VERSION "HNNBNNNYNNNNNNNNNNNNNNNNNNNNNNNNNNNNNNNNNN/4/%%%/4/'%**4NNN///"

NS_ :

BS_:

BU_: BAP_Tester FASFrontradar ICAS1_X_Gateway MFK MFK120 MIK MRR2023 NR_1 NR_2

BO_ 997 TSG_FT_02: 8 ICAS1_X_Gateway
 SG_ TSG_FT_02_CRC : 0|8@1+ (1,0) [0|255] ""  FASFrontradar,MRR2023
 SG_ TSG_FT_02_BZ : 8|4@1+ (1,0) [0|15] ""  FASFrontradar,MRR2023
 SG_ FT_Tuer_Status : 12|2@1+ (1.0,0.0) [0.0|3] ""  FASFrontradar,MFK,MFK120,MIK,MRR2023
 SG_ FT_Tuer_Status_QBit : 14|1@1+ (1.0,0.0) [0.0|1] ""  MFK,MFK120
 SG_ FT_Lock_Taster_02 : 15|1@1+ (1.0,0.0) [0.0|1] ""  Vector__XXX
 SG_ FT_Schluesselschalter_zu_02 : 16|1@1+ (1.0,0.0) [0.0|1] ""  Vector__XXX
 SG_ FT_BFS_Tuer_Status : 17|2@1+ (1.0,0.0) [0.0|3] ""  Vector__XXX
 SG_ FT_HBFS_Tuer_Status : 19|2@1+ (1.0,0.0) [0.0|3] ""  Vector__XXX
 SG_ FT_HFS_Tuer_Status : 21|2@1+ (1.0,0.0) [0.0|3] ""  Vector__XXX
 SG_ FT_Tueroeffnen_Warnung : 23|1@1+ (1.0,0.0) [0.0|1] ""  Vector__XXX
 SG_ FT_SP_Heizung_ein : 24|1@1+ (1.0,0.0) [0.0|1] ""  Vector__XXX
 SG_ FT_Kisi_Taster_li_02 : 25|1@1+ (1.0,0.0) [0.0|1] ""  Vector__XXX
 SG_ FT_Kisi_Taster_re_02 : 26|1@1+ (1.0,0.0) [0.0|1] ""  Vector__XXX
 SG_ FT_TD_Taste_Status : 27|2@1+ (1.0,0.0) [0.0|3] ""  Vector__XXX
 SG_ FT_TCR_Mode_aktiv : 29|1@1+ (1.0,0.0) [0.0|1] ""  Vector__XXX
 SG_ TBF_FS_Touch_Event : 30|4@1+ (1.0,0.0) [0.0|15] ""  Vector__XXX
 SG_ FT_KiSi_Status_Soll_HBFS : 34|1@1+ (1.0,0.0) [0.0|1] ""  Vector__XXX
 SG_ FT_KiSi_Status_Soll_HFS : 35|1@1+ (1.0,0.0) [0.0|1] ""  Vector__XXX
 SG_ FS_Push_Tuergriff : 36|1@1+ (1.0,0.0) [0.0|1] ""  Vector__XXX
 SG_ TSG_FS_Spiegel_angeklappt : 37|1@1+ (1.0,0.0) [0.0|1] ""  Vector__XXX
 SG_ FT_Cargolock_bet : 38|1@1+ (1.0,0.0) [0.0|1] ""  Vector__XXX
 SG_ FT_kisi_asynchron : 40|1@1+ (1.0,0.0) [0.0|1] ""  Vector__XXX
 SG_ FS_Status_eTAG_ext : 42|3@1+ (1.0,0.0) [0.0|7] ""  Vector__XXX
 SG_ FT_ASW_Warnton : 45|2@1+ (1.0,0.0) [0.0|3] ""  Vector__XXX
 SG_ SSA_FT_ASW_Status : 47|2@1+ (1.0,0.0) [0.0|3] ""  Vector__XXX

BO_ 1019 TSK_Ausrollkurve_01: 8 ICAS1_X_Gateway
 SG_ TSK_Ausrollkurve_Schub_Reku_01 m0  : 0|7@1+ (2,0) [0|252] "Unit_KiloMeterPerHour"  FASFrontradar,MRR2023
 SG_ TSK_Ausrollkurve_Schub_Reku_05 m1  : 0|7@1+ (2,0) [0|252] "Unit_KiloMeterPerHour"  FASFrontradar,MRR2023
 SG_ TSK_Ausrollkurve_Schub_Reku_09 m2  : 0|7@1+ (2,0) [0|252] "Unit_KiloMeterPerHour"  FASFrontradar,MRR2023
 SG_ TSK_Ausrollkurve_Schub_Reku_13 m3  : 0|7@1+ (2,0) [0|252] "Unit_KiloMeterPerHour"  FASFrontradar,MRR2023
 SG_ TSK_Ausrollkurve_Schub_Reku_17 m4  : 0|7@1+ (2,0) [0|252] "Unit_KiloMeterPerHour"  FASFrontradar,MRR2023
 SG_ TSK_Ausrollkurve_Schub_Reku_02 m0  : 7|7@1+ (2,0) [0|252] "Unit_KiloMeterPerHour"  FASFrontradar,MRR2023
 SG_ TSK_Ausrollkurve_Schub_Reku_06 m1  : 7|7@1+ (2,0) [0|252] "Unit_KiloMeterPerHour"  FASFrontradar,MRR2023
 SG_ TSK_Ausrollkurve_Schub_Reku_10 m2  : 7|7@1+ (2,0) [0|252] "Unit_KiloMeterPerHour"  FASFrontradar,MRR2023
 SG_ TSK_Ausrollkurve_Schub_Reku_14 m3  : 7|7@1+ (2,0) [0|252] "Unit_KiloMeterPerHour"  FASFrontradar,MRR2023
 SG_ TSK_Ausrollkurve_Schub_Reku_18 m4  : 7|7@1+ (2,0) [0|252] "Unit_KiloMeterPerHour"  FASFrontradar,MRR2023
 SG_ TSK_Ausrollkurve_Schub_Reku_03 m0  : 14|7@1+ (2,0) [0|252] "Unit_KiloMeterPerHour"  FASFrontradar,MRR2023
 SG_ TSK_Ausrollkurve_Schub_Reku_07 m1  : 14|7@1+ (2,0) [0|252] "Unit_KiloMeterPerHour"  FASFrontradar,MRR2023
 SG_ TSK_Ausrollkurve_Schub_Reku_11 m2  : 14|7@1+ (2,0) [0|252] "Unit_KiloMeterPerHour"  FASFrontradar,MRR2023
 SG_ TSK_Ausrollkurve_Schub_Reku_15 m3  : 14|7@1+ (2,0) [0|252] "Unit_KiloMeterPerHour"  FASFrontradar,MRR2023
 SG_ TSK_Ausrollkurve_Schub_Reku_19 m4  : 14|7@1+ (2,0) [0|252] "Unit_KiloMeterPerHour"  FASFrontradar,MRR2023
 SG_ TSK_Ausrollkurve_Schub_Reku_04 m0  : 21|7@1+ (2,0) [0|252] "Unit_KiloMeterPerHour"  FASFrontradar,MRR2023
 SG_ TSK_Ausrollkurve_Schub_Reku_08 m1  : 21|7@1+ (2,0) [0|252] "Unit_KiloMeterPerHour"  FASFrontradar,MRR2023
 SG_ TSK_Ausrollkurve_Schub_Reku_12 m2  : 21|7@1+ (2,0) [0|252] "Unit_KiloMeterPerHour"  FASFrontradar,MRR2023
 SG_ TSK_Ausrollkurve_Schub_Reku_16 m3  : 21|7@1+ (2,0) [0|252] "Unit_KiloMeterPerHour"  FASFrontradar,MRR2023
 SG_ TSK_Ausrollkurve_Schub_Reku_20 m4  : 21|7@1+ (2,0) [0|252] "Unit_KiloMeterPerHour"  FASFrontradar,MRR2023
 SG_ TSK_Ausrollkurve_Segeln_01 m0  : 28|7@1+ (2,0) [0|252] "Unit_KiloMeterPerHour"  FASFrontradar,MRR2023
 SG_ TSK_Ausrollkurve_Segeln_05 m1  : 28|7@1+ (2,0) [0|252] "Unit_KiloMeterPerHour"  FASFrontradar,MRR2023
 SG_ TSK_Ausrollkurve_Segeln_09 m2  : 28|7@1+ (2,0) [0|252] "Unit_KiloMeterPerHour"  FASFrontradar,MRR2023
 SG_ TSK_Ausrollkurve_Segeln_13 m3  : 28|7@1+ (2,0) [0|252] "Unit_KiloMeterPerHour"  FASFrontradar,MRR2023
 SG_ TSK_Ausrollkurve_Segeln_17 m4  : 28|7@1+ (2,0) [0|252] "Unit_KiloMeterPerHour"  FASFrontradar,MRR2023
 SG_ TSK_Ausrollkurve_Segeln_02 m0  : 35|7@1+ (2,0) [0|252] "Unit_KiloMeterPerHour"  FASFrontradar,MRR2023
 SG_ TSK_Ausrollkurve_Segeln_06 m1  : 35|7@1+ (2,0) [0|252] "Unit_KiloMeterPerHour"  FASFrontradar,MRR2023
 SG_ TSK_Ausrollkurve_Segeln_10 m2  : 35|7@1+ (2,0) [0|252] "Unit_KiloMeterPerHour"  FASFrontradar,MRR2023
 SG_ TSK_Ausrollkurve_Segeln_14 m3  : 35|7@1+ (2,0) [0|252] "Unit_KiloMeterPerHour"  FASFrontradar,MRR2023
 SG_ TSK_Ausrollkurve_Segeln_18 m4  : 35|7@1+ (2,0) [0|252] "Unit_KiloMeterPerHour"  FASFrontradar,MRR2023
 SG_ TSK_Ausrollkurve_Segeln_03 m0  : 42|7@1+ (2,0) [0|252] "Unit_KiloMeterPerHour"  FASFrontradar,MRR2023
 SG_ TSK_Ausrollkurve_Segeln_07 m1  : 42|7@1+ (2,0) [0|252] "Unit_KiloMeterPerHour"  FASFrontradar,MRR2023
 SG_ TSK_Ausrollkurve_Segeln_11 m2  : 42|7@1+ (2,0) [0|252] "Unit_KiloMeterPerHour"  FASFrontradar,MRR2023
 SG_ TSK_Ausrollkurve_Segeln_15 m3  : 42|7@1+ (2,0) [0|252] "Unit_KiloMeterPerHour"  FASFrontradar,MRR2023
 SG_ TSK_Ausrollkurve_Segeln_19 m4  : 42|7@1+ (2,0) [0|252] "Unit_KiloMeterPerHour"  FASFrontradar,MRR2023
 SG_ TSK_Ausrollkurve_Segeln_04 m0  : 49|7@1+ (2,0) [0|252] "Unit_KiloMeterPerHour"  FASFrontradar,MRR2023
 SG_ TSK_Ausrollkurve_Segeln_08 m1  : 49|7@1+ (2,0) [0|252] "Unit_KiloMeterPerHour"  FASFrontradar,MRR2023
 SG_ TSK_Ausrollkurve_Segeln_12 m2  : 49|7@1+ (2,0) [0|252] "Unit_KiloMeterPerHour"  FASFrontradar,MRR2023
 SG_ TSK_Ausrollkurve_Segeln_16 m3  : 49|7@1+ (2,0) [0|252] "Unit_KiloMeterPerHour"  FASFrontradar,MRR2023
 SG_ TSK_Ausrollkurve_Segeln_20 m4  : 49|7@1+ (2,0) [0|252] "Unit_KiloMeterPerHour"  FASFrontradar,MRR2023
 SG_ TSK_Ausrollkurve_Mux M  : 56|3@1+ (1,0) [0|7] ""  FASFrontradar,MRR2023
 SG_ TSK_Ausrollkurve_Reku : 59|1@1+ (1.0,0.0) [0.0|1] ""  FASFrontradar,MRR2023
 SG_ TSK_Ausrollkurve_Schrittweite : 60|1@1+ (1.0,0.0) [0.0|1] ""  FASFrontradar,MRR2023
 SG_ TSK_Ausrollkurve_Zaehler : 61|2@1+ (1,0) [0|3] ""  FASFrontradar,MRR2023

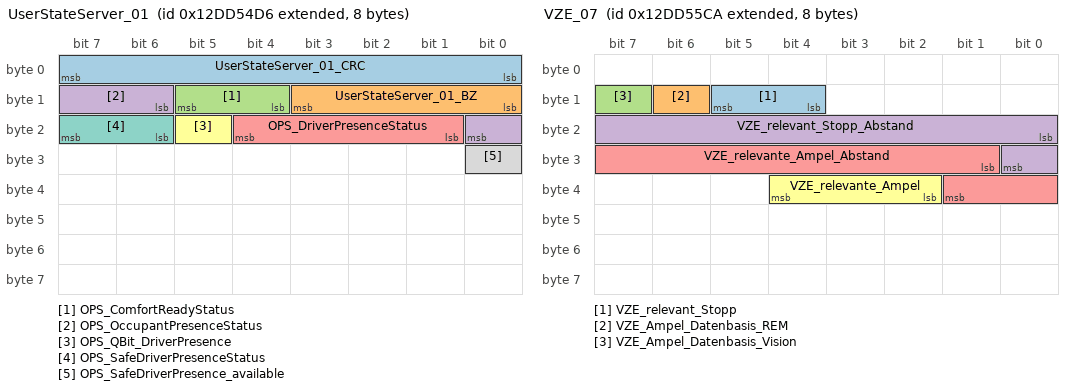
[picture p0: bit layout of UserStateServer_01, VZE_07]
BO_ 2463978710 UserStateServer_01: 8 ICAS1_X_Gateway
 SG_ UserStateServer_01_CRC : 0|8@1+ (1,0) [0|255] ""  Vector__XXX
 SG_ UserStateServer_01_BZ : 8|4@1+ (1,0) [0|15] ""  Vector__XXX
 SG_ OPS_ComfortReadyStatus : 12|2@1+ (1.0,0.0) [0.0|3] ""  Vector__XXX
 SG_ OPS_OccupantPresenceStatus : 14|3@1+ (1.0,0.0) [0.0|7] ""  Vector__XXX
 SG_ OPS_DriverPresenceStatus : 17|4@1+ (1.0,0.0) [0.0|15] ""  MFK,MFK120
 SG_ OPS_QBit_DriverPresence : 21|1@1+ (1.0,0.0) [0.0|1] ""  Vector__XXX
 SG_ OPS_SafeDriverPresenceStatus : 22|2@1+ (1.0,0.0) [0.0|3] ""  MFK,MFK120
 SG_ OPS_SafeDriverPresence_available : 24|1@1+ (1.0,0.0) [0.0|1] ""  Vector__XXX

BO_ 1716 VIN_01: 8 ICAS1_X_Gateway
 SG_ VIN_01_MUX M  : 0|2@1+ (1,0) [0|3] ""  FASFrontradar,MFK,MFK120,MIK,MRR2023
 SG_ KS_Geheimnis_1 m0  : 8|8@1+ (1,0) [0|255] ""  FASFrontradar
 SG_ VIN_4 m1  : 8|8@1+ (1,0) [0|255] ""  FASFrontradar,MFK,MFK120,MIK,MRR2023
 SG_ VIN_11 m2  : 8|8@1+ (1,0) [0|255] ""  FASFrontradar,MFK,MFK120,MIK,MRR2023
 SG_ KS_Geheimnis_2 m0  : 16|8@1+ (1,0) [0|255] ""  FASFrontradar
 SG_ VIN_5 m1  : 16|8@1+ (1,0) [0|255] ""  FASFrontradar,MFK,MFK120,MIK,MRR2023
 SG_ VIN_12 m2  : 16|8@1+ (1,0) [0|255] ""  FASFrontradar,MFK,MFK120,MIK,MRR2023
 SG_ KS_Geheimnis_3 m0  : 24|8@1+ (1,0) [0|255] ""  FASFrontradar
 SG_ VIN_6 m1  : 24|8@1+ (1,0) [0|255] ""  FASFrontradar,MFK,MFK120,MIK,MRR2023
 SG_ VIN_13 m2  : 24|8@1+ (1,0) [0|255] ""  FASFrontradar,MFK,MFK120,MIK,MRR2023
 SG_ KS_Geheimnis_4 m0  : 32|8@1+ (1,0) [0|255] ""  FASFrontradar
 SG_ VIN_7 m1  : 32|8@1+ (1,0) [0|255] ""  FASFrontradar,MFK,MFK120,MIK,MRR2023
 SG_ VIN_14 m2  : 32|8@1+ (1,0) [0|255] ""  FASFrontradar,MFK,MFK120,MIK,MRR2023
 SG_ VIN_1 m0  : 40|8@1+ (1,0) [0|255] ""  FASFrontradar,MFK,MFK120,MIK,MRR2023
 SG_ VIN_8 m1  : 40|8@1+ (1,0) [0|255] ""  FASFrontradar,MFK,MFK120,MIK,MRR2023
 SG_ VIN_15 m2  : 40|8@1+ (1,0) [0|255] ""  FASFrontradar,MFK,MFK120,MIK,MRR2023
 SG_ VIN_2 m0  : 48|8@1+ (1,0) [0|255] ""  FASFrontradar,MFK,MFK120,MIK,MRR2023
 SG_ VIN_9 m1  : 48|8@1+ (1,0) [0|255] ""  FASFrontradar,MFK,MFK120,MIK,MRR2023
 SG_ VIN_16 m2  : 48|8@1+ (1,0) [0|255] ""  FASFrontradar,MFK,MFK120,MIK,MRR2023
 SG_ VIN_3 m0  : 56|8@1+ (1,0) [0|255] ""  FASFrontradar,MFK,MFK120,MIK,MRR2023
 SG_ VIN_10 m1  : 56|8@1+ (1,0) [0|255] ""  FASFrontradar,MFK,MFK120,MIK,MRR2023
 SG_ VIN_17 m2  : 56|8@1+ (1,0) [0|255] ""  FASFrontradar,MFK,MFK120,MIK,MRR2023

BO_ 313 VMM_02_Auth: 32 ICAS1_X_Gateway
 SG_ VMM_02_CRC : 0|8@1+ (1,0) [0|255] ""  FASFrontradar,MRR2023
 SG_ VMM_02_BZ : 8|4@1+ (1,0) [0|15] ""  FASFrontradar,MRR2023
 SG_ VZM_aktiver_Basisservice : 12|3@1+ (1.0,0.0) [0.0|7] ""  FASFrontradar,MFK,MFK120,MRR2023
 SG_ VZM_Anhalteweg_nicht_verfuegbar : 15|1@1+ (1.0,0.0) [0.0|1] ""  FASFrontradar,MRR2023
 SG_ VZM_Fahrer_bremst : 16|1@1+ (1.0,0.0) [0.0|1] ""  FASFrontradar,MFK,MFK120,MRR2023
 SG_ VZM_QBit_Fahrer_bremst : 17|1@1+ (1.0,0.0) [0.0|1] ""  FASFrontradar,MFK,MFK120,MRR2023
 SG_ VMM_MKB_codiert : 18|1@1+ (1.0,0.0) [0.0|1] ""  Vector__XXX
 SG_ VMM_Inkonsistenz_EBKV : 19|1@1+ (1.0,0.0) [0.0|1] ""  Vector__XXX
 SG_ VMM_Notstopp_Status : 20|3@1+ (1.0,0.0) [0.0|7] ""  Vector__XXX
 SG_ VZM_Warnruck_nicht_verfuegbar : 23|1@1+ (1.0,0.0) [0.0|1] ""  FASFrontradar,MFK,MRR2023
 SG_ VZM_Warnruckeln_nicht_verfuegbar : 24|1@1+ (1.0,0.0) [0.0|1] ""  MFK,MFK120
 SG_ VZM_Bkd_nicht_verfuegbar : 25|1@1+ (1.0,0.0) [0.0|1] ""  FASFrontradar,MRR2023
 SG_ VMM_Bremslicht_defekt : 26|1@1+ (1.0,0.0) [0.0|1] ""  FASFrontradar,MRR2023
 SG_ VZM_Fahrer_bremst_deutlich : 27|1@1+ (1.0,0.0) [0.0|1] ""  FASFrontradar,MFK,MFK120,MRR2023
 SG_ VZM_TSK_SRBM_Anf : 28|1@1+ (1.0,0.0) [0.0|1] ""  Vector__XXX
 SG_ VZM_TSK_SRBM_nicht_verfuegbar : 29|1@1+ (1.0,0.0) [0.0|1] ""  Vector__XXX
 SG_ VZM_Verz_Reg_aktiv : 30|5@1+ (1.0,0.0) [0.0|31] ""  MFK,MFK120
 SG_ VZM_Verz_Reg_nicht_verfuegbar : 35|1@1+ (1.0,0.0) [0.0|1] ""  FASFrontradar,MRR2023
 SG_ VMM_Inkonsistenz_KAS : 36|1@1+ (1.0,0.0) [0.0|1] ""  Vector__XXX
 SG_ VMM_Bremslicht_unplausibel : 37|1@1+ (1.0,0.0) [0.0|1] ""  FASFrontradar,MRR2023
 SG_ VMM_Inkonsistenz_ACC : 38|1@1+ (1.0,0.0) [0.0|1] ""  FASFrontradar,MRR2023
 SG_ VMM_Inkonsistenz_AWV_PCF : 39|1@1+ (1.0,0.0) [0.0|1] ""  FASFrontradar,MFK,MRR2023
 SG_ VMM_Inkonsistenz_ARA : 40|1@1+ (1.0,0.0) [0.0|1] ""  Vector__XXX
 SG_ VMM_Inkonsistenz_ParkAssist : 41|1@1+ (1.0,0.0) [0.0|1] ""  Vector__XXX
 SG_ VMM_Inkonsistenz_FAS_VK : 42|1@1+ (1.0,0.0) [0.0|1] ""  Vector__XXX
 SG_ VMM_Inkonsistenz_NV : 43|1@1+ (1.0,0.0) [0.0|1] ""  Vector__XXX
 SG_ VMM_Inkonsistenz_RCTA : 44|1@1+ (1.0,0.0) [0.0|1] ""  Vector__XXX
 SG_ VMM_Inkonsistenz_TSK : 45|1@1+ (1.0,0.0) [0.0|1] ""  Vector__XXX
 SG_ VMM_Inkonsistenz_MO : 46|1@1+ (1.0,0.0) [0.0|1] ""  Vector__XXX
 SG_ VMM_Inkonsistenz_AEB : 47|1@1+ (1.0,0.0) [0.0|1] ""  Vector__XXX
 SG_ VMM_Fahrer_Bremskraft_bestimmend : 48|1@1+ (1.0,0.0) [0.0|1] ""  FASFrontradar,MFK,MFK120,MRR2023
 SG_ VMM_Inkonsistenz_EA : 49|1@1+ (1.0,0.0) [0.0|1] ""  MFK,MFK120
 SG_ VZM_Status_Wegregelung : 50|2@1+ (1.0,0.0) [0.0|3] ""  Vector__XXX
 SG_ VZM_Verz_ASIL_Verfuegbarkeit : 52|3@1+ (1.0,0.0) [0.0|7] ""  FASFrontradar,MFK,MFK120,MRR2023
 SG_ VZM_aktives_System : 55|5@1+ (1.0,0.0) [0.0|31] ""  FASFrontradar,MFK,MFK120,MRR2023
 SG_ VZM_Verz_Begrenzung : 60|1@1+ (1.0,0.0) [0.0|1] ""  FASFrontradar,MRR2023
 SG_ VZM_Systemstatus : 61|3@1+ (1.0,0.0) [0.0|7] ""  FASFrontradar,MRR2023
 SG_ VZM_SRBM_Soll : 64|12@1+ (8,0) [0|32744] "Unit_NewtoMeter"  Vector__XXX
 SG_ VZM_SRBM_Ist : 76|12@1+ (8,0) [0|32744] "Unit_NewtoMeter"  Vector__XXX
 SG_ VZM_SRBM_max_Gradient : 88|7@1+ (50,0) [0|6250] "Unit_NewtoMeterPerSecon"  Vector__XXX
 SG_ VMM_Inkonsistenz_KAM : 95|1@1+ (1.0,0.0) [0.0|1] ""  Vector__XXX
 SG_ VMM_Inkonsistenz_RHP : 96|1@1+ (1.0,0.0) [0.0|1] ""  Vector__XXX
 SG_ VMM_Inkonsistenz_VMC : 97|1@1+ (1.0,0.0) [0.0|1] ""  Vector__XXX
 SG_ HMS_P_beibehalten_GE : 172|2@1+ (1.0,0.0) [0.0|3] ""  Vector__XXX
 SG_ VZM_Unterdrueckung_Antriebsmom : 174|1@1+ (1.0,0.0) [0.0|1] ""  Vector__XXX
 SG_ VMM_Inkonsistenz_VLK : 175|1@1+ (1.0,0.0) [0.0|1] ""  Vector__XXX
 SG_ HMS_halten_nicht_verfuegbar_02 : 176|2@1+ (1.0,0.0) [0.0|3] ""  Vector__XXX
 SG_ HMS_halten_nicht_verfuegbar : 180|1@1+ (1.0,0.0) [0.0|1] ""  FASFrontradar,MRR2023
 SG_ HMS_parken_nicht_verfuegbar : 192|1@1+ (1.0,0.0) [0.0|1] ""  FASFrontradar,MRR2023
 SG_ HMS_Anforderung_GE : 193|3@1+ (1.0,0.0) [0.0|7] ""  Vector__XXX
 SG_ HMS_Systemstatus : 196|4@1+ (1.0,0.0) [0.0|15] ""  FASFrontradar,MFK,MFK120,MRR2023
 SG_ HMS_Stillstand : 200|3@1+ (1.0,0.0) [0.0|7] ""  FASFrontradar,MFK,MFK120,MRR2023
 SG_ HMS_aktives_System : 203|5@1+ (1.0,0.0) [0.0|31] ""  FASFrontradar,MFK,MFK120,MRR2023
 SG_ VMM_Inkonsistenz_GE : 208|1@1+ (1.0,0.0) [0.0|1] ""  Vector__XXX
 SG_ VMM_Inkonsistenz_HVLM : 209|1@1+ (1.0,0.0) [0.0|1] ""  Vector__XXX
 SG_ HMS_Fehlerstatus : 210|3@1+ (1.0,0.0) [0.0|7] ""  FASFrontradar,MRR2023
 SG_ HMS_Index_Haltemoment : 213|1@1+ (1.0,0.0) [0.0|1] ""  Vector__XXX
 SG_ HMS_Haltemoment : 214|10@1+ (10,0) [0|10210] "Unit_NewtoMeter"  Vector__XXX
 SG_ SOK_VMM_02_Signatur : 224|32@1+ (1,0) [0|4294967295] ""  Vector__XXX

BO_ 2463978663 VZE_04: 32 MFK
 SG_ VZE_Anzeigemodus : 0|2@1+ (1.0,0.0) [0.0|3] ""  FASFrontradar,ICAS1_X_Gateway,MRR2023
 SG_ VZE_Hinweistext : 2|3@1+ (1,0) [1|7] ""  FASFrontradar,ICAS1_X_Gateway,MRR2023
 SG_ VZE_Akustik_Limitwechsel : 5|1@1+ (1.0,0.0) [0.0|1] ""  ICAS1_X_Gateway
 SG_ VZE_Modus_OptischeWarnung : 6|1@1+ (1.0,0.0) [0.0|1] ""  ICAS1_X_Gateway
 SG_ VZE_Verkehrszeichen_Einheit : 8|1@1+ (1.0,0.0) [0.0|1] ""  ICAS1_X_Gateway
 SG_ VZE_Anzeigeunterdrueck_Zeichen_3 : 9|1@1+ (1.0,0.0) [0.0|1] ""  ICAS1_X_Gateway
 SG_ VZE_Anzeigeunterdrueck_Zeichen_2 : 10|1@1+ (1.0,0.0) [0.0|1] ""  ICAS1_X_Gateway
 SG_ VZE_Verkehrszeichen_1 : 11|8@1+ (1,0) [1|255] ""  FASFrontradar,ICAS1_X_Gateway,MRR2023
 SG_ VZE_Verkehrszeichen_2 : 19|8@1+ (1,0) [1|255] ""  FASFrontradar,ICAS1_X_Gateway,MRR2023
 SG_ VZE_Verkehrszeichen_3 : 27|8@1+ (1,0) [1|255] ""  FASFrontradar,ICAS1_X_Gateway,MRR2023
 SG_ VZE_Warnung_Verkehrszeichen_1 : 35|1@1+ (1.0,0.0) [0.0|1] ""  FASFrontradar,ICAS1_X_Gateway,MRR2023
 SG_ VZE_Warnung_Verkehrszeichen_2 : 36|1@1+ (1.0,0.0) [0.0|1] ""  FASFrontradar,ICAS1_X_Gateway,MRR2023
 SG_ VZE_Warnung_Verkehrszeichen_3 : 37|1@1+ (1.0,0.0) [0.0|1] ""  FASFrontradar,ICAS1_X_Gateway,MRR2023
 SG_ VZE_Zusatzschild_1 : 38|4@1+ (1,0) [1|15] ""  FASFrontradar,ICAS1_X_Gateway,MRR2023
 SG_ VZE_Zusatzschild_2 : 42|4@1+ (1,0) [1|15] ""  FASFrontradar,ICAS1_X_Gateway,MRR2023
 SG_ VZE_Zusatzschild_3 : 46|4@1+ (1,0) [1|15] ""  FASFrontradar,ICAS1_X_Gateway,MRR2023
 SG_ VZE_Anzeigeunterdrueck_Zeichen_1 : 50|1@1+ (1.0,0.0) [0.0|1] ""  FASFrontradar,ICAS1_X_Gateway,MRR2023
 SG_ VZE_Zeichen_01_KameraWied : 51|1@1+ (1.0,0.0) [0.0|1] ""  FASFrontradar,ICAS1_X_Gateway,MRR2023
 SG_ VZE_Zeichen_02_KameraWied : 52|1@1+ (1.0,0.0) [0.0|1] ""  FASFrontradar,ICAS1_X_Gateway,MRR2023
 SG_ VZE_Zeichen_03_KameraWied : 53|1@1+ (1.0,0.0) [0.0|1] ""  FASFrontradar,ICAS1_X_Gateway,MRR2023
 SG_ VZE_Zeichen_01_Kamera : 54|1@1+ (1.0,0.0) [0.0|1] ""  FASFrontradar,ICAS1_X_Gateway,MRR2023
 SG_ VZE_Zeichen_01_Karte : 55|1@1+ (1.0,0.0) [0.0|1] ""  FASFrontradar,ICAS1_X_Gateway,MRR2023
 SG_ VZE_Zeichen_01_Gesetz : 56|1@1+ (1.0,0.0) [0.0|1] ""  FASFrontradar,ICAS1_X_Gateway,MRR2023
 SG_ VZE_Zeichen_02_Kamera : 57|1@1+ (1.0,0.0) [0.0|1] ""  FASFrontradar,ICAS1_X_Gateway,MRR2023
 SG_ VZE_Zeichen_02_Karte : 58|1@1+ (1.0,0.0) [0.0|1] ""  FASFrontradar,ICAS1_X_Gateway,MRR2023
 SG_ VZE_Zeichen_02_Gesetz : 59|1@1+ (1.0,0.0) [0.0|1] ""  FASFrontradar,ICAS1_X_Gateway,MRR2023
 SG_ VZE_Zeichen_03_Kamera : 60|1@1+ (1.0,0.0) [0.0|1] ""  FASFrontradar,ICAS1_X_Gateway,MRR2023
 SG_ VZE_Zeichen_03_Karte : 61|1@1+ (1.0,0.0) [0.0|1] ""  FASFrontradar,ICAS1_X_Gateway,MRR2023
 SG_ VZE_Zeichen_03_Gesetz : 62|1@1+ (1.0,0.0) [0.0|1] ""  FASFrontradar,ICAS1_X_Gateway,MRR2023
 SG_ VZE_Gong : 63|1@1+ (1.0,0.0) [0.0|1] ""  FASFrontradar,ICAS1_X_Gateway,MRR2023
 SG_ VZE_Akustik_Limitwechsel_Status : 69|1@1+ (1.0,0.0) [0.0|1] ""  ICAS1_X_Gateway
 SG_ VZE_SLWF_Status : 70|2@1+ (1.0,0.0) [0.0|3] ""  ICAS1_X_Gateway
 SG_ VZE_Anzeigeunterdrueck_Zeichen_5 : 72|1@1+ (1.0,0.0) [0.0|1] ""  ICAS1_X_Gateway
 SG_ VZE_Zeichen_05_KameraWied : 73|1@1+ (1.0,0.0) [0.0|1] ""  FASFrontradar,ICAS1_X_Gateway,MRR2023
 SG_ VZE_Zeichen_05_Kamera : 74|1@1+ (1.0,0.0) [0.0|1] ""  FASFrontradar,ICAS1_X_Gateway,MRR2023
 SG_ VZE_Verkehrszeichen_4 : 75|8@1+ (1,0) [1|255] ""  FASFrontradar,ICAS1_X_Gateway,MRR2023
 SG_ VZE_Verkehrszeichen_5 : 83|8@1+ (1,0) [1|255] ""  FASFrontradar,ICAS1_X_Gateway,MRR2023
 SG_ VZE_Anhaenger_Vmax : 91|4@1+ (10,10) [10|140] "Unit_KiloMeterPerHour"  FASFrontradar,ICAS1_X_Gateway,MRR2023
 SG_ VZE_Zeichen_04_Gesetz : 95|1@1+ (1.0,0.0) [0.0|1] ""  ICAS1_X_Gateway
 SG_ VZE_Zeichen_04_Kamera : 96|1@1+ (1.0,0.0) [0.0|1] ""  ICAS1_X_Gateway
 SG_ VZE_Zeichen_04_KameraWied : 97|1@1+ (1.0,0.0) [0.0|1] ""  ICAS1_X_Gateway
 SG_ VZE_Zeichen_04_Karte : 98|1@1+ (1.0,0.0) [0.0|1] ""  ICAS1_X_Gateway
 SG_ VZE_Warnung_Verkehrszeichen_4 : 99|1@1+ (1.0,0.0) [0.0|1] ""  FASFrontradar,ICAS1_X_Gateway,MRR2023
 SG_ VZE_Warnung_Verkehrszeichen_5 : 100|1@1+ (1.0,0.0) [0.0|1] ""  FASFrontradar,ICAS1_X_Gateway,MRR2023
 SG_ VZE_Zeichen_05_Gesetz : 101|1@1+ (1.0,0.0) [0.0|1] ""  ICAS1_X_Gateway
 SG_ VZE_Zusatzschild_4 : 102|4@1+ (1,0) [1|15] ""  FASFrontradar,ICAS1_X_Gateway,MRR2023
 SG_ VZE_Zusatzschild_5 : 106|4@1+ (1,0) [1|15] ""  FASFrontradar,ICAS1_X_Gateway,MRR2023
 SG_ VZE_Baustelle : 110|2@1+ (1.0,0.0) [0.0|3] ""  FASFrontradar,ICAS1_X_Gateway,MRR2023
 SG_ VZE_Zeichen_05_Karte : 112|1@1+ (1.0,0.0) [0.0|1] ""  ICAS1_X_Gateway
 SG_ VZE_Zeichen_05_Entfernung : 113|7@1+ (1,0) [1|127] "Unit_Meter"  FASFrontradar,ICAS1_X_Gateway,MRR2023
 SG_ VZE_Zeichen_05_Entfernung_StdA : 120|7@1+ (1,0) [1|127] "Unit_Meter"  FASFrontradar,ICAS1_X_Gateway,MRR2023
 SG_ VZE_Anzeigeunterdrueck_Zeichen_4 : 127|1@1+ (1.0,0.0) [0.0|1] ""  ICAS1_X_Gateway
 SG_ VZE_Verkehrszeichen_6 : 128|8@1+ (1,0) [1|255] "Unit_None"  FASFrontradar,ICAS1_X_Gateway,MRR2023
 SG_ VZE_Zusatzschild_6 : 136|4@1+ (1,0) [1|15] ""  FASFrontradar,ICAS1_X_Gateway,MRR2023
 SG_ VZE_Zeichen_06_Entfernung : 140|7@1+ (1,0) [1|127] "Unit_Meter"  FASFrontradar,ICAS1_X_Gateway,MRR2023
 SG_ VZE_Zeichen_06_Entfernung_StdA : 147|7@1+ (1,0) [1|127] "Unit_Meter"  FASFrontradar,ICAS1_X_Gateway,MRR2023
 SG_ VZE_Umweltinfo_Naesse : 154|1@1+ (1.0,0.0) [0.0|1] ""  FASFrontradar,ICAS1_X_Gateway,MRR2023
 SG_ VZE_Umweltinfo_Nebel : 155|1@1+ (1.0,0.0) [0.0|1] ""  FASFrontradar,ICAS1_X_Gateway,MRR2023
 SG_ VZE_Umweltinfo_Anhaengerbetrieb : 156|1@1+ (1.0,0.0) [0.0|1] ""  FASFrontradar,ICAS1_X_Gateway,MRR2023
 SG_ VZE_Erweiterte_Information : 157|8@1+ (1,0) [1|255] "Unit_None"  FASFrontradar,ICAS1_X_Gateway,MRR2023
 SG_ VZE_Tempowarnung_Status : 165|1@1+ (1.0,0.0) [0.0|1] ""  FASFrontradar,ICAS1_X_Gateway,MRR2023
 SG_ VZE_Tempowarnung_Einheit : 166|1@1+ (1.0,0.0) [0.0|1] ""  FASFrontradar,ICAS1_X_Gateway,MRR2023
 SG_ VZE_Tempowarnung_Offset : 167|5@1+ (1,0) [1|31] ""  FASFrontradar,ICAS1_X_Gateway,MRR2023
 SG_ VZE_FoD_Status : 206|2@1+ (1.0,0.0) [0.0|3] ""  FASFrontradar,ICAS1_X_Gateway,MRR2023
 SG_ VZE_Anzeige_ZS_1 : 208|4@1+ (1,0) [1|15] "Unit_None"  ICAS1_X_Gateway
 SG_ VZE_Anzeige_ZS_2 : 212|4@1+ (1,0) [1|15] "Unit_None"  ICAS1_X_Gateway
 SG_ VZE_Anzeige_ZS_3 : 216|4@1+ (1,0) [1|15] "Unit_None"  ICAS1_X_Gateway
 SG_ VZE_Hinweistext_03 : 220|4@1+ (1,0) [1|15] ""  ICAS1_X_Gateway
 SG_ VZE_Land : 224|5@1+ (1,0) [1|31] ""  ICAS1_X_Gateway
 SG_ VZE_Warnung_VZ_1 : 229|1@1+ (1.0,0.0) [0.0|1] ""  ICAS1_X_Gateway
 SG_ VZE_Warnung_VZ_2 : 230|1@1+ (1.0,0.0) [0.0|1] ""  ICAS1_X_Gateway
 SG_ VZE_Warnung_VZ_3 : 231|1@1+ (1.0,0.0) [0.0|1] ""  ICAS1_X_Gateway
 SG_ VZE_Anzeige_VZ_1 : 232|8@1+ (1,0) [1|255] ""  ICAS1_X_Gateway
 SG_ VZE_Anzeige_VZ_2 : 240|8@1+ (1,0) [1|255] "Unit_None"  ICAS1_X_Gateway
 SG_ VZE_Anzeige_VZ_3 : 248|8@1+ (1,0) [1|255] "Unit_None"  ICAS1_X_Gateway

BO_ 2589284014 VZE_06: 8 MFK
 SG_ VZE_ISA_Monitoring_Mux M  : 0|4@1+ (1,0) [0|8] "Unit_None"  ICAS1_X_Gateway
 SG_ VZE_ISA_Aktiv_Distanz m0  : 32|32@1+ (1,0) [0|4294967295] "Unit_Meter"  ICAS1_X_Gateway
 SG_ VZE_ISA_Inaktiv_Distanz m1  : 32|32@1+ (1,0) [0|4294967295] "Unit_Meter"  ICAS1_X_Gateway
 SG_ VZE_ISA_Aktiv_Zeit m2  : 32|32@1+ (1,0) [0|4294967295] "Unit_Secon"  ICAS1_X_Gateway
 SG_ VZE_ISA_Inaktiv_Zeit m3  : 32|32@1+ (1,0) [0|4294967295] "Unit_Secon"  ICAS1_X_Gateway
 SG_ VZE_ISA_Limit_beachtet_Distanz m4  : 32|32@1+ (1,0) [0|4294967295] "Unit_Meter"  ICAS1_X_Gateway
 SG_ VZE_ISA_Limit_ueberschr_Distanz m5  : 32|32@1+ (1,0) [0|4294967295] "Unit_Meter"  ICAS1_X_Gateway
 SG_ VZE_ISA_Limit_beachtet_Zeit m6  : 32|32@1+ (1,0) [0|4294967295] "Unit_Secon"  ICAS1_X_Gateway
 SG_ VZE_ISA_Limit_ueberschr_Zeit m7  : 32|32@1+ (1,0) [0|4294967295] "Unit_Secon"  ICAS1_X_Gateway
 SG_ VZE_ISA_Deaktivierung_Anzahl m8  : 32|32@1+ (1,0) [0|4294967295] ""  ICAS1_X_Gateway

BO_ 2463978954 VZE_07: 8 MFK120
 SG_ VZE_relevant_Stopp : 12|2@1+ (1.0,0.0) [0.0|3] ""  MRR2023
 SG_ VZE_Ampel_Datenbasis_REM : 14|1@1+ (1.0,0.0) [0.0|1] ""  MRR2023
 SG_ VZE_Ampel_Datenbasis_Vision : 15|1@1+ (1.0,0.0) [0.0|1] ""  MRR2023
 SG_ VZE_relevant_Stopp_Abstand : 16|9@1+ (1,0) [0|510] "Unit_Meter"  MRR2023
 SG_ VZE_relevante_Ampel_Abstand : 25|9@1+ (1,0) [0|510] "Unit_Meter"  MRR2023
 SG_ VZE_relevante_Ampel : 34|3@1+ (1.0,0.0) [0.0|7] ""  MRR2023

BO_ 1361 WFS_01: 8 ICAS1_X_Gateway
 SG_ WFS_Schluessel_Fahrberecht : 0|4@1+ (1.0,0.0) [0.0|15] ""  MFK
 SG_ WFS_Verbauinfo_ELV : 4|1@1+ (1.0,0.0) [0.0|1] ""  Vector__XXX
 SG_ WFS_ID_Geb_autorisiert : 5|1@1+ (1.0,0.0) [0.0|1] ""  Vector__XXX
 SG_ WFS_ID_Geb_autorisiert_in_Kl15 : 6|1@1+ (1.0,0.0) [0.0|1] ""  Vector__XXX
 SG_ WFS_ID_Geb_steckt : 7|1@1+ (1.0,0.0) [0.0|1] ""  Vector__XXX
 SG_ WFS_Schluessel_Soll : 8|4@1+ (1,0) [0|8] "Unit_None"  Vector__XXX
 SG_ WFS_Schluessel_Ist : 12|4@1+ (1,0) [0|8] "Unit_None"  Vector__XXX
 SG_ WFS_Safe : 16|1@1+ (1.0,0.0) [0.0|1] ""  Vector__XXX
 SG_ WFS_LZ : 17|2@1+ (1.0,0.0) [0.0|3] ""  Vector__XXX
 SG_ WFS_ELV_authorisiert : 19|1@1+ (1.0,0.0) [0.0|1] ""  Vector__XXX
 SG_ WFS_LF_Aktiv : 20|1@1+ (1.0,0.0) [0.0|1] ""  Vector__XXX
 SG_ WFS_Betrieb_Lesespule : 21|1@1+ (1.0,0.0) [0.0|1] ""  Vector__XXX
 SG_ WFS_Klemmenfreigabe : 22|1@1+ (1.0,0.0) [0.0|1] ""  Vector__XXX
 SG_ WFS_Klemmenfreigabe_Signatur : 23|11@1+ (1,0) [0|2047] ""  Vector__XXX
 SG_ WFS_Fahrerhinweise : 34|2@1+ (1.0,0.0) [0.0|3] ""  Vector__XXX
 SG_ WFS_Parken_Status : 36|2@1+ (1.0,0.0) [0.0|3] ""  Vector__XXX
 SG_ WFS_LZ_02 : 38|4@1+ (1.0,0.0) [0.0|15] ""  Vector__XXX

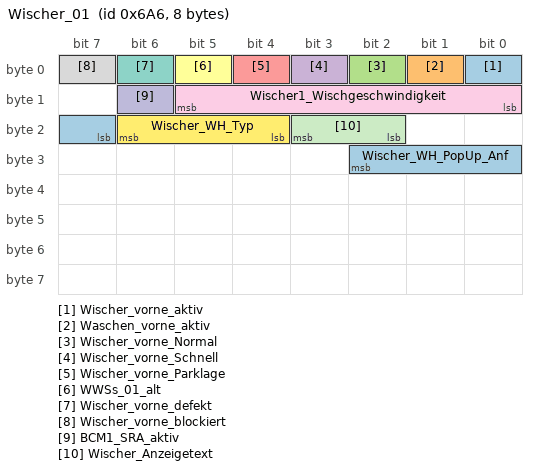
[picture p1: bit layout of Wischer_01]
BO_ 1702 Wischer_01: 8 ICAS1_X_Gateway
 SG_ Wischer_vorne_aktiv : 0|1@1+ (1.0,0.0) [0.0|1] ""  Vector__XXX
 SG_ Waschen_vorne_aktiv : 1|1@1+ (1.0,0.0) [0.0|1] ""  Vector__XXX
 SG_ Wischer_vorne_Normal : 2|1@1+ (1.0,0.0) [0.0|1] ""  Vector__XXX
 SG_ Wischer_vorne_Schnell : 3|1@1+ (1.0,0.0) [0.0|1] ""  Vector__XXX
 SG_ Wischer_vorne_Parklage : 4|1@1+ (1.0,0.0) [0.0|1] ""  Vector__XXX
 SG_ WWSs_01_alt : 5|1@1+ (1.0,0.0) [0.0|1] ""  Vector__XXX
 SG_ Wischer_vorne_defekt : 6|1@1+ (1.0,0.0) [0.0|1] ""  Vector__XXX
 SG_ Wischer_vorne_blockiert : 7|1@1+ (1.0,0.0) [0.0|1] ""  Vector__XXX
 SG_ Wischer1_Wischgeschwindigkeit : 8|6@1+ (1,9) [10|70] "Unit_MinutInver"  MFK120
 SG_ BCM1_SRA_aktiv : 14|1@1+ (1.0,0.0) [0.0|1] ""  Vector__XXX
 SG_ Wischer_Anzeigetext : 18|2@1+ (1.0,0.0) [0.0|3] ""  Vector__XXX
 SG_ Wischer_WH_Typ : 20|3@1+ (1.0,0.0) [0.0|7] ""  Vector__XXX
 SG_ Wischer_WH_PopUp_Anf : 23|4@1+ (1.0,0.0) [0.0|15] ""  Vector__XXX

BO_ 2617163264 XCP_ACC_CRO_01: 8 Vector__XXX
 SG_ XCP_ACC_CRO_01_Data : 0|64@1+ (1.0,0.0) [0.0|18446744073709551615] ""  MRR2023

BO_ 2617163265 XCP_ACC_DTO_01: 8 MRR2023
 SG_ XCP_ACC_DTO_FF_Data : 0|64@1+ (1.0,0.0) [0.0|18446744073709551615] ""  Vector__XXX

BO_ 2617101824 XCP_MIK_CRO_01: 64 Vector__XXX
 SG_ XCP_MIK_CRO_01_Data : 0|512@1+ (1.0,0.0) [0.0|13407807929942597099574024998205846127479365820592393377723561443721764030073546976801874298166903427690031858186486050853753882811946569946433649006084095] ""  MIK

BO_ 2617101825 XCP_MIK_DTO_01: 64 MIK
 SG_ XCP_MIK_DTO_01_Data : 0|512@1+ (1.0,0.0) [0.0|13407807929942597099574024998205846127479365820592393377723561443721764030073546976801874298166903427690031858186486050853753882811946569946433649006084095] ""  Vector__XXX

BO_ 1411 ZV_02: 8 ICAS1_X_Gateway
 SG_ ZV_verriegeln_Anf : 0|1@1+ (1.0,0.0) [0.0|1] ""  Vector__XXX
 SG_ ZV_STSG_HFS_Anf : 1|1@1+ (1.0,0.0) [0.0|1] ""  Vector__XXX
 SG_ ZV_STSG_HBFS_Anf : 2|1@1+ (1.0,0.0) [0.0|1] ""  Vector__XXX
 SG_ ZV_Anf_Challenge_Auth : 3|1@1+ (1.0,0.0) [0.0|1] ""  Vector__XXX
 SG_ ZV_eRWK_Umfeld_Pruefung : 6|1@1+ (1.0,0.0) [0.0|1] ""  Vector__XXX
 SG_ VIP_Sensor_STSG_HFS_betaetigt : 10|1@1+ (1.0,0.0) [0.0|1] ""  Vector__XXX
 SG_ VIP_Sensor_STSG_HBFS_betaetigt : 11|1@1+ (1.0,0.0) [0.0|1] ""  Vector__XXX
 SG_ BCM_FH_Freigabe : 12|1@1+ (1.0,0.0) [0.0|1] ""  Vector__XXX
 SG_ BCM_Komfortfkt_Freigabe : 13|1@1+ (1.0,0.0) [0.0|1] ""  Vector__XXX
 SG_ BCM_HSK_Freigabe : 14|1@1+ (1.0,0.0) [0.0|1] ""  Vector__XXX
 SG_ BCM_Verdeck_Freigabe : 15|1@1+ (1.0,0.0) [0.0|1] ""  Vector__XXX
 SG_ ZV_verriegelt_intern_ist : 16|1@1+ (1.0,0.0) [0.0|1] ""  Vector__XXX
 SG_ ZV_verriegelt_extern_ist : 17|1@1+ (1.0,0.0) [0.0|1] ""  Vector__XXX
 SG_ ZV_verriegelt_intern_soll : 18|1@1+ (1.0,0.0) [0.0|1] ""  Vector__XXX
 SG_ ZV_verriegelt_extern_soll : 19|1@1+ (1.0,0.0) [0.0|1] ""  Vector__XXX
 SG_ ZV_gesafet_extern_ist : 20|1@1+ (1.0,0.0) [0.0|1] ""  Vector__XXX
 SG_ ZV_gesafet_extern_soll : 21|1@1+ (1.0,0.0) [0.0|1] ""  Vector__XXX
 SG_ ZV_Einzeltuerentriegelung : 22|1@1+ (1.0,0.0) [0.0|1] ""  Vector__XXX
 SG_ ZV_Heckeinzelentriegelung : 23|1@1+ (1.0,0.0) [0.0|1] ""  Vector__XXX
 SG_ ZV_FT_offen : 24|1@1+ (1.0,0.0) [0.0|1] ""  Vector__XXX
 SG_ ZV_BT_offen : 25|1@1+ (1.0,0.0) [0.0|1] ""  FASFrontradar,MRR2023
 SG_ ZV_HFS_offen : 26|1@1+ (1.0,0.0) [0.0|1] ""  FASFrontradar,MRR2023
 SG_ ZV_HBFS_offen : 27|1@1+ (1.0,0.0) [0.0|1] ""  FASFrontradar,MRR2023
 SG_ ZV_HD_offen : 28|1@1+ (1.0,0.0) [0.0|1] ""  Vector__XXX
 SG_ ZV_HS_offen : 29|1@1+ (1.0,0.0) [0.0|1] ""  Vector__XXX
 SG_ IRUE_aktiv : 30|1@1+ (1.0,0.0) [0.0|1] ""  Vector__XXX
 SG_ DWA_aktiv : 31|1@1+ (1.0,0.0) [0.0|1] ""  Vector__XXX
 SG_ FFB_HDF_Taste : 34|1@1+ (1.0,0.0) [0.0|1] ""  Vector__XXX
 SG_ FFB_Panik_Taste : 35|1@1+ (1.0,0.0) [0.0|1] ""  Vector__XXX
 SG_ FFB_Auf_Taste : 36|1@1+ (1.0,0.0) [0.0|1] ""  Vector__XXX
 SG_ FFB_Zu_Taste : 37|1@1+ (1.0,0.0) [0.0|1] ""  Vector__XXX
 SG_ FFB_CarFinder : 38|1@1+ (1.0,0.0) [0.0|1] ""  Vector__XXX
 SG_ FFB_Komfortoeffnen : 39|1@1+ (1.0,0.0) [0.0|1] ""  Vector__XXX
 SG_ FFB_Komfortschliessen : 40|1@1+ (1.0,0.0) [0.0|1] ""  Vector__XXX
 SG_ FBS_IDG_in_Reichweite : 41|1@1+ (1.0,0.0) [0.0|1] ""  Vector__XXX
 SG_ ZV_Schluessel_Zugang : 42|4@1+ (1.0,0.0) [0.0|15] ""  MFK,MFK120
 SG_ ZV_SafeFunktion_aktiv : 46|1@1+ (1.0,0.0) [0.0|1] ""  Vector__XXX
 SG_ FBS_Warn_Schluessel_Batt : 47|1@1+ (1.0,0.0) [0.0|1] ""  Vector__XXX
 SG_ ZV_Oeffnungsmodus : 48|2@1+ (1.0,0.0) [0.0|3] ""  Vector__XXX
 SG_ ZV_ist_Zustand_verfuegbar : 54|1@1+ (1.0,0.0) [0.0|1] ""  Vector__XXX
 SG_ IRUE_Taster_Fkts_LED : 55|1@1+ (1.0,0.0) [0.0|1] ""  Vector__XXX
 SG_ ZV_Tankklappe_offen : 56|1@1+ (1.0,0.0) [0.0|1] ""  Vector__XXX
 SG_ ZV_Rollo_auf : 57|1@1+ (1.0,0.0) [0.0|1] ""  Vector__XXX
 SG_ ZV_Rollo_zu : 58|1@1+ (1.0,0.0) [0.0|1] ""  Vector__XXX
 SG_ ZV_SAD_auf : 59|1@1+ (1.0,0.0) [0.0|1] ""  Vector__XXX
 SG_ ZV_SAD_zu : 60|1@1+ (1.0,0.0) [0.0|1] ""  Vector__XXX
 SG_ ZV_verriegelt_soll : 62|2@1+ (1.0,0.0) [0.0|3] ""  Vector__XXX

BO_TX_BU_ 2463978663 :MFK,MFK120;
BO_TX_BU_ 2589284014 :MFK,MFK120;
CM_ BO_ 1716 "200ms bei D4 und folgende";
CM_ BO_ 1702 "MLBevo";

CM_ SG_ 997 FS_Push_Tuergriff "Push zum Ausfahren der Flush-Tuergriffe";
CM_ SG_ 997 FS_Status_eTAG_ext "erweitert um den Wert 'verfährt'";
CM_ SG_ 997 FT_ASW_Warnton "erzeugt ein Warnton bei AS Warnung";
CM_ SG_ 997 FT_BFS_Tuer_Status "Gesammelte Türstatusbotschaft";
CM_ SG_ 997 FT_Cargolock_bet "CargoLock-Taste betätigt";
CM_ SG_ 997 FT_HBFS_Tuer_Status "Türstatus mit Fehler und Initwert";
CM_ SG_ 997 FT_HFS_Tuer_Status "Türstatus mit Fehler und Initwert";
CM_ SG_ 997 FT_kisi_asynchron "Signal erzeugt eine seperate Warnmeldung bei ungewollter Asynchronität der 'elektrische Kindersicherung' der Schlösser.";
CM_ SG_ 997 FT_KiSi_Status_Soll_HBFS "Soll KiSi Status HBFS";
CM_ SG_ 997 FT_KiSi_Status_Soll_HFS "Soll Status der KiSi HFS";
CM_ SG_ 997 FT_Kisi_Taster_li_02 "Der Kindersicherungstaster hinten links aktiv.";
CM_ SG_ 997 FT_Kisi_Taster_re_02 "Der Kindersicherungstaster hinten rechts aktiv.";
CM_ SG_ 997 FT_Lock_Taster_02 "Lock-Taster betätigt";
CM_ SG_ 997 FT_Schluesselschalter_zu_02 "Schlüsselschalter für Schließen betätigt";
CM_ SG_ 997 FT_SP_Heizung_ein "Dieses Signal zeigt die tatsächliche Ansteuerung der  Spiegelheizung incl. PWM an. 
Zudem wird aufgrund des Teilnetzbetriebs das Signal zur Ansteuerung der Beifahrer-Spiegelheizung benutzt.

";
CM_ SG_ 997 FT_TCR_Mode_aktiv "Signal zeigt eine aktive mechanische Redundanz am Türschloss an.";
CM_ SG_ 997 FT_TD_Taste_Status "Status Taste für Tankdeckel";
CM_ SG_ 997 FT_Tuer_Status "Tür geöffnet oder Tür geschlossen";
CM_ SG_ 997 FT_Tuer_Status_QBit "Dieses Bit gibt die Zuverlässigkeit des Türkontakts an. Ein auf dieses Bit folgender Fehlereintrag ist mit dem Sender des Bits abzustimmen (gültig ab PPE).";
CM_ SG_ 997 FT_Tueroeffnen_Warnung "Bit wird gesetzt, wenn Tür während der Fahrt geoeffnet werden soll.";
CM_ SG_ 997 SSA_FT_ASW_Status "SmartSensorActor:
Rückmeldung des Status der ASW Anzeige.";
CM_ SG_ 997 TBF_FS_Touch_Event "Touch_Events für Informationen einer Funktionsauslösung auf dem TBF, welche dann für bspw. ein akustisches Signal zentral umgesetzt werden können.";
CM_ SG_ 997 TSG_FS_Spiegel_angeklappt "Funktionsrückmeldung TSG_FS über Spiegelstellung angeklappt";
CM_ SG_ 997 TSG_FT_02_BZ "4bit Botschaftszaehler, wird mit jeder Sendebotschaft inkrementiert";
CM_ SG_ 997 TSG_FT_02_CRC "Für MLB:
'Berechnung siehe Lastenheft 'Kommunikationsabsicherung für FlexRay und CAN''

Ab MQB und MLBevo:
'Berechnung siehe Lastenheft 'End-to-End Kommunikationsabsicherung''

Endwerte siehe Begleitdokument 'S-PDU Kennungsfolgen'";

CM_ SG_ 1019 TSK_Ausrollkurve_Mux "Dieses Signal dient als Multiplexzähler für die Segel- bzw. Schub-/RekuAusrollkurve";
CM_ SG_ 1019 TSK_Ausrollkurve_Reku "Dieses Signal zeigt an, ob bei der Schub-/Rekuausrollkurve aktuell Rekuperation berücksichtigt wird.";
CM_ SG_ 1019 TSK_Ausrollkurve_Schrittweite "Dieses Signal dient dient zur Umschaltung der Stützstellenschrittweite der Segel- bzw. Schub-/Rekuausrollkurve";
CM_ SG_ 1019 TSK_Ausrollkurve_Schub_Reku_01 "Dieses Signal sendet die Stützstelle 1 der Schub-/Rekuausrollkurve.";
CM_ SG_ 1019 TSK_Ausrollkurve_Schub_Reku_02 "Dieses Signal sendet die Stützstelle 2 der Schub-/Rekuausrollkurve.";
CM_ SG_ 1019 TSK_Ausrollkurve_Schub_Reku_03 "Dieses Signal sendet die Stützstelle 3 der Schub-/Rekuausrollkurve.";
CM_ SG_ 1019 TSK_Ausrollkurve_Schub_Reku_04 "Dieses Signal sendet die Stützstelle 4 der Schub-/Rekuausrollkurve.";
CM_ SG_ 1019 TSK_Ausrollkurve_Schub_Reku_05 "Dieses Signal sendet die Stützstelle 5 der Schub-/Rekuausrollkurve.";
CM_ SG_ 1019 TSK_Ausrollkurve_Schub_Reku_06 "Dieses Signal sendet die Stützstelle 6 der Schub-/Rekuausrollkurve.";
CM_ SG_ 1019 TSK_Ausrollkurve_Schub_Reku_07 "Dieses Signal sendet die Stützstelle 7 der Schub-/Rekuausrollkurve.";
CM_ SG_ 1019 TSK_Ausrollkurve_Schub_Reku_08 "Dieses Signal sendet die Stützstelle 8 der Schub-/Rekuausrollkurve.";
CM_ SG_ 1019 TSK_Ausrollkurve_Schub_Reku_09 "Dieses Signal sendet die Stützstelle 9 der Schub-/Rekuausrollkurve.";
CM_ SG_ 1019 TSK_Ausrollkurve_Schub_Reku_10 "Dieses Signal sendet die Stützstelle 10 der Schub-/Rekuausrollkurve.";
CM_ SG_ 1019 TSK_Ausrollkurve_Schub_Reku_11 "Dieses Signal sendet die Stützstelle 11 der Schub-/Rekuausrollkurve.";
CM_ SG_ 1019 TSK_Ausrollkurve_Schub_Reku_12 "Dieses Signal sendet die Stützstelle 12 der Schub-/Rekuausrollkurve.";
CM_ SG_ 1019 TSK_Ausrollkurve_Schub_Reku_13 "Dieses Signal sendet die Stützstelle 13 der Schub-/Rekuausrollkurve.";
CM_ SG_ 1019 TSK_Ausrollkurve_Schub_Reku_14 "Dieses Signal sendet die Stützstelle 14 der Schub-/Rekuausrollkurve.";
CM_ SG_ 1019 TSK_Ausrollkurve_Schub_Reku_15 "Dieses Signal sendet die Stützstelle 15 der Schub-/Rekuausrollkurve.";
CM_ SG_ 1019 TSK_Ausrollkurve_Schub_Reku_16 "Dieses Signal sendet die Stützstelle 16 der Schub-/Rekuausrollkurve.";
CM_ SG_ 1019 TSK_Ausrollkurve_Schub_Reku_17 "Dieses Signal sendet die Stützstelle 17 der Schub-/Rekuausrollkurve.";
CM_ SG_ 1019 TSK_Ausrollkurve_Schub_Reku_18 "Dieses Signal sendet die Stützstelle 18 der Schub-/Rekuausrollkurve.";
CM_ SG_ 1019 TSK_Ausrollkurve_Schub_Reku_19 "Dieses Signal sendet die Stützstelle 19 der Schub-/Rekuausrollkurve.";
CM_ SG_ 1019 TSK_Ausrollkurve_Schub_Reku_20 "Dieses Signal sendet die Stützstelle 20 der Schub-/Rekuausrollkurve.";
CM_ SG_ 1019 TSK_Ausrollkurve_Segeln_01 "Dieses Signal sendet die Stützstelle 1 der Segelausrollkurve.";
CM_ SG_ 1019 TSK_Ausrollkurve_Segeln_02 "Dieses Signal sendet die Stützstelle 2 der Segelausrollkurve.";
CM_ SG_ 1019 TSK_Ausrollkurve_Segeln_03 "Dieses Signal sendet die Stützstelle 3 der Segelausrollkurve.";
CM_ SG_ 1019 TSK_Ausrollkurve_Segeln_04 "Dieses Signal sendet die Stützstelle 4 der Segelausrollkurve.";
CM_ SG_ 1019 TSK_Ausrollkurve_Segeln_05 "Dieses Signal sendet die Stützstelle 5 der Segelausrollkurve.";
CM_ SG_ 1019 TSK_Ausrollkurve_Segeln_06 "Dieses Signal sendet die Stützstelle 6 der Segelausrollkurve.";
CM_ SG_ 1019 TSK_Ausrollkurve_Segeln_07 "Dieses Signal sendet die Stützstelle 7 der Segelausrollkurve.";
CM_ SG_ 1019 TSK_Ausrollkurve_Segeln_08 "Dieses Signal sendet die Stützstelle 8 der Segelausrollkurve.";
CM_ SG_ 1019 TSK_Ausrollkurve_Segeln_09 "Dieses Signal sendet die Stützstelle 9 der Segelausrollkurve.";
CM_ SG_ 1019 TSK_Ausrollkurve_Segeln_10 "Dieses Signal sendet die Stützstelle 10 der Segelausrollkurve.";
CM_ SG_ 1019 TSK_Ausrollkurve_Segeln_11 "Dieses Signal sendet die Stützstelle 11 der Segelausrollkurve.";
CM_ SG_ 1019 TSK_Ausrollkurve_Segeln_12 "Dieses Signal sendet die Stützstelle 12 der Segelausrollkurve.";
CM_ SG_ 1019 TSK_Ausrollkurve_Segeln_13 "Dieses Signal sendet die Stützstelle 13 der Segelausrollkurve.";
CM_ SG_ 1019 TSK_Ausrollkurve_Segeln_14 "Dieses Signal sendet die Stützstelle 14 der Segelausrollkurve.";
CM_ SG_ 1019 TSK_Ausrollkurve_Segeln_15 "Dieses Signal sendet die Stützstelle 15 der Segelausrollkurve.";
CM_ SG_ 1019 TSK_Ausrollkurve_Segeln_16 "Dieses Signal sendet die Stützstelle 16 der Segelausrollkurve.";
CM_ SG_ 1019 TSK_Ausrollkurve_Segeln_17 "Dieses Signal sendet die Stützstelle 17 der Segelausrollkurve.";
CM_ SG_ 1019 TSK_Ausrollkurve_Segeln_18 "Dieses Signal sendet die Stützstelle 18 der Segelausrollkurve.";
CM_ SG_ 1019 TSK_Ausrollkurve_Segeln_19 "Dieses Signal sendet die Stützstelle 19 der Segelausrollkurve.";
CM_ SG_ 1019 TSK_Ausrollkurve_Segeln_20 "Dieses Signal sendet die Stützstelle 20 der Segelausrollkurve.";
CM_ SG_ 1019 TSK_Ausrollkurve_Zaehler "Dieses Signal ermöglicht die Unterscheidung der Ausrollkurven. Es wird nach der vollständigen Übertragung einer Kennlinie inkrementiert.";

CM_ SG_ 2463978710 OPS_ComfortReadyStatus "Das Signal wird durch den Basisdienst User State Server (Technikvariante: OccupantPresenceService) erzeugt und bildet einen neuen Zustand, bestehend aus einer Verknüpfung der Fahreranwesenheit (Fahrer abwesend / Fahrer anwesend) und der Klemmensteuerung (";
CM_ SG_ 2463978710 OPS_DriverPresenceStatus "Das Signal wird durch den Basisdienst User State Server (Service: OccupantPresenceService) erzeugt und bildet die Fahrerzustände im Fahrzeug ab.";
CM_ SG_ 2463978710 OPS_OccupantPresenceStatus "Das Signal wird durch den Basisdienst User State Server (Service: OccupantPresenceService) erzeugt und bildet die Anwesenheit und Abwesenheit aller Insassen im Fahrzeug ab.";
CM_ SG_ 2463978710 OPS_QBit_DriverPresence "Das Signal wird durch den Basisdienst User State Server (Service: OccupantPresenceService) erzeugt und signalisiert die Qualität der Fahrerzustände.";
CM_ SG_ 2463978710 OPS_SafeDriverPresence_available "Das Signal signalisiert inwiefern alle vorgesehene Sensoren  für die Anwesenheit verwendet werden oder möglichweise bestimmte Sensoren nicht verfügbar sind.
In beiden Fällen wird eine Anwesenheit berechnet, jedoch bei Ausfall bestimmter Sensoren kann zu ";
CM_ SG_ 2463978710 OPS_SafeDriverPresenceStatus "Signalisierung einer sicheren Fahreranwesenheit nach ASIL B";
CM_ SG_ 2463978710 UserStateServer_01_BZ "4bit Botschaftszähler, wird mit jeder Sendebotschaft inkrementiert";
CM_ SG_ 2463978710 UserStateServer_01_CRC "Für MLB:
Berechnung siehe Lastenheft 'Kommunikationsabsicherung für FlexRay und CAN'
Ab MQB und MLBevo:
Berechnung siehe Lastenheft 'End-to-End Kommunikationsabsicherung'

Endwerte siehe Begleitdokument 'S-PDU Kennungsfolgen'";

CM_ SG_ 1716 VIN_01_MUX "Achtung:
Die Botschaft ist nicht linear gemultiplext!!!
Sondern 0,1,0,2,0, usw.";
CM_ SG_ 1716 VIN_1 "Initwert:
0x2D bei Fahrzeugen mit Wegfahrsperrengeneration >= 5 
0x58 bei Fahrzeugen mit Wegfahrsperrengeneration < 5 (z.B. WFS-4)";
CM_ SG_ 1716 VIN_10 "Initwert:
0x2D bei Fahrzeugen mit Wegfahrsperrengeneration >= 5 
0x58 bei Fahrzeugen mit Wegfahrsperrengeneration < 5 (z.B. WFS-4)";
CM_ SG_ 1716 VIN_11 "Initwert:
0x2D bei Fahrzeugen mit Wegfahrsperrengeneration >= 5 
0x58 bei Fahrzeugen mit Wegfahrsperrengeneration < 5 (z.B. WFS-4)";
CM_ SG_ 1716 VIN_12 "Initwert:
0x2D bei Fahrzeugen mit Wegfahrsperrengeneration >= 5 
0x58 bei Fahrzeugen mit Wegfahrsperrengeneration < 5 (z.B. WFS-4)";
CM_ SG_ 1716 VIN_13 "Initwert:
0x2D bei Fahrzeugen mit Wegfahrsperrengeneration >= 5 
0x58 bei Fahrzeugen mit Wegfahrsperrengeneration < 5 (z.B. WFS-4)";
CM_ SG_ 1716 VIN_14 "Initwert:
0x2D bei Fahrzeugen mit Wegfahrsperrengeneration >= 5 
0x58 bei Fahrzeugen mit Wegfahrsperrengeneration < 5 (z.B. WFS-4)";
CM_ SG_ 1716 VIN_15 "Initwert:
0x2D bei Fahrzeugen mit Wegfahrsperrengeneration >= 5 
0x58 bei Fahrzeugen mit Wegfahrsperrengeneration < 5 (z.B. WFS-4)";
CM_ SG_ 1716 VIN_16 "Initwert:
0x2D bei Fahrzeugen mit Wegfahrsperrengeneration >= 5 
0x58 bei Fahrzeugen mit Wegfahrsperrengeneration < 5 (z.B. WFS-4)";
CM_ SG_ 1716 VIN_17 "Initwert:
0x2D bei Fahrzeugen mit Wegfahrsperrengeneration >= 5 
0x58 bei Fahrzeugen mit Wegfahrsperrengeneration < 5 (z.B. WFS-4)";
CM_ SG_ 1716 VIN_2 "Initwert:
0x2D bei Fahrzeugen mit Wegfahrsperrengeneration >= 5 
0x58 bei Fahrzeugen mit Wegfahrsperrengeneration < 5 (z.B. WFS-4)";
CM_ SG_ 1716 VIN_3 "Initwert:
0x2D bei Fahrzeugen mit Wegfahrsperrengeneration >= 5 
0x58 bei Fahrzeugen mit Wegfahrsperrengeneration < 5 (z.B. WFS-4)";
CM_ SG_ 1716 VIN_4 "Initwert:
0x2D bei Fahrzeugen mit Wegfahrsperrengeneration >= 5 
0x58 bei Fahrzeugen mit Wegfahrsperrengeneration < 5 (z.B. WFS-4)";
CM_ SG_ 1716 VIN_5 "Initwert:
0x2D bei Fahrzeugen mit Wegfahrsperrengeneration >= 5 
0x58 bei Fahrzeugen mit Wegfahrsperrengeneration < 5 (z.B. WFS-4)";
CM_ SG_ 1716 VIN_6 "Initwert:
0x2D bei Fahrzeugen mit Wegfahrsperrengeneration >= 5 
0x58 bei Fahrzeugen mit Wegfahrsperrengeneration < 5 (z.B. WFS-4)";
CM_ SG_ 1716 VIN_7 "Initwert:
0x2D bei Fahrzeugen mit Wegfahrsperrengeneration >= 5 
0x58 bei Fahrzeugen mit Wegfahrsperrengeneration < 5 (z.B. WFS-4)";
CM_ SG_ 1716 VIN_8 "Initwert:
0x2D bei Fahrzeugen mit Wegfahrsperrengeneration >= 5 
0x58 bei Fahrzeugen mit Wegfahrsperrengeneration < 5 (z.B. WFS-4)";
CM_ SG_ 1716 VIN_9 "Initwert:
0x2D bei Fahrzeugen mit Wegfahrsperrengeneration >= 5 
0x58 bei Fahrzeugen mit Wegfahrsperrengeneration < 5 (z.B. WFS-4)";

CM_ SG_ 313 HMS_aktives_System "Zeigt an, von welchem System die Anforderung gerade umgesetzt wird.";
CM_ SG_ 313 HMS_Anforderung_GE "Fordert vom Getriebe bestimmte Schaltstellungen an.";
CM_ SG_ 313 HMS_Fehlerstatus "Zeigt den Fehlerstatus des Haltemanagementsystems HMS an.
Details zu den Werten 3/4:
3=Systemeinschränkung, Parken EPB oder GSG nicht möglich
4=Systemstörung bzw. Parken EPB und GSG nicht möglich  ";
CM_ SG_ 313 HMS_Haltemoment "Zeigt in Abhängigkeit von HMS_Index_Haltemoment das notwendige Summen-Radmoment an (bergab: Bremsmoment; bergauf: Antriebsmoment), das mindestens notwendig ist um das Fahrzeug an der aktuellen Neigung zu halten.";
CM_ SG_ 313 HMS_halten_nicht_verfuegbar "Rueckmeldung HMS-Teilfunktion 'Halten' nicht verfuegbar.";
CM_ SG_ 313 HMS_halten_nicht_verfuegbar_02 "Erweiterung des Signals 'HMS_halten_nicht_verfuegbar':
Für Remotevorgänge (Ein-, Ausparken, etc.) ohne anwesenden Fahrer soll das Signal eine Halteverfügbarkeit signalisieren durch 'verfuegbar_ohne_Fahrer'.";
CM_ SG_ 313 HMS_Index_Haltemoment "Zeigt an, ob das Summen-HMS_Haltemoment ein Bremsmoment (bergab) oder ein Antriebsmoment (bergauf) darstellt.";
CM_ SG_ 313 HMS_P_beibehalten_GE "Fordert das Getriebe auf in Stellung 'P' zu bleiben.";
CM_ SG_ 313 HMS_parken_nicht_verfuegbar "Rueckmeldung HMS-Teilfunktionen 'Parken' nicht verfuegbar.";
CM_ SG_ 313 HMS_Stillstand "Das Signal zeigt, basierend auf den vier ESP-Raddrehzahlinformatioen, gefiltert und/oder entprellt mehrstufig den Fahrzeuggeschwindigkeitszustand an.";
CM_ SG_ 313 HMS_Systemstatus "Zeigt den aktuellen Systemstatus des HMS an.";
CM_ SG_ 313 SOK_VMM_02_Signatur "Signatur im Rahmen der durch SOK geschützten Broadcast-Kommunikation

Geschützte Funktionen: Airbag-Funktionen, Bremsfunktionen
Geschützte Botschaft: VMM_02";
CM_ SG_ 313 VMM_02_BZ "4bit Botschaftszähler, wird mit jeder Sendebotschaft inkrementiert";
CM_ SG_ 313 VMM_02_CRC "Für MLB:
Berechnung siehe Lastenheft 'Kommunikationsabsicherung für FlexRay und CAN'
Ab MQB und MLBevo:
Berechnung siehe Lastenheft 'End-to-End Kommunikationsabsicherung'

Endwerte siehe Begleitdokument 'S-PDU Kennungsfolgen'";
CM_ SG_ 313 VMM_Bremslicht_defekt "Rückmeldung ob beide Bremslichter defekt sind. Bei gestecktem Anhänger werden die Anhängerbremslichter ausgewertet.";
CM_ SG_ 313 VMM_Bremslicht_unplausibel "Bremslichtplausibilität aus Basis der CAN Anforderung";
CM_ SG_ 313 VMM_Fahrer_Bremskraft_bestimmend "Dieses Signal gibt eine Rückmeldung ob der Fahrer stärker bremst als die angeforderte Bremsung.";
CM_ SG_ 313 VMM_Inkonsistenz_ACC "Rückmeldung Inkonsistenz ACC";
CM_ SG_ 313 VMM_Inkonsistenz_AEB "Rückmeldung Inkonsistenz vom AEB";
CM_ SG_ 313 VMM_Inkonsistenz_ARA "Rückmeldung Inkonsistenz ARA 1.0";
CM_ SG_ 313 VMM_Inkonsistenz_AWV_PCF "Rückmeldung Inkonsistenz AWV PCF";
CM_ SG_ 313 VMM_Inkonsistenz_EA "Rückmeldung Inkonsistenz EA";
CM_ SG_ 313 VMM_Inkonsistenz_EBKV "Rückmeldung Inkonsistenz EBKV";
CM_ SG_ 313 VMM_Inkonsistenz_FAS_VK "Rückmeldung Inkonsistenz Fahrerassistenzsystem";
CM_ SG_ 313 VMM_Inkonsistenz_GE "Zeigt an, ob die Kommunikation und die Anforderungen plausibel sind.";
CM_ SG_ 313 VMM_Inkonsistenz_HVLM "Rückmeldung Inkonsistenz HVLM";
CM_ SG_ 313 VMM_Inkonsistenz_KAM "Rückmeldung Inkonsistenz der Kamera";
CM_ SG_ 313 VMM_Inkonsistenz_KAS "Rückmeldung Inkonsistenz KAS";
CM_ SG_ 313 VMM_Inkonsistenz_MO "Rückmeldung Inkonsistenz MO";
CM_ SG_ 313 VMM_Inkonsistenz_NV "Rückmeldung Inkonsistenz Nightvision";
CM_ SG_ 313 VMM_Inkonsistenz_ParkAssist "Rückmeldung Inkonsistenz der Parkenden Systeme";
CM_ SG_ 313 VMM_Inkonsistenz_RCTA "Rückmeldung Inkonsistenz des RCTA";
CM_ SG_ 313 VMM_Inkonsistenz_RHP "Rückmeldung Inkonsistenz RHP (Rush Hour pilot).";
CM_ SG_ 313 VMM_Inkonsistenz_TSK "Rückmeldung Inkonsistenz TSK";
CM_ SG_ 313 VMM_Inkonsistenz_VLK "Rückmeldung Inkonsistenz VLK";
CM_ SG_ 313 VMM_Inkonsistenz_VMC "Rückmeldung Inkonsistenz VMC Prim";
CM_ SG_ 313 VMM_MKB_codiert "Das Signal kennzeichnet den Codierstatus des ESC-SG bzgl. der Funktion Multikollisionsbremse.";
CM_ SG_ 313 VMM_Notstopp_Status "Status des Notstoppsystems";
CM_ SG_ 313 VZM_aktiver_Basisservice "In diesem Signal wird der aktive Basisservice des Verzögerungsmanagement zurück gegeben.";
CM_ SG_ 313 VZM_aktives_System "Rückmeldung über das  aktiv anfordernde System bei dem Verzögerungsmanagement.";
CM_ SG_ 313 VZM_Anhalteweg_nicht_verfuegbar "Rückmeldung ob die Anhaltewegregelung verfügbar ist.";
CM_ SG_ 313 VZM_Bkd_nicht_verfuegbar "Dieses Signal gibt eine Rückmeldung ob eine Bremsenkonditionierung (Prefill und Systemtotzeitminimierung) verfügbar ist.";
CM_ SG_ 313 VZM_Fahrer_bremst "Bit wird gesetzt beim Überschreiten der Bremsdruckschwelle

Weiterführende Informationen im Lastenheft spezifiziert und in der entsprechenden Fachabteilung zu erfragen.";
CM_ SG_ 313 VZM_Fahrer_bremst_deutlich "Rückmeldung an AWV ob der Fahrer das Bremspedal deutlich betätigt hat";
CM_ SG_ 313 VZM_QBit_Fahrer_bremst "Gültigkeit der Bremsdruckschwelleninformation des Signals VZM_Fahrer_bremst und VZM_Fahrer_bremst_deutlich
0x1 = Druckschwelleninformation kann noch nicht oder aufgrund eines Fehlers nicht ausgegeben werden";
CM_ SG_ 313 VZM_SRBM_Ist "Gibt das aktuelle Summenradbremsmoment aus.";
CM_ SG_ 313 VZM_SRBM_max_Gradient "Rückmeldung aktueller Maximalgradient";
CM_ SG_ 313 VZM_SRBM_Soll "Gibt das angeforderte Summenradbremsmoment aus.";
CM_ SG_ 313 VZM_Status_Wegregelung "Rückmeldung der Wegregelung ob dieser Service Inaktiv, aktiv oder passiv ist.
Bei Passiv_Überwachend Bremseingriff durch VZM im Notfall möglich.";
CM_ SG_ 313 VZM_Systemstatus "In diesem Signal wird der aktuelle Systemstatus des Verzögerungsmanagments ausgeben.";
CM_ SG_ 313 VZM_TSK_SRBM_Anf "Quittierung für TSK (SRBM = Summenradbremsmoment) Anforderung";
CM_ SG_ 313 VZM_TSK_SRBM_nicht_verfuegbar "Rückmeldung ob das ein Summenradbremsmoment angefordert werden kann.";
CM_ SG_ 313 VZM_Unterdrueckung_Antriebsmom "Mit diesem Signal wird dem TSK signalisiert ob ein positives Antriebsmoment angefordert werden kann. In einer Notbremsung ist das positive Antriebsmoment zu unterdrücken.";
CM_ SG_ 313 VZM_Verz_ASIL_Verfuegbarkeit "Dieses Signal gibt die Rückmeldung in welchem ASIL Bereich aktuell verzögert wird.";
CM_ SG_ 313 VZM_Verz_Begrenzung "Rückmeldung angeforderte Verzögerung oder Summenradbremsmoment wird begrenzt umgesetzt";
CM_ SG_ 313 VZM_Verz_Reg_aktiv "Rueckmeldung Verzoegerungsregelung aktiv";
CM_ SG_ 313 VZM_Verz_Reg_nicht_verfuegbar "In diesem Signal wird ausgegeben ob eine Verzögerungsregelung verfügbar ist.";
CM_ SG_ 313 VZM_Warnruck_nicht_verfuegbar "Rückmeldung ob ein einfacher Warnruck angefordert werden kann.";
CM_ SG_ 313 VZM_Warnruckeln_nicht_verfuegbar "Rückmeldung ob mehrfach ein Warnruck durchgeführt werden kann.";

CM_ SG_ 2463978663 VZE_Akustik_Limitwechsel "Anforderung eines Signaltons bei Tempolimitwechsel.";
CM_ SG_ 2463978663 VZE_Akustik_Limitwechsel_Status "Das Signal überträgt die Information, ob der Kunde, in den Einstellungen, die akustische Information, bei einem Tempolimitwechsel, ausgewählt hat.";
CM_ SG_ 2463978663 VZE_Anhaenger_Vmax "Übertragung der aus Kundeneinstellung und länderspezifischen Regelungen (StVO, Rechtsprechung...) berechneten legalen Höchstgeschwindigkeit für das Gespann.

10+ 0*10 = 10 km/h
10+ 1*10 = 20 km/h
...
10+ 5*10 = 60 km/h
10+ 6*10 = 70 km/h
...
10+ 1";
CM_ SG_ 2463978663 VZE_Anzeige_VZ_1 "Das Signal spiegelt eines der Verkehrszeichen: Geschwindigkeitsgebot, Überholverbot, Aufhebungszeichen wider.

Wertebereich lt. Hashtabelle";
CM_ SG_ 2463978663 VZE_Anzeige_VZ_2 "Das Signal spiegelt eines der Verkehrszeichen: Geschwindigkeitsgebot, Überholverbot, Aufhebungszeichen wider.

Wertebereich lt. Hashtabelle";
CM_ SG_ 2463978663 VZE_Anzeige_VZ_3 "Das Signal spiegelt eines der Verkehrszeichen: Geschwindigkeitsgebot, Überholverbot, Aufhebungszeichen wider.

Wertebereich lt. Hashtabelle";
CM_ SG_ 2463978663 VZE_Anzeige_ZS_1 "Zusatzsschild, das zu Verkehrszeichen 1 angezeigt werden soll.

Wertebereich lt. Hashtabelle";
CM_ SG_ 2463978663 VZE_Anzeige_ZS_2 "Zusatzsschild, das zu Verkehrszeichen 1 angezeigt werden soll.

Wertebereich lt. Hashtabelle";
CM_ SG_ 2463978663 VZE_Anzeige_ZS_3 "Zusatzsschild, das zu Verkehrszeichen 1 angezeigt werden soll.

Wertebereich lt. Hashtabelle";
CM_ SG_ 2463978663 VZE_Anzeigemodus "Steuert die verschiedenen Möglichkeiten der Anzeige.";
CM_ SG_ 2463978663 VZE_Anzeigeunterdrueck_Zeichen_1 "Steuerungssignal zur Steuerung der Sichtbarkeit von Verkehrszeichen ";
CM_ SG_ 2463978663 VZE_Anzeigeunterdrueck_Zeichen_2 "Anzeigerelevanz des Zeichens in VZE_Verkehrszeichen_2";
CM_ SG_ 2463978663 VZE_Anzeigeunterdrueck_Zeichen_3 "Anzeigerelevanz des Zeichens in VZE_Verkehrszeichen_3";
CM_ SG_ 2463978663 VZE_Anzeigeunterdrueck_Zeichen_4 "Anzeigerelevanz des Zeichens in VZE_Anzeigerelevanz_Zeichen_4";
CM_ SG_ 2463978663 VZE_Anzeigeunterdrueck_Zeichen_5 "Anzeigerelevanz des Zeichens in VZE_Anzeigerelevanz_Zeichen_5";
CM_ SG_ 2463978663 VZE_Baustelle "Das Signal gibt an, ob aktuell ein Baustellenschild von der VZE erkannt wurde.";
CM_ SG_ 2463978663 VZE_Erweiterte_Information "In dem Signal spiegelt erweiterte Verkehrszeicheninformationen wieder (Ortsschild, Autobahnbeginn, Autobahnende)

Wertebereich lt. Hashtabelle";
CM_ SG_ 2463978663 VZE_FoD_Status "Status der VZE für FoD";
CM_ SG_ 2463978663 VZE_Gong "Das Signal signalisiert dem Kombiinstrument ob bei der VZE-Tempowarnung ein Gong getriggert werden soll.";
CM_ SG_ 2463978663 VZE_Hinweistext "Über Index wird ein Hinweistext beschrieben, der durch das Kombi dargestellte werden soll.

Wertebereich lt. Hashtabelle";
CM_ SG_ 2463978663 VZE_Hinweistext_03 "Über Index wird ein Hinweistext beschrieben, der durch das Kombi dargestellte werden soll.

Wertebereich lt. Hashtabelle";
CM_ SG_ 2463978663 VZE_Land "Steuert die verschiedenen Möglichkeiten der Anzeige.";
CM_ SG_ 2463978663 VZE_Modus_OptischeWarnung "Das Signal gibt an, ob eine optische Warnung blinkend oder dauerhaft ausgegeben werden soll.";
CM_ SG_ 2463978663 VZE_SLWF_Status "Das Signal zeigt den SLWF Zustand der VZE an.";
CM_ SG_ 2463978663 VZE_Tempowarnung_Einheit "0 - Einheit Warnoffset km/h
1 -  Einheit Warnoffset mph";
CM_ SG_ 2463978663 VZE_Tempowarnung_Offset "das Signal überträgt den im CAR:Menü gewählten Offset für die VZE-Tempowarnung an das pACC Steuergerät. Die zugrhörige Einheit wird im Signal VZE_Tempowarnung_Einheit übertragen";
CM_ SG_ 2463978663 VZE_Tempowarnung_Status "0 - Tempowarnung aktiv
1 -  Tempowarnung desktiv";
CM_ SG_ 2463978663 VZE_Umweltinfo_Anhaengerbetrieb "In dem Signal werden für die Verkehrszeichenerkennung relevante Umweltinformationen übertragen.

Info: Anhängerbetrieb";
CM_ SG_ 2463978663 VZE_Umweltinfo_Naesse "In dem Signal werden für die Verkehrszeichenerkennung relevante Umweltinformationen übertragen.

Info: Nässe";
CM_ SG_ 2463978663 VZE_Umweltinfo_Nebel "In dem Signal werden für die Verkehrszeichenerkennung relevante Umweltinformationen übertragen.

Info: Nebel";
CM_ SG_ 2463978663 VZE_Verkehrszeichen_1 "Das Signal spiegelt eines der Verkehrszeichen: Geschwindigkeitsgebot, Überholverbot, Aufhebungszeichen wider.

Wertebereich lt. Hashtabelle";
CM_ SG_ 2463978663 VZE_Verkehrszeichen_2 "Das Signal spiegelt eines der Verkehrszeichen: Geschwindigkeitsgebot, Überholverbot, Aufhebungszeichen wider.

Wertebereich lt. Hashtabelle";
CM_ SG_ 2463978663 VZE_Verkehrszeichen_3 "Das Signal spiegelt eines der Verkehrszeichen: Geschwindigkeitsgebot, Überholverbot, Aufhebungszeichen wider.

Wertebereich lt. Hashtabelle";
CM_ SG_ 2463978663 VZE_Verkehrszeichen_4 "Das Signal spiegelt eines der Verkehrszeichen: Geschwindigkeitsgebot, Überholverbot, Aufhebungszeichen wider.

Wertebereich lt. Hashtabelle";
CM_ SG_ 2463978663 VZE_Verkehrszeichen_5 "Das Signal spiegelt eines der Verkehrszeichen: Geschwindigkeitsgebot, Überholverbot, Aufhebungszeichen wider.

Wertebereich lt. Hashtabelle";
CM_ SG_ 2463978663 VZE_Verkehrszeichen_6 "Das Signal spiegelt eines der Verkehrszeichen: Geschwindigkeitsgebot, Überholverbot, Aufhebungszeichen wider.

Wertebereich lt. Hashtabelle";
CM_ SG_ 2463978663 VZE_Verkehrszeichen_Einheit "Signal gibt an ob das übertragene Verkehrszeichen in mph oder km/h übermittelt wird";
CM_ SG_ 2463978663 VZE_Warnung_Verkehrszeichen_1 "Ist das Signal gesetzt, so ist für das Verkehrszeichen 1 eine Warnung auszugeben.";
CM_ SG_ 2463978663 VZE_Warnung_Verkehrszeichen_2 "Ist das Signal gesetzt, so ist für das Verkehrszeichen 2 eine Warnung auszugeben.";
CM_ SG_ 2463978663 VZE_Warnung_Verkehrszeichen_3 "Ist das Signal gesetzt, so ist für das Verkehrszeichen 3 eine Warnung auszugeben.";
CM_ SG_ 2463978663 VZE_Warnung_Verkehrszeichen_4 "Ist das Signal gesetzt, so ist für das Verkehrszeichen 4 eine Warnung auszugeben.";
CM_ SG_ 2463978663 VZE_Warnung_Verkehrszeichen_5 "Ist das Signal gesetzt, so ist für das Verkehrszeichen 5 eine Warnung auszugeben.";
CM_ SG_ 2463978663 VZE_Warnung_VZ_1 "Ist das Signal gesetzt, so ist für das Verkehrszeichen 1 eine Warnung auszugeben.";
CM_ SG_ 2463978663 VZE_Warnung_VZ_2 "Ist das Signal gesetzt, so ist für das Verkehrszeichen 1 eine Warnung auszugeben.";
CM_ SG_ 2463978663 VZE_Warnung_VZ_3 "Ist das Signal gesetzt, so ist für das Verkehrszeichen 1 eine Warnung auszugeben.";
CM_ SG_ 2463978663 VZE_Zeichen_01_Gesetz "Das VZE-Tempolimit in Verkehrszeichen1  ist das gesetzlich geltende Tempolimit (je Land/Straßenklasse).";
CM_ SG_ 2463978663 VZE_Zeichen_01_Kamera "Das VZE-Tempolimit in Verkehrszeichen1 wurde von der Kamera erkannt.";
CM_ SG_ 2463978663 VZE_Zeichen_01_KameraWied "Das VZE-Tempolimit  in Verkehrszeichen1 wurde als Wiederholungsschild von der Kamera erkannt.";
CM_ SG_ 2463978663 VZE_Zeichen_01_Karte "Das VZE-Tempolimit in Verkehrszeichen1 stammt aus den Navigationskartendaten.";
CM_ SG_ 2463978663 VZE_Zeichen_02_Gesetz "Das VZE-Tempolimit in Verkehrszeichen2  ist das gesetzlich geltende Tempolimit (je Land/Straßenklasse).";
CM_ SG_ 2463978663 VZE_Zeichen_02_Kamera "Das VZE-Tempolimit in Verkehrszeichen2 wurde von der Kamera erkannt.";
CM_ SG_ 2463978663 VZE_Zeichen_02_KameraWied "Das VZE-Tempolimit  in Verkehrszeichen2 wurde als Wiederholungsschild von der Kamera erkannt.";
CM_ SG_ 2463978663 VZE_Zeichen_02_Karte "Das VZE-Tempolimit in Verkehrszeichen2 stammt aus den Navigationskartendaten.";
CM_ SG_ 2463978663 VZE_Zeichen_03_Gesetz "Das VZE-Tempolimit in Verkehrszeichen3  ist das gesetzlich geltende Tempolimit (je Land/Straßenklasse).";
CM_ SG_ 2463978663 VZE_Zeichen_03_Kamera "Das VZE-Tempolimit in Verkehrszeichen3 wurde von der Kamera erkannt.";
CM_ SG_ 2463978663 VZE_Zeichen_03_KameraWied "Das VZE-Tempolimit  in Verkehrszeichen3 wurde als Wiederholungsschild von der Kamera erkannt.";
CM_ SG_ 2463978663 VZE_Zeichen_03_Karte "Das VZE-Tempolimit in Verkehrszeichen3 stammt aus den Navigationskartendaten.";
CM_ SG_ 2463978663 VZE_Zeichen_04_Gesetz "Das VZE-Tempolimit ist das gesetzlich geltende Tempolimit (je Land/Straßenklasse).";
CM_ SG_ 2463978663 VZE_Zeichen_04_Kamera "Das VZE-Tempolimit wurde von der Kamera erkannt.";
CM_ SG_ 2463978663 VZE_Zeichen_04_KameraWied "Das VZE-Tempolimit wurde als Wiederholungsschild von der Kamera erkannt.";
CM_ SG_ 2463978663 VZE_Zeichen_04_Karte "Das VZE-Tempolimit stammt aus den Navigationskartendaten.";
CM_ SG_ 2463978663 VZE_Zeichen_05_Entfernung "In dem Signal wird die Entfernung zum Verkehrszeichen5 übertragen";
CM_ SG_ 2463978663 VZE_Zeichen_05_Entfernung_StdA "In dem Signal wird die Standardabweichung bzgl. der Entfernung zum Verkehrszeichen5 übertragen ";
CM_ SG_ 2463978663 VZE_Zeichen_05_Gesetz "Das VZE-Tempolimit ist das gesetzlich geltende Tempolimit (je Land/Straßenklasse).";
CM_ SG_ 2463978663 VZE_Zeichen_05_Kamera "Das VZE-Tempolimit wurde von der Kamera erkannt.";
CM_ SG_ 2463978663 VZE_Zeichen_05_KameraWied "Das VZE-Tempolimit wurde als Wiederholungsschild von der Kamera erkannt.";
CM_ SG_ 2463978663 VZE_Zeichen_05_Karte "Das VZE-Tempolimit stammt aus den Navigationskartendaten.";
CM_ SG_ 2463978663 VZE_Zeichen_06_Entfernung "In dem Signal wird die Entfernung zum Verkehrszeichen6 übertragen";
CM_ SG_ 2463978663 VZE_Zeichen_06_Entfernung_StdA "In dem Signal wird die Standardabweichung bzgl. der Entfernung zum Verkehrszeichen6 übertragen ";
CM_ SG_ 2463978663 VZE_Zusatzschild_1 "Zusatzsschild, das zu Verkehrszeichen 1 angezeigt werden soll.

Wertebereich lt. Hashtabelle";
CM_ SG_ 2463978663 VZE_Zusatzschild_2 "Zusatzsschild, das zu Verkehrszeichen 2 angezeigt werden soll.

Wertebereich lt. Hashtabelle";
CM_ SG_ 2463978663 VZE_Zusatzschild_3 "Zusatzsschild, das zu Verkehrszeichen 3 angezeigt werden soll.

Wertebereich lt. Hashtabelle";
CM_ SG_ 2463978663 VZE_Zusatzschild_4 "Zusatzsschild, das zu Verkehrszeichen 4 angezeigt werden soll.

Wertebereich lt. Hashtabelle";
CM_ SG_ 2463978663 VZE_Zusatzschild_5 "Zusatzsschild, das zu Verkehrszeichen 5 angezeigt werden soll.

Wertebereich lt. Hashtabelle";
CM_ SG_ 2463978663 VZE_Zusatzschild_6 "Zusatzsschild, das zu Verkehrszeichen 6 angezeigt werden soll.

Wertebereich lt. Hashtabelle";

CM_ SG_ 2589284014 VZE_ISA_Aktiv_Distanz "Signal zur Uebertragung der mit im Sinne der GSR (General Safety Regulation) aktiver ISA Funktion gefahrenen Distanz in Meter";
CM_ SG_ 2589284014 VZE_ISA_Aktiv_Zeit "Signal zur Uebertragung der mit im Sinne der GSR (General Safety Regulation) aktiver ISA Funktion gefahrenen Zeit in Sekunden";
CM_ SG_ 2589284014 VZE_ISA_Deaktivierung_Anzahl "Signal zur Uebertragung der Anzahl der ISA Deaktivierungen im Sinne der GSR (General Safety Regulation)";
CM_ SG_ 2589284014 VZE_ISA_Inaktiv_Distanz "Signal zur Uebertragung der mit im Sinne der GSR (General Safety Regulation) inaktiver ISA Funktion gefahrenen Distanz in Meter";
CM_ SG_ 2589284014 VZE_ISA_Inaktiv_Zeit "Signal zur Uebertragung der mit im Sinne der GSR (General Safety Regulation) inaktiver ISA Funktion gefahrenen Zeit in Sekunden";
CM_ SG_ 2589284014 VZE_ISA_Limit_beachtet_Distanz "Signal zur Uebertragung der im Sinne der GSR (General Safety Regulation) mit einem erkannten und eingehaltenen Tempolimit gefahrenen Distanz in Meter";
CM_ SG_ 2589284014 VZE_ISA_Limit_beachtet_Zeit "Signal zur Uebertragung der im Sinne der GSR (General Safety Regulation) mit einem erkannten und eingehaltenen Tempolimit gefahrenen Zeit in Sekunden";
CM_ SG_ 2589284014 VZE_ISA_Limit_ueberschr_Distanz "Signal zur Uebertragung der im Sinne der GSR (General Safety Regulation) mit einem erkannten und überschrittenen Tempolimit gefahrenen Distanz in Meter";
CM_ SG_ 2589284014 VZE_ISA_Limit_ueberschr_Zeit "Signal zur Uebertragung der im Sinne der GSR (General Safety Regulation) mit einem erkannten und überschrittenen Tempolimit gefahrenen Zeit in Sekunden";
CM_ SG_ 2589284014 VZE_ISA_Monitoring_Mux "Multiplex Zaehler für die VZE_06-Botschaft für das ISA Monitoring.";

CM_ SG_ 2463978954 VZE_Ampel_Datenbasis_REM "Die relevante Ampel wurde unter anderem mittels der Schwarmdaten erkannt.";
CM_ SG_ 2463978954 VZE_Ampel_Datenbasis_Vision "Die relevante Ampel wurde unter anderem mittels der Wahrnehmung erkannt.";
CM_ SG_ 2463978954 VZE_relevant_Stopp "Relevantes Stoppschild";
CM_ SG_ 2463978954 VZE_relevant_Stopp_Abstand "Abstand zum relevanten Stoppschild";
CM_ SG_ 2463978954 VZE_relevante_Ampel "Aktuelle Ampelphase der relevanten Ampel";
CM_ SG_ 2463978954 VZE_relevante_Ampel_Abstand "Abstand zur relevanten Ampel";

CM_ SG_ 1361 WFS_Betrieb_Lesespule "Schlüsselkommunikation über die Lesespule";
CM_ SG_ 1361 WFS_ELV_authorisiert "Authorisierung der elektrischen Lenkungsverriegelung an der WFS";
CM_ SG_ 1361 WFS_Fahrerhinweise "Meldungen, Fahrer- und Warnhinweise der Wegfahrsperre";
CM_ SG_ 1361 WFS_ID_Geb_autorisiert "Authorisierung Schluessel (ID-Geber)";
CM_ SG_ 1361 WFS_ID_Geb_autorisiert_in_Kl15 "Authorisierung des Schlüssels im aktiven Klemme-15-Zyklus";
CM_ SG_ 1361 WFS_ID_Geb_steckt "Schluessel (ID-Geber) im Zuendschloss
";
CM_ SG_ 1361 WFS_Klemmenfreigabe "Freigabe von der WFS zum Einschalten der Klemme 15 und Klemme S";
CM_ SG_ 1361 WFS_Klemmenfreigabe_Signatur "Signatur zur Klemmenfreigabe durch die WFS";
CM_ SG_ 1361 WFS_LF_Aktiv "LF Schluesselkommunikation
";
CM_ SG_ 1361 WFS_LZ "Anforderung aus Lastenheft WFS V
";
CM_ SG_ 1361 WFS_LZ_02 "Inbetriebnahme/Anlernzustand der Wegfahrsperre";
CM_ SG_ 1361 WFS_Parken_Status "Schnittstelle zwischen WFS und ZFAS für das Pilotierte Parken um in Richtung ZFAS den Status der WFS im BCM2 zu kommunizieren";
CM_ SG_ 1361 WFS_Safe "Status WFS";
CM_ SG_ 1361 WFS_Schluessel_Fahrberecht "Schlüsselnummer Fahrberechtigung
0 = ungueltig, xxxx = Schluessel-Nr.";
CM_ SG_ 1361 WFS_Schluessel_Ist "Istwert der gelernten Schluessel";
CM_ SG_ 1361 WFS_Schluessel_Soll "Sollwert der zu lernenden Schluessel";
CM_ SG_ 1361 WFS_Verbauinfo_ELV "Info über die Konfiguration der ELV im WFS-Master";

CM_ SG_ 1702 BCM1_SRA_aktiv "Status Scheinwerferreinigungsanlage";
CM_ SG_ 1702 Waschen_vorne_aktiv "Status: Waschen vorne aktiv";
CM_ SG_ 1702 Wischer1_Wischgeschwindigkeit "aktuelle, durch Sensorik gemessene Wischgeschwindigkeit";
CM_ SG_ 1702 Wischer_Anzeigetext "Das Signal fordert einen Kombi-Pop-Up mit entsprechenden Texten an";
CM_ SG_ 1702 Wischer_vorne_aktiv "Status: Wischer vorne";
CM_ SG_ 1702 Wischer_vorne_blockiert "Blockade Wischer vorne (z.B. durch Schnee)";
CM_ SG_ 1702 Wischer_vorne_defekt "Fehlerstatus Wischer vorne (Anzeige im Kombi)";
CM_ SG_ 1702 Wischer_vorne_Normal "Wischer Front normal aktiv";
CM_ SG_ 1702 Wischer_vorne_Parklage "Wischer Front in Parklage";
CM_ SG_ 1702 Wischer_vorne_Schnell "Wischer vorne schnell aktiv";
CM_ SG_ 1702 Wischer_WH_PopUp_Anf "Anzeige von Wischerstufen im Kombi.";
CM_ SG_ 1702 Wischer_WH_Typ "Signal beinhaltet Lenkstockschaltertyp für grafische Anzeige im Kombi zur Wischerfunktion";
CM_ SG_ 1702 WWSs_01_alt "Veraltet Bit für die LIN-Botschaft WWSs_01.

Betroffene Signale:

Wischer_vorne_aktiv";

CM_ SG_ 1411 BCM_FH_Freigabe "Funktionsfreigabe Fensterheber";
CM_ SG_ 1411 BCM_HSK_Freigabe "Handschuhkastenfreigabe";
CM_ SG_ 1411 BCM_Komfortfkt_Freigabe "globale Freigabe der Komfortfunktion";
CM_ SG_ 1411 BCM_Verdeck_Freigabe "Freigabe Verdeckbetrieb
";
CM_ SG_ 1411 DWA_aktiv "Status DWA  aktiv";
CM_ SG_ 1411 FBS_IDG_in_Reichweite "Für elektrisch betätigte Türen und Klappen muss für eine Betätigung über Funk eine Reichweitenbegrenzung eingeführt werden. Diese Bit zeigt an, dass sich der Funkschlüssel innerhalb der geforderten Reichweite befindet";
CM_ SG_ 1411 FBS_Warn_Schluessel_Batt "Kombi Prio Warnung Schluessel Batterie
'Bitte Schlüsselbatterie wechseln!'";
CM_ SG_ 1411 FFB_Auf_Taste "Auf-Taste Funkschluessel

";
CM_ SG_ 1411 FFB_CarFinder "Car Finder Funktion (Blinken ohne zu entriegeln)";
CM_ SG_ 1411 FFB_HDF_Taste "HDF Taste am Funkschluessel
";
CM_ SG_ 1411 FFB_Komfortoeffnen "Komfortoeffnen Funk
";
CM_ SG_ 1411 FFB_Komfortschliessen "Komfortschliessen Funk
";
CM_ SG_ 1411 FFB_Panik_Taste "Panik Taste Funkschluessel
";
CM_ SG_ 1411 FFB_Zu_Taste "Zu-Taste Funkschluessel
";
CM_ SG_ 1411 IRUE_aktiv "Status Innenraumüberwachung
";
CM_ SG_ 1411 IRUE_Taster_Fkts_LED "Anforderung Funktions-LED IRUE-Taster (LED wird vom TSG angesteuert)
MQB: Bei Verbau eines einzelnen Taster zur Deaktivierung von IRUE und NGS wird dieses Signal zur Ansteuerung der Funktions-LED gesendet.";
CM_ SG_ 1411 VIP_Sensor_STSG_HBFS_betaetigt "Schiebetürlauf HBFS wurde durch VIP angefordert und als berechtigt eingestuft.";
CM_ SG_ 1411 VIP_Sensor_STSG_HFS_betaetigt "Schiebetürlauf HFS wurde durch VIP angefordert und als berechtigt eingestuft.";
CM_ SG_ 1411 ZV_Anf_Challenge_Auth "Anforderung an alle beteiligten Steuergeräte die Challenge an den ZV-Master zu senden.";
CM_ SG_ 1411 ZV_BT_offen "gespiegeltes Bit BT_Tuer_geoeffnet TSG_BT_1 Botschaft";
CM_ SG_ 1411 ZV_Einzeltuerentriegelung "Einzeltürentriegelung ZV
";
CM_ SG_ 1411 ZV_eRWK_Umfeld_Pruefung "Anforderung an PDC/PLA im eRWK-Modus eine Umfeldprüfung durchzuführen";
CM_ SG_ 1411 ZV_FT_offen "gespiegeltes Bit FT_Tuer_geoeffnet TSG_FT_1 Botschaft";
CM_ SG_ 1411 ZV_gesafet_extern_ist "Istzustand: Fahrzeug aussen gesafet
";
CM_ SG_ 1411 ZV_gesafet_extern_soll "Sollzustand: Fahrzeug gesafet extern
";
CM_ SG_ 1411 ZV_HBFS_offen "gespiegeltes Bit HBFS_Tuer_geoeffnet TSG_HBFS_1 Botschaft";
CM_ SG_ 1411 ZV_HD_offen "Status Heckdeckel
";
CM_ SG_ 1411 ZV_Heckeinzelentriegelung "Heckdeckeleinzelentriegelung";
CM_ SG_ 1411 ZV_HFS_offen "gespiegeltes Bit HFS_Tuer_geoeffnet TSG_HFS_1 Botschaft";
CM_ SG_ 1411 ZV_HS_offen "Status Heckscheibe
";
CM_ SG_ 1411 ZV_ist_Zustand_verfuegbar "Verfügbarkeit IST-Zustand ZV

";
CM_ SG_ 1411 ZV_Oeffnungsmodus "Konfigurierter Oeffnungsmodus fuer ZV:
0 = globale Oeffnung (alle Tueren)
1 = ZV mit Einzeltuerentriegelung (FFB - nur Fahrertuer, Kessy - nur bediente Tuer)
2 = ZV individuell selektive Oeffnung (FFB - Fahrerseite, Kessy - bediente Tuer + Fahrertuer)";
CM_ SG_ 1411 ZV_Rollo_auf "Komfortöffnen des Dachrollos";
CM_ SG_ 1411 ZV_Rollo_zu "Komfortschließen des Dachrollos";
CM_ SG_ 1411 ZV_SAD_auf "Komfortöffnen des Schiebeausstelldaches";
CM_ SG_ 1411 ZV_SAD_zu "Komfortschließen des Schiebeausstelldaches";
CM_ SG_ 1411 ZV_SafeFunktion_aktiv "Statusübermittlung ob die Safe Funktion im Fzg. aktiv ist. Das Kombi benötigt das Signal, um den Text Safelock aktiv anzuzeigen. ";
CM_ SG_ 1411 ZV_Schluessel_Zugang "aktuelle Funkschlüsselnummer";
CM_ SG_ 1411 ZV_STSG_HBFS_Anf "Die ZV fordert einen Lauf bzw. Stopp der Schiebetür an.";
CM_ SG_ 1411 ZV_STSG_HFS_Anf "Die ZV fordert einen Lauf bzw. Stopp der Schiebetür an.";
CM_ SG_ 1411 ZV_Tankklappe_offen "Öffnungsstatus der Tankklappe";
CM_ SG_ 1411 ZV_verriegeln_Anf "Gesammelte externe ZV-Verriegelungsanforderung des Kunden (z. B. zur Aktivierung der Anzeige des Ladezustands über Aussenlicht).";
CM_ SG_ 1411 ZV_verriegelt_extern_ist "Istzustand: Verriegelung Fahrzeug aussen
";
CM_ SG_ 1411 ZV_verriegelt_extern_soll "Sollzustand: Verriegelung Fahrzeug aussen
";
CM_ SG_ 1411 ZV_verriegelt_intern_ist "Istzustand: Verriegelung Fahrzeug innen
";
CM_ SG_ 1411 ZV_verriegelt_intern_soll "Sollzustand: Verriegelung Fahrzeug innen
";
CM_ SG_ 1411 ZV_verriegelt_soll "Fahrzeug Gesamtverriegelungsstatus Sollzustand für Ladestecker- und Ladeklappenverriegelung. ";
BA_DEF_REL_ BU_SG_REL_  "GenSigTimeoutTime" INT 0 65535;
BA_DEF_ BO_  "DiagRequest" ENUM "No", "Yes";
BA_DEF_ BO_  "DiagResponse" ENUM "No", "Yes";
BA_DEF_ BO_  "DiagState" ENUM "No", "Yes";
BA_DEF_ BO_  "GenMsgChkConstant" HEX 0 4095;
BA_DEF_ BO_  "GenMsgCycleTime" INT 0 65535;
BA_DEF_ BO_  "GenMsgCycleTimeFast" INT 0 65535;
BA_DEF_ BO_  "GenMsgDelayTime" INT 0 100000;
BA_DEF_ BO_  "GenMsgILSupport" ENUM "No", "Yes";
BA_DEF_ BO_  "GenMsgNrOfRepetition" INT 0 100;
BA_DEF_ BO_  "GenMsgPDUConstants" STRING;
BA_DEF_ BO_  "GenMsgSendType" ENUM "Cyclic", "not_used", "not_used", "not_used", "not_used", "not_used", "not_used", "IfActive", "NoMsgSendType";
BA_DEF_ BO_  "GenMsgStartDelayTime" INT 0 100000;
BA_DEF_ BO_  "NmMessage" ENUM "No", "Yes";
BA_DEF_ BO_  "NmhMessage" ENUM "No", "Yes";
BA_DEF_ BO_  "MsgType" ENUM "Application", "NM ", "NMH", "TP2.0", "ISO-TP ", "BAP", "EID", "KS", "XCP_PRE_CONFIGURED", "XCP_RUNTIME_CONFIGURED";
BA_DEF_ BO_  "VAGTP20_API" HEX 0 255;
BA_DEF_ BO_  "VAGTP20_DynConnection" ENUM "No", "Yes";
BA_DEF_ BO_  "VAGTP20_DynSetup" ENUM "No", "Yes";
BA_DEF_ BO_  "VAGTP20_StatConnection" ENUM "No", "Yes";
BA_DEF_ BO_  "CANFD_BRS" ENUM "0", "1";
BA_DEF_ BO_  "VFrameFormat" ENUM "StandardCAN", "ExtendedCAN", "reserved", "reserved", "reserved", "reserved", "reserved", "reserved", "reserved", "reserved", "reserved", "reserved", "reserved", "reserved", "StandardCAN_FD", "ExtendedCAN_FD";
BA_DEF_ SG_  "GenSigActiveRepetitions" INT -2147483648 2147483647;
BA_DEF_ SG_  "GenSigInactiveValue" INT -2147483648 2147483647;
BA_DEF_ SG_  "GenSigSendType" ENUM "Cyclic", "OnWrite", "OnWriteWithRepetition", "OnChange", "OnChangeWithRepetition", "IfActive", "IfActiveWithRepetition", "NoSigSendType", "OnChangeAndIfActive", "OnChangeAndIfActiveWithRepetition";
BA_DEF_ SG_  "GenSigStartValue" INT -2147483648 2147483647;
BA_DEF_ SG_  "NWM-WakeupAllowed" ENUM "No", "Yes";
BA_DEF_ SG_  "GenSigFuncType" ENUM "NoFunction", "MsgCounter", "CRC-8", "XOR", "XOR-2", "DatedBit", "SW-Kl15", "CHK", "Constant", "Protocol", "CRC-8-SAE_J1850", "CRC-32", "DataLength", "DataID", "MsgCounter16", "SOK-Signatur", "Cluster";
BA_DEF_ SG_  "GenSigSwitchedByIgnition" ENUM "No", "Yes";
BA_DEF_ SG_  "Fehlerwert" HEX 0 2147483647;
BA_DEF_ SG_  "GenSigMissingSourceValue" HEX 0 2147483647;
BA_DEF_DEF_REL_  "GenSigTimeoutTime" 0;
BA_DEF_DEF_  "DiagRequest" "No";
BA_DEF_DEF_  "DiagResponse" "No";
BA_DEF_DEF_  "DiagState" "No";
BA_DEF_DEF_  "GenMsgChkConstant" 0;
BA_DEF_DEF_  "GenMsgCycleTime" 0;
BA_DEF_DEF_  "GenMsgCycleTimeFast" 0;
BA_DEF_DEF_  "GenMsgDelayTime" 0;
BA_DEF_DEF_  "GenMsgILSupport" "No";
BA_DEF_DEF_  "GenMsgNrOfRepetition" 0;
BA_DEF_DEF_  "GenMsgPDUConstants" "";
BA_DEF_DEF_  "GenMsgSendType" "NoMsgSendType";
BA_DEF_DEF_  "GenMsgStartDelayTime" 0;
BA_DEF_DEF_  "NmMessage" "No";
BA_DEF_DEF_  "NmhMessage" "No";
BA_DEF_DEF_  "MsgType" "Application";
BA_DEF_DEF_  "VAGTP20_API" 0;
BA_DEF_DEF_  "VAGTP20_DynConnection" "No";
BA_DEF_DEF_  "VAGTP20_DynSetup" "No";
BA_DEF_DEF_  "VAGTP20_StatConnection" "No";
BA_DEF_DEF_  "CANFD_BRS" "1";
BA_DEF_DEF_  "VFrameFormat" "StandardCAN";
BA_DEF_DEF_  "GenSigActiveRepetitions" 0;
BA_DEF_DEF_  "GenSigInactiveValue" 0;
BA_DEF_DEF_  "GenSigSendType" "NoSigSendType";
BA_DEF_DEF_  "GenSigStartValue" 0;
BA_DEF_DEF_  "NWM-WakeupAllowed" "No";
BA_DEF_DEF_  "GenSigFuncType" "NoFunction";
BA_DEF_DEF_  "GenSigSwitchedByIgnition" "Yes";
BA_DEF_DEF_  "Fehlerwert" 0;
BA_DEF_DEF_  "GenSigMissingSourceValue" 0;
BA_ "GenMsgCycleTime" BO_ 997 100;
BA_ "GenMsgDelayTime" BO_ 997 20;
BA_ "GenMsgILSupport" BO_ 997 1;
BA_ "GenMsgPDUConstants" BO_ 997 "0xc4,0x6a,0x69,0x30,0xcf,0x61,0x58,0x51,0x1b,0x86,0x99,0xd3,0xf6,0x1d,0x9a,0x37";
BA_ "GenMsgSendType" BO_ 997 0;
BA_ "VFrameFormat" BO_ 997 14;
BA_ "GenMsgCycleTime" BO_ 1019 80;
BA_ "GenMsgILSupport" BO_ 1019 1;
BA_ "GenMsgSendType" BO_ 1019 0;
BA_ "VFrameFormat" BO_ 1019 14;
BA_ "GenMsgCycleTime" BO_ 2463978710 100;
BA_ "GenMsgCycleTimeFast" BO_ 2463978710 10;
BA_ "GenMsgDelayTime" BO_ 2463978710 10;
BA_ "GenMsgILSupport" BO_ 2463978710 1;
BA_ "GenMsgNrOfRepetition" BO_ 2463978710 5;
BA_ "GenMsgPDUConstants" BO_ 2463978710 "0xf3,0xbb,0x4c,0x48,0x05,0x08,0x69,0xc8,0x60,0x76,0x27,0x02,0x3a,0xa8,0x32,0x51";
BA_ "GenMsgSendType" BO_ 2463978710 0;
BA_ "VFrameFormat" BO_ 2463978710 15;
BA_ "GenMsgCycleTime" BO_ 1716 200;
BA_ "GenMsgILSupport" BO_ 1716 1;
BA_ "GenMsgSendType" BO_ 1716 0;
BA_ "VFrameFormat" BO_ 1716 14;
BA_ "GenMsgCycleTime" BO_ 313 20;
BA_ "GenMsgILSupport" BO_ 313 1;
BA_ "GenMsgPDUConstants" BO_ 313 "0x96,0x92,0x95,0xb5,0x6e,0xe3,0xbd,0xb4,0xfa,0xae,0xbe,0xcb,0xcf,0xa5,0x77,0xef";
BA_ "GenMsgSendType" BO_ 313 0;
BA_ "VFrameFormat" BO_ 313 14;
BA_ "GenMsgCycleTime" BO_ 2463978663 200;
BA_ "GenMsgDelayTime" BO_ 2463978663 40;
BA_ "GenMsgILSupport" BO_ 2463978663 1;
BA_ "GenMsgSendType" BO_ 2463978663 0;
BA_ "VFrameFormat" BO_ 2463978663 15;
BA_ "GenMsgCycleTime" BO_ 2589284014 2000;
BA_ "GenMsgILSupport" BO_ 2589284014 1;
BA_ "GenMsgSendType" BO_ 2589284014 0;
BA_ "VFrameFormat" BO_ 2589284014 15;
BA_ "GenMsgCycleTime" BO_ 2463978954 100;
BA_ "GenMsgILSupport" BO_ 2463978954 1;
BA_ "GenMsgSendType" BO_ 2463978954 0;
BA_ "VFrameFormat" BO_ 2463978954 15;
BA_ "GenMsgCycleTime" BO_ 1361 200;
BA_ "GenMsgDelayTime" BO_ 1361 50;
BA_ "GenMsgILSupport" BO_ 1361 1;
BA_ "GenMsgSendType" BO_ 1361 0;
BA_ "VFrameFormat" BO_ 1361 14;
BA_ "GenMsgCycleTime" BO_ 1702 1000;
BA_ "GenMsgDelayTime" BO_ 1702 50;
BA_ "GenMsgILSupport" BO_ 1702 1;
BA_ "GenMsgSendType" BO_ 1702 0;
BA_ "VFrameFormat" BO_ 1702 14;
BA_ "MsgType" BO_ 2617163264 8;
BA_ "VFrameFormat" BO_ 2617163264 15;
BA_ "MsgType" BO_ 2617163265 9;
BA_ "VFrameFormat" BO_ 2617163265 15;
BA_ "MsgType" BO_ 2617101824 8;
BA_ "VFrameFormat" BO_ 2617101824 15;
BA_ "MsgType" BO_ 2617101825 9;
BA_ "VFrameFormat" BO_ 2617101825 15;
BA_ "GenMsgCycleTime" BO_ 1411 200;
BA_ "GenMsgCycleTimeFast" BO_ 1411 50;
BA_ "GenMsgDelayTime" BO_ 1411 20;
BA_ "GenMsgILSupport" BO_ 1411 1;
BA_ "GenMsgNrOfRepetition" BO_ 1411 3;
BA_ "GenMsgSendType" BO_ 1411 0;
BA_ "VFrameFormat" BO_ 1411 14;
BA_ "GenSigSendType" SG_ 997 FS_Push_Tuergriff 3;
BA_ "GenSigSwitchedByIgnition" SG_ 997 FS_Push_Tuergriff 0;
BA_ "GenSigSendType" SG_ 997 FS_Status_eTAG_ext 3;
BA_ "GenSigStartValue" SG_ 997 FS_Status_eTAG_ext 3;
BA_ "GenSigSwitchedByIgnition" SG_ 997 FS_Status_eTAG_ext 0;
BA_ "Fehlerwert" SG_ 997 FS_Status_eTAG_ext 4;
BA_ "GenSigSendType" SG_ 997 FT_ASW_Warnton 0;
BA_ "GenSigSwitchedByIgnition" SG_ 997 FT_ASW_Warnton 0;
BA_ "Fehlerwert" SG_ 997 FT_ASW_Warnton 3;
BA_ "GenSigSendType" SG_ 997 FT_BFS_Tuer_Status 3;
BA_ "GenSigSwitchedByIgnition" SG_ 997 FT_BFS_Tuer_Status 0;
BA_ "Fehlerwert" SG_ 997 FT_BFS_Tuer_Status 3;
BA_ "GenSigSendType" SG_ 997 FT_Cargolock_bet 3;
BA_ "GenSigSwitchedByIgnition" SG_ 997 FT_Cargolock_bet 0;
BA_ "GenSigSendType" SG_ 997 FT_HBFS_Tuer_Status 3;
BA_ "GenSigSwitchedByIgnition" SG_ 997 FT_HBFS_Tuer_Status 0;
BA_ "Fehlerwert" SG_ 997 FT_HBFS_Tuer_Status 3;
BA_ "GenSigSendType" SG_ 997 FT_HFS_Tuer_Status 3;
BA_ "GenSigSwitchedByIgnition" SG_ 997 FT_HFS_Tuer_Status 0;
BA_ "Fehlerwert" SG_ 997 FT_HFS_Tuer_Status 3;
BA_ "GenSigSendType" SG_ 997 FT_kisi_asynchron 3;
BA_ "GenSigSwitchedByIgnition" SG_ 997 FT_kisi_asynchron 0;
BA_ "GenSigSendType" SG_ 997 FT_KiSi_Status_Soll_HBFS 0;
BA_ "GenSigSwitchedByIgnition" SG_ 997 FT_KiSi_Status_Soll_HBFS 0;
BA_ "GenSigSendType" SG_ 997 FT_KiSi_Status_Soll_HFS 0;
BA_ "GenSigSwitchedByIgnition" SG_ 997 FT_KiSi_Status_Soll_HFS 0;
BA_ "GenSigSendType" SG_ 997 FT_Kisi_Taster_li_02 3;
BA_ "GenSigSwitchedByIgnition" SG_ 997 FT_Kisi_Taster_li_02 0;
BA_ "GenSigSendType" SG_ 997 FT_Kisi_Taster_re_02 3;
BA_ "GenSigSwitchedByIgnition" SG_ 997 FT_Kisi_Taster_re_02 0;
BA_ "GenSigSendType" SG_ 997 FT_Lock_Taster_02 0;
BA_ "GenSigSwitchedByIgnition" SG_ 997 FT_Lock_Taster_02 0;
BA_ "GenSigSendType" SG_ 997 FT_Schluesselschalter_zu_02 0;
BA_ "GenSigSwitchedByIgnition" SG_ 997 FT_Schluesselschalter_zu_02 0;
BA_ "GenSigSendType" SG_ 997 FT_SP_Heizung_ein 3;
BA_ "GenSigSwitchedByIgnition" SG_ 997 FT_SP_Heizung_ein 0;
BA_ "GenSigSendType" SG_ 997 FT_TCR_Mode_aktiv 3;
BA_ "GenSigSwitchedByIgnition" SG_ 997 FT_TCR_Mode_aktiv 0;
BA_ "GenSigSendType" SG_ 997 FT_TD_Taste_Status 3;
BA_ "GenSigSwitchedByIgnition" SG_ 997 FT_TD_Taste_Status 0;
BA_ "GenSigSendType" SG_ 997 FT_Tuer_Status 3;
BA_ "GenSigSwitchedByIgnition" SG_ 997 FT_Tuer_Status 0;
BA_ "Fehlerwert" SG_ 997 FT_Tuer_Status 3;
BA_ "GenSigSendType" SG_ 997 FT_Tuer_Status_QBit 0;
BA_ "GenSigSwitchedByIgnition" SG_ 997 FT_Tuer_Status_QBit 0;
BA_ "GenSigSendType" SG_ 997 FT_Tueroeffnen_Warnung 3;
BA_ "GenSigSwitchedByIgnition" SG_ 997 FT_Tueroeffnen_Warnung 0;
BA_ "GenSigSendType" SG_ 997 SSA_FT_ASW_Status 3;
BA_ "GenSigSwitchedByIgnition" SG_ 997 SSA_FT_ASW_Status 0;
BA_ "GenSigSendType" SG_ 997 TBF_FS_Touch_Event 3;
BA_ "GenSigSwitchedByIgnition" SG_ 997 TBF_FS_Touch_Event 0;
BA_ "GenSigSendType" SG_ 997 TSG_FS_Spiegel_angeklappt 3;
BA_ "GenSigSwitchedByIgnition" SG_ 997 TSG_FS_Spiegel_angeklappt 0;
BA_ "GenSigSendType" SG_ 997 TSG_FT_02_BZ 0;
BA_ "GenSigFuncType" SG_ 997 TSG_FT_02_BZ 1;
BA_ "GenSigSwitchedByIgnition" SG_ 997 TSG_FT_02_BZ 0;
BA_ "GenSigSendType" SG_ 997 TSG_FT_02_CRC 0;
BA_ "GenSigFuncType" SG_ 997 TSG_FT_02_CRC 2;
BA_ "GenSigSwitchedByIgnition" SG_ 997 TSG_FT_02_CRC 0;
BA_ "GenSigSendType" SG_ 1019 TSK_Ausrollkurve_Mux 0;
BA_ "GenSigSwitchedByIgnition" SG_ 1019 TSK_Ausrollkurve_Mux 0;
BA_ "GenSigSendType" SG_ 1019 TSK_Ausrollkurve_Reku 0;
BA_ "GenSigSwitchedByIgnition" SG_ 1019 TSK_Ausrollkurve_Reku 0;
BA_ "GenSigSendType" SG_ 1019 TSK_Ausrollkurve_Schrittweite 0;
BA_ "GenSigSwitchedByIgnition" SG_ 1019 TSK_Ausrollkurve_Schrittweite 0;
BA_ "GenSigStartValue" SG_ 1019 TSK_Ausrollkurve_Schub_Reku_01 127;
BA_ "GenSigSwitchedByIgnition" SG_ 1019 TSK_Ausrollkurve_Schub_Reku_01 0;
BA_ "GenSigStartValue" SG_ 1019 TSK_Ausrollkurve_Schub_Reku_02 127;
BA_ "GenSigSwitchedByIgnition" SG_ 1019 TSK_Ausrollkurve_Schub_Reku_02 0;
BA_ "GenSigStartValue" SG_ 1019 TSK_Ausrollkurve_Schub_Reku_03 127;
BA_ "GenSigSwitchedByIgnition" SG_ 1019 TSK_Ausrollkurve_Schub_Reku_03 0;
BA_ "GenSigStartValue" SG_ 1019 TSK_Ausrollkurve_Schub_Reku_04 127;
BA_ "GenSigSwitchedByIgnition" SG_ 1019 TSK_Ausrollkurve_Schub_Reku_04 0;
BA_ "GenSigStartValue" SG_ 1019 TSK_Ausrollkurve_Schub_Reku_05 127;
BA_ "GenSigSwitchedByIgnition" SG_ 1019 TSK_Ausrollkurve_Schub_Reku_05 0;
BA_ "GenSigStartValue" SG_ 1019 TSK_Ausrollkurve_Schub_Reku_06 127;
BA_ "GenSigSwitchedByIgnition" SG_ 1019 TSK_Ausrollkurve_Schub_Reku_06 0;
BA_ "GenSigStartValue" SG_ 1019 TSK_Ausrollkurve_Schub_Reku_07 127;
BA_ "GenSigSwitchedByIgnition" SG_ 1019 TSK_Ausrollkurve_Schub_Reku_07 0;
BA_ "GenSigStartValue" SG_ 1019 TSK_Ausrollkurve_Schub_Reku_08 127;
BA_ "GenSigSwitchedByIgnition" SG_ 1019 TSK_Ausrollkurve_Schub_Reku_08 0;
BA_ "GenSigStartValue" SG_ 1019 TSK_Ausrollkurve_Schub_Reku_09 127;
BA_ "GenSigSwitchedByIgnition" SG_ 1019 TSK_Ausrollkurve_Schub_Reku_09 0;
BA_ "GenSigStartValue" SG_ 1019 TSK_Ausrollkurve_Schub_Reku_10 127;
BA_ "GenSigSwitchedByIgnition" SG_ 1019 TSK_Ausrollkurve_Schub_Reku_10 0;
BA_ "GenSigStartValue" SG_ 1019 TSK_Ausrollkurve_Schub_Reku_11 127;
BA_ "GenSigSwitchedByIgnition" SG_ 1019 TSK_Ausrollkurve_Schub_Reku_11 0;
BA_ "GenSigStartValue" SG_ 1019 TSK_Ausrollkurve_Schub_Reku_12 127;
BA_ "GenSigSwitchedByIgnition" SG_ 1019 TSK_Ausrollkurve_Schub_Reku_12 0;
BA_ "GenSigStartValue" SG_ 1019 TSK_Ausrollkurve_Schub_Reku_13 127;
BA_ "GenSigSwitchedByIgnition" SG_ 1019 TSK_Ausrollkurve_Schub_Reku_13 0;
BA_ "GenSigStartValue" SG_ 1019 TSK_Ausrollkurve_Schub_Reku_14 127;
BA_ "GenSigSwitchedByIgnition" SG_ 1019 TSK_Ausrollkurve_Schub_Reku_14 0;
BA_ "GenSigStartValue" SG_ 1019 TSK_Ausrollkurve_Schub_Reku_15 127;
BA_ "GenSigSwitchedByIgnition" SG_ 1019 TSK_Ausrollkurve_Schub_Reku_15 0;
BA_ "GenSigStartValue" SG_ 1019 TSK_Ausrollkurve_Schub_Reku_16 127;
BA_ "GenSigSwitchedByIgnition" SG_ 1019 TSK_Ausrollkurve_Schub_Reku_16 0;
BA_ "GenSigStartValue" SG_ 1019 TSK_Ausrollkurve_Schub_Reku_17 127;
BA_ "GenSigSwitchedByIgnition" SG_ 1019 TSK_Ausrollkurve_Schub_Reku_17 0;
BA_ "GenSigStartValue" SG_ 1019 TSK_Ausrollkurve_Schub_Reku_18 127;
BA_ "GenSigSwitchedByIgnition" SG_ 1019 TSK_Ausrollkurve_Schub_Reku_18 0;
BA_ "GenSigStartValue" SG_ 1019 TSK_Ausrollkurve_Schub_Reku_19 127;
BA_ "GenSigSwitchedByIgnition" SG_ 1019 TSK_Ausrollkurve_Schub_Reku_19 0;
BA_ "GenSigStartValue" SG_ 1019 TSK_Ausrollkurve_Schub_Reku_20 127;
BA_ "GenSigSwitchedByIgnition" SG_ 1019 TSK_Ausrollkurve_Schub_Reku_20 0;
BA_ "GenSigStartValue" SG_ 1019 TSK_Ausrollkurve_Segeln_01 127;
BA_ "GenSigSwitchedByIgnition" SG_ 1019 TSK_Ausrollkurve_Segeln_01 0;
BA_ "GenSigStartValue" SG_ 1019 TSK_Ausrollkurve_Segeln_02 127;
BA_ "GenSigSwitchedByIgnition" SG_ 1019 TSK_Ausrollkurve_Segeln_02 0;
BA_ "GenSigStartValue" SG_ 1019 TSK_Ausrollkurve_Segeln_03 127;
BA_ "GenSigSwitchedByIgnition" SG_ 1019 TSK_Ausrollkurve_Segeln_03 0;
BA_ "GenSigStartValue" SG_ 1019 TSK_Ausrollkurve_Segeln_04 127;
BA_ "GenSigSwitchedByIgnition" SG_ 1019 TSK_Ausrollkurve_Segeln_04 0;
BA_ "GenSigStartValue" SG_ 1019 TSK_Ausrollkurve_Segeln_05 127;
BA_ "GenSigSwitchedByIgnition" SG_ 1019 TSK_Ausrollkurve_Segeln_05 0;
BA_ "GenSigStartValue" SG_ 1019 TSK_Ausrollkurve_Segeln_06 127;
BA_ "GenSigSwitchedByIgnition" SG_ 1019 TSK_Ausrollkurve_Segeln_06 0;
BA_ "GenSigStartValue" SG_ 1019 TSK_Ausrollkurve_Segeln_07 127;
BA_ "GenSigSwitchedByIgnition" SG_ 1019 TSK_Ausrollkurve_Segeln_07 0;
BA_ "GenSigStartValue" SG_ 1019 TSK_Ausrollkurve_Segeln_08 127;
BA_ "GenSigSwitchedByIgnition" SG_ 1019 TSK_Ausrollkurve_Segeln_08 0;
BA_ "GenSigStartValue" SG_ 1019 TSK_Ausrollkurve_Segeln_09 127;
BA_ "GenSigSwitchedByIgnition" SG_ 1019 TSK_Ausrollkurve_Segeln_09 0;
BA_ "GenSigStartValue" SG_ 1019 TSK_Ausrollkurve_Segeln_10 127;
BA_ "GenSigSwitchedByIgnition" SG_ 1019 TSK_Ausrollkurve_Segeln_10 0;
BA_ "GenSigStartValue" SG_ 1019 TSK_Ausrollkurve_Segeln_11 127;
BA_ "GenSigSwitchedByIgnition" SG_ 1019 TSK_Ausrollkurve_Segeln_11 0;
BA_ "GenSigStartValue" SG_ 1019 TSK_Ausrollkurve_Segeln_12 127;
BA_ "GenSigSwitchedByIgnition" SG_ 1019 TSK_Ausrollkurve_Segeln_12 0;
BA_ "GenSigStartValue" SG_ 1019 TSK_Ausrollkurve_Segeln_13 127;
BA_ "GenSigSwitchedByIgnition" SG_ 1019 TSK_Ausrollkurve_Segeln_13 0;
BA_ "GenSigStartValue" SG_ 1019 TSK_Ausrollkurve_Segeln_14 127;
BA_ "GenSigSwitchedByIgnition" SG_ 1019 TSK_Ausrollkurve_Segeln_14 0;
BA_ "GenSigStartValue" SG_ 1019 TSK_Ausrollkurve_Segeln_15 127;
BA_ "GenSigSwitchedByIgnition" SG_ 1019 TSK_Ausrollkurve_Segeln_15 0;
BA_ "GenSigStartValue" SG_ 1019 TSK_Ausrollkurve_Segeln_16 127;
BA_ "GenSigSwitchedByIgnition" SG_ 1019 TSK_Ausrollkurve_Segeln_16 0;
BA_ "GenSigStartValue" SG_ 1019 TSK_Ausrollkurve_Segeln_17 127;
BA_ "GenSigSwitchedByIgnition" SG_ 1019 TSK_Ausrollkurve_Segeln_17 0;
BA_ "GenSigStartValue" SG_ 1019 TSK_Ausrollkurve_Segeln_18 127;
BA_ "GenSigSwitchedByIgnition" SG_ 1019 TSK_Ausrollkurve_Segeln_18 0;
BA_ "GenSigStartValue" SG_ 1019 TSK_Ausrollkurve_Segeln_19 127;
BA_ "GenSigSwitchedByIgnition" SG_ 1019 TSK_Ausrollkurve_Segeln_19 0;
BA_ "GenSigStartValue" SG_ 1019 TSK_Ausrollkurve_Segeln_20 127;
BA_ "GenSigSwitchedByIgnition" SG_ 1019 TSK_Ausrollkurve_Segeln_20 0;
BA_ "GenSigSendType" SG_ 1019 TSK_Ausrollkurve_Zaehler 0;
BA_ "GenSigSwitchedByIgnition" SG_ 1019 TSK_Ausrollkurve_Zaehler 0;
BA_ "GenSigSendType" SG_ 2463978710 OPS_ComfortReadyStatus 4;
BA_ "GenSigSwitchedByIgnition" SG_ 2463978710 OPS_ComfortReadyStatus 0;
BA_ "Fehlerwert" SG_ 2463978710 OPS_ComfortReadyStatus 3;
BA_ "GenSigSendType" SG_ 2463978710 OPS_DriverPresenceStatus 4;
BA_ "GenSigSwitchedByIgnition" SG_ 2463978710 OPS_DriverPresenceStatus 0;
BA_ "Fehlerwert" SG_ 2463978710 OPS_DriverPresenceStatus 15;
BA_ "GenSigSendType" SG_ 2463978710 OPS_OccupantPresenceStatus 4;
BA_ "GenSigSwitchedByIgnition" SG_ 2463978710 OPS_OccupantPresenceStatus 0;
BA_ "Fehlerwert" SG_ 2463978710 OPS_OccupantPresenceStatus 7;
BA_ "GenSigSendType" SG_ 2463978710 OPS_QBit_DriverPresence 4;
BA_ "GenSigStartValue" SG_ 2463978710 OPS_QBit_DriverPresence 1;
BA_ "GenSigSwitchedByIgnition" SG_ 2463978710 OPS_QBit_DriverPresence 0;
BA_ "GenSigSendType" SG_ 2463978710 OPS_SafeDriverPresence_available 4;
BA_ "GenSigSwitchedByIgnition" SG_ 2463978710 OPS_SafeDriverPresence_available 0;
BA_ "GenSigSendType" SG_ 2463978710 OPS_SafeDriverPresenceStatus 4;
BA_ "GenSigSwitchedByIgnition" SG_ 2463978710 OPS_SafeDriverPresenceStatus 0;
BA_ "Fehlerwert" SG_ 2463978710 OPS_SafeDriverPresenceStatus 3;
BA_ "GenSigSendType" SG_ 2463978710 UserStateServer_01_BZ 0;
BA_ "GenSigFuncType" SG_ 2463978710 UserStateServer_01_BZ 1;
BA_ "GenSigSwitchedByIgnition" SG_ 2463978710 UserStateServer_01_BZ 0;
BA_ "GenSigSendType" SG_ 2463978710 UserStateServer_01_CRC 0;
BA_ "GenSigFuncType" SG_ 2463978710 UserStateServer_01_CRC 2;
BA_ "GenSigSwitchedByIgnition" SG_ 2463978710 UserStateServer_01_CRC 0;
BA_ "GenSigSwitchedByIgnition" SG_ 1716 KS_Geheimnis_1 0;
BA_ "GenSigSwitchedByIgnition" SG_ 1716 KS_Geheimnis_2 0;
BA_ "GenSigSwitchedByIgnition" SG_ 1716 KS_Geheimnis_3 0;
BA_ "GenSigSwitchedByIgnition" SG_ 1716 KS_Geheimnis_4 0;
BA_ "GenSigSendType" SG_ 1716 VIN_01_MUX 0;
BA_ "GenSigSwitchedByIgnition" SG_ 1716 VIN_01_MUX 0;
BA_ "GenSigStartValue" SG_ 1716 VIN_1 45;
BA_ "GenSigSwitchedByIgnition" SG_ 1716 VIN_1 0;
BA_ "GenSigStartValue" SG_ 1716 VIN_10 45;
BA_ "GenSigSwitchedByIgnition" SG_ 1716 VIN_10 0;
BA_ "GenSigStartValue" SG_ 1716 VIN_11 45;
BA_ "GenSigSwitchedByIgnition" SG_ 1716 VIN_11 0;
BA_ "GenSigStartValue" SG_ 1716 VIN_12 45;
BA_ "GenSigSwitchedByIgnition" SG_ 1716 VIN_12 0;
BA_ "GenSigStartValue" SG_ 1716 VIN_13 45;
BA_ "GenSigSwitchedByIgnition" SG_ 1716 VIN_13 0;
BA_ "GenSigStartValue" SG_ 1716 VIN_14 45;
BA_ "GenSigSwitchedByIgnition" SG_ 1716 VIN_14 0;
BA_ "GenSigStartValue" SG_ 1716 VIN_15 45;
BA_ "GenSigSwitchedByIgnition" SG_ 1716 VIN_15 0;
BA_ "GenSigStartValue" SG_ 1716 VIN_16 45;
BA_ "GenSigSwitchedByIgnition" SG_ 1716 VIN_16 0;
BA_ "GenSigStartValue" SG_ 1716 VIN_17 45;
BA_ "GenSigSwitchedByIgnition" SG_ 1716 VIN_17 0;
BA_ "GenSigStartValue" SG_ 1716 VIN_2 45;
BA_ "GenSigSwitchedByIgnition" SG_ 1716 VIN_2 0;
BA_ "GenSigStartValue" SG_ 1716 VIN_3 45;
BA_ "GenSigSwitchedByIgnition" SG_ 1716 VIN_3 0;
BA_ "GenSigStartValue" SG_ 1716 VIN_4 45;
BA_ "GenSigSwitchedByIgnition" SG_ 1716 VIN_4 0;
BA_ "GenSigStartValue" SG_ 1716 VIN_5 45;
BA_ "GenSigSwitchedByIgnition" SG_ 1716 VIN_5 0;
BA_ "GenSigStartValue" SG_ 1716 VIN_6 45;
BA_ "GenSigSwitchedByIgnition" SG_ 1716 VIN_6 0;
BA_ "GenSigStartValue" SG_ 1716 VIN_7 45;
BA_ "GenSigSwitchedByIgnition" SG_ 1716 VIN_7 0;
BA_ "GenSigStartValue" SG_ 1716 VIN_8 45;
BA_ "GenSigSwitchedByIgnition" SG_ 1716 VIN_8 0;
BA_ "GenSigStartValue" SG_ 1716 VIN_9 45;
BA_ "GenSigSwitchedByIgnition" SG_ 1716 VIN_9 0;
BA_ "GenSigSendType" SG_ 313 HMS_aktives_System 0;
BA_ "GenSigSwitchedByIgnition" SG_ 313 HMS_aktives_System 0;
BA_ "GenSigSendType" SG_ 313 HMS_Anforderung_GE 0;
BA_ "GenSigSwitchedByIgnition" SG_ 313 HMS_Anforderung_GE 0;
BA_ "GenSigSendType" SG_ 313 HMS_Fehlerstatus 0;
BA_ "GenSigSwitchedByIgnition" SG_ 313 HMS_Fehlerstatus 0;
BA_ "GenSigSendType" SG_ 313 HMS_Haltemoment 0;
BA_ "GenSigStartValue" SG_ 313 HMS_Haltemoment 1022;
BA_ "GenSigSwitchedByIgnition" SG_ 313 HMS_Haltemoment 0;
BA_ "Fehlerwert" SG_ 313 HMS_Haltemoment 1023;
BA_ "GenSigSendType" SG_ 313 HMS_halten_nicht_verfuegbar 0;
BA_ "GenSigSwitchedByIgnition" SG_ 313 HMS_halten_nicht_verfuegbar 0;
BA_ "GenSigSendType" SG_ 313 HMS_halten_nicht_verfuegbar_02 0;
BA_ "GenSigSwitchedByIgnition" SG_ 313 HMS_halten_nicht_verfuegbar_02 0;
BA_ "GenSigSendType" SG_ 313 HMS_Index_Haltemoment 0;
BA_ "GenSigSwitchedByIgnition" SG_ 313 HMS_Index_Haltemoment 0;
BA_ "GenSigSendType" SG_ 313 HMS_P_beibehalten_GE 0;
BA_ "GenSigStartValue" SG_ 313 HMS_P_beibehalten_GE 2;
BA_ "GenSigSwitchedByIgnition" SG_ 313 HMS_P_beibehalten_GE 0;
BA_ "Fehlerwert" SG_ 313 HMS_P_beibehalten_GE 3;
BA_ "GenSigSendType" SG_ 313 HMS_parken_nicht_verfuegbar 0;
BA_ "GenSigSwitchedByIgnition" SG_ 313 HMS_parken_nicht_verfuegbar 0;
BA_ "GenSigSendType" SG_ 313 HMS_Stillstand 0;
BA_ "GenSigStartValue" SG_ 313 HMS_Stillstand 6;
BA_ "GenSigSwitchedByIgnition" SG_ 313 HMS_Stillstand 0;
BA_ "Fehlerwert" SG_ 313 HMS_Stillstand 7;
BA_ "GenSigSendType" SG_ 313 HMS_Systemstatus 0;
BA_ "GenSigStartValue" SG_ 313 HMS_Systemstatus 14;
BA_ "GenSigSwitchedByIgnition" SG_ 313 HMS_Systemstatus 0;
BA_ "Fehlerwert" SG_ 313 HMS_Systemstatus 15;
BA_ "GenSigSendType" SG_ 313 SOK_VMM_02_Signatur 0;
BA_ "GenSigFuncType" SG_ 313 SOK_VMM_02_Signatur 15;
BA_ "GenSigSendType" SG_ 313 VMM_02_BZ 0;
BA_ "GenSigFuncType" SG_ 313 VMM_02_BZ 1;
BA_ "GenSigSwitchedByIgnition" SG_ 313 VMM_02_BZ 0;
BA_ "GenSigSendType" SG_ 313 VMM_02_CRC 0;
BA_ "GenSigFuncType" SG_ 313 VMM_02_CRC 2;
BA_ "GenSigSwitchedByIgnition" SG_ 313 VMM_02_CRC 0;
BA_ "GenSigSendType" SG_ 313 VMM_Bremslicht_defekt 0;
BA_ "GenSigSwitchedByIgnition" SG_ 313 VMM_Bremslicht_defekt 0;
BA_ "GenSigSendType" SG_ 313 VMM_Bremslicht_unplausibel 0;
BA_ "GenSigSwitchedByIgnition" SG_ 313 VMM_Bremslicht_unplausibel 0;
BA_ "GenSigSendType" SG_ 313 VMM_Fahrer_Bremskraft_bestimmend 0;
BA_ "GenSigSwitchedByIgnition" SG_ 313 VMM_Fahrer_Bremskraft_bestimmend 0;
BA_ "GenSigSendType" SG_ 313 VMM_Inkonsistenz_ACC 0;
BA_ "GenSigSwitchedByIgnition" SG_ 313 VMM_Inkonsistenz_ACC 0;
BA_ "GenSigSendType" SG_ 313 VMM_Inkonsistenz_AEB 0;
BA_ "GenSigSwitchedByIgnition" SG_ 313 VMM_Inkonsistenz_AEB 0;
BA_ "GenSigSendType" SG_ 313 VMM_Inkonsistenz_ARA 0;
BA_ "GenSigSwitchedByIgnition" SG_ 313 VMM_Inkonsistenz_ARA 0;
BA_ "GenSigSendType" SG_ 313 VMM_Inkonsistenz_AWV_PCF 0;
BA_ "GenSigSwitchedByIgnition" SG_ 313 VMM_Inkonsistenz_AWV_PCF 0;
BA_ "GenSigSendType" SG_ 313 VMM_Inkonsistenz_EA 0;
BA_ "GenSigSwitchedByIgnition" SG_ 313 VMM_Inkonsistenz_EA 0;
BA_ "GenSigSendType" SG_ 313 VMM_Inkonsistenz_EBKV 0;
BA_ "GenSigSwitchedByIgnition" SG_ 313 VMM_Inkonsistenz_EBKV 0;
BA_ "GenSigSendType" SG_ 313 VMM_Inkonsistenz_FAS_VK 0;
BA_ "GenSigSwitchedByIgnition" SG_ 313 VMM_Inkonsistenz_FAS_VK 0;
BA_ "GenSigSendType" SG_ 313 VMM_Inkonsistenz_GE 0;
BA_ "GenSigSwitchedByIgnition" SG_ 313 VMM_Inkonsistenz_GE 0;
BA_ "GenSigSendType" SG_ 313 VMM_Inkonsistenz_HVLM 0;
BA_ "GenSigSwitchedByIgnition" SG_ 313 VMM_Inkonsistenz_HVLM 0;
BA_ "GenSigSendType" SG_ 313 VMM_Inkonsistenz_KAM 0;
BA_ "GenSigSwitchedByIgnition" SG_ 313 VMM_Inkonsistenz_KAM 0;
BA_ "GenSigSendType" SG_ 313 VMM_Inkonsistenz_KAS 0;
BA_ "GenSigSwitchedByIgnition" SG_ 313 VMM_Inkonsistenz_KAS 0;
BA_ "GenSigSendType" SG_ 313 VMM_Inkonsistenz_MO 0;
BA_ "GenSigSwitchedByIgnition" SG_ 313 VMM_Inkonsistenz_MO 0;
BA_ "GenSigSendType" SG_ 313 VMM_Inkonsistenz_NV 0;
BA_ "GenSigSwitchedByIgnition" SG_ 313 VMM_Inkonsistenz_NV 0;
BA_ "GenSigSendType" SG_ 313 VMM_Inkonsistenz_ParkAssist 0;
BA_ "GenSigSwitchedByIgnition" SG_ 313 VMM_Inkonsistenz_ParkAssist 0;
BA_ "GenSigSendType" SG_ 313 VMM_Inkonsistenz_RCTA 0;
BA_ "GenSigSwitchedByIgnition" SG_ 313 VMM_Inkonsistenz_RCTA 0;
BA_ "GenSigSendType" SG_ 313 VMM_Inkonsistenz_RHP 0;
BA_ "GenSigSwitchedByIgnition" SG_ 313 VMM_Inkonsistenz_RHP 0;
BA_ "GenSigSendType" SG_ 313 VMM_Inkonsistenz_TSK 0;
BA_ "GenSigSwitchedByIgnition" SG_ 313 VMM_Inkonsistenz_TSK 0;
BA_ "GenSigSendType" SG_ 313 VMM_Inkonsistenz_VLK 0;
BA_ "GenSigSwitchedByIgnition" SG_ 313 VMM_Inkonsistenz_VLK 0;
BA_ "GenSigSendType" SG_ 313 VMM_Inkonsistenz_VMC 0;
BA_ "GenSigSwitchedByIgnition" SG_ 313 VMM_Inkonsistenz_VMC 0;
BA_ "GenSigSendType" SG_ 313 VMM_MKB_codiert 0;
BA_ "GenSigSwitchedByIgnition" SG_ 313 VMM_MKB_codiert 0;
BA_ "GenSigSendType" SG_ 313 VMM_Notstopp_Status 0;
BA_ "GenSigSwitchedByIgnition" SG_ 313 VMM_Notstopp_Status 0;
BA_ "Fehlerwert" SG_ 313 VMM_Notstopp_Status 7;
BA_ "GenSigSendType" SG_ 313 VZM_aktiver_Basisservice 0;
BA_ "GenSigSwitchedByIgnition" SG_ 313 VZM_aktiver_Basisservice 0;
BA_ "GenSigSendType" SG_ 313 VZM_aktives_System 0;
BA_ "GenSigSwitchedByIgnition" SG_ 313 VZM_aktives_System 0;
BA_ "GenSigSendType" SG_ 313 VZM_Anhalteweg_nicht_verfuegbar 0;
BA_ "GenSigSwitchedByIgnition" SG_ 313 VZM_Anhalteweg_nicht_verfuegbar 0;
BA_ "GenSigSendType" SG_ 313 VZM_Bkd_nicht_verfuegbar 0;
BA_ "GenSigSwitchedByIgnition" SG_ 313 VZM_Bkd_nicht_verfuegbar 0;
BA_ "GenSigSendType" SG_ 313 VZM_Fahrer_bremst 0;
BA_ "GenSigSwitchedByIgnition" SG_ 313 VZM_Fahrer_bremst 0;
BA_ "GenSigSendType" SG_ 313 VZM_Fahrer_bremst_deutlich 0;
BA_ "GenSigSwitchedByIgnition" SG_ 313 VZM_Fahrer_bremst_deutlich 0;
BA_ "GenSigSendType" SG_ 313 VZM_QBit_Fahrer_bremst 0;
BA_ "GenSigStartValue" SG_ 313 VZM_QBit_Fahrer_bremst 1;
BA_ "GenSigSwitchedByIgnition" SG_ 313 VZM_QBit_Fahrer_bremst 0;
BA_ "GenSigSendType" SG_ 313 VZM_SRBM_Ist 0;
BA_ "GenSigStartValue" SG_ 313 VZM_SRBM_Ist 4094;
BA_ "GenSigSwitchedByIgnition" SG_ 313 VZM_SRBM_Ist 0;
BA_ "Fehlerwert" SG_ 313 VZM_SRBM_Ist 4095;
BA_ "GenSigSendType" SG_ 313 VZM_SRBM_max_Gradient 0;
BA_ "GenSigStartValue" SG_ 313 VZM_SRBM_max_Gradient 126;
BA_ "GenSigSwitchedByIgnition" SG_ 313 VZM_SRBM_max_Gradient 0;
BA_ "Fehlerwert" SG_ 313 VZM_SRBM_max_Gradient 127;
BA_ "GenSigSendType" SG_ 313 VZM_SRBM_Soll 0;
BA_ "GenSigStartValue" SG_ 313 VZM_SRBM_Soll 4094;
BA_ "GenSigSwitchedByIgnition" SG_ 313 VZM_SRBM_Soll 0;
BA_ "Fehlerwert" SG_ 313 VZM_SRBM_Soll 4095;
BA_ "GenSigSendType" SG_ 313 VZM_Status_Wegregelung 0;
BA_ "GenSigSwitchedByIgnition" SG_ 313 VZM_Status_Wegregelung 0;
BA_ "GenSigSendType" SG_ 313 VZM_Systemstatus 0;
BA_ "GenSigSwitchedByIgnition" SG_ 313 VZM_Systemstatus 0;
BA_ "Fehlerwert" SG_ 313 VZM_Systemstatus 4;
BA_ "GenSigSendType" SG_ 313 VZM_TSK_SRBM_Anf 0;
BA_ "GenSigSwitchedByIgnition" SG_ 313 VZM_TSK_SRBM_Anf 0;
BA_ "GenSigSendType" SG_ 313 VZM_TSK_SRBM_nicht_verfuegbar 0;
BA_ "GenSigSwitchedByIgnition" SG_ 313 VZM_TSK_SRBM_nicht_verfuegbar 0;
BA_ "GenSigSendType" SG_ 313 VZM_Unterdrueckung_Antriebsmom 0;
BA_ "GenSigSwitchedByIgnition" SG_ 313 VZM_Unterdrueckung_Antriebsmom 0;
BA_ "GenSigSendType" SG_ 313 VZM_Verz_ASIL_Verfuegbarkeit 0;
BA_ "GenSigSwitchedByIgnition" SG_ 313 VZM_Verz_ASIL_Verfuegbarkeit 0;
BA_ "GenSigSendType" SG_ 313 VZM_Verz_Begrenzung 0;
BA_ "GenSigSwitchedByIgnition" SG_ 313 VZM_Verz_Begrenzung 0;
BA_ "GenSigSendType" SG_ 313 VZM_Verz_Reg_aktiv 0;
BA_ "GenSigSwitchedByIgnition" SG_ 313 VZM_Verz_Reg_aktiv 0;
BA_ "GenSigSendType" SG_ 313 VZM_Verz_Reg_nicht_verfuegbar 0;
BA_ "GenSigSwitchedByIgnition" SG_ 313 VZM_Verz_Reg_nicht_verfuegbar 0;
BA_ "GenSigSendType" SG_ 313 VZM_Warnruck_nicht_verfuegbar 0;
BA_ "GenSigSwitchedByIgnition" SG_ 313 VZM_Warnruck_nicht_verfuegbar 0;
BA_ "GenSigSendType" SG_ 313 VZM_Warnruckeln_nicht_verfuegbar 0;
BA_ "GenSigSwitchedByIgnition" SG_ 313 VZM_Warnruckeln_nicht_verfuegbar 0;
BA_ "GenSigSendType" SG_ 2463978663 VZE_Akustik_Limitwechsel 0;
BA_ "GenSigSendType" SG_ 2463978663 VZE_Akustik_Limitwechsel_Status 0;
BA_ "GenSigSendType" SG_ 2463978663 VZE_Anhaenger_Vmax 3;
BA_ "GenSigStartValue" SG_ 2463978663 VZE_Anhaenger_Vmax 14;
BA_ "Fehlerwert" SG_ 2463978663 VZE_Anhaenger_Vmax 15;
BA_ "GenSigSendType" SG_ 2463978663 VZE_Anzeige_VZ_1 0;
BA_ "GenSigSwitchedByIgnition" SG_ 2463978663 VZE_Anzeige_VZ_1 0;
BA_ "GenSigSendType" SG_ 2463978663 VZE_Anzeige_VZ_2 0;
BA_ "GenSigSwitchedByIgnition" SG_ 2463978663 VZE_Anzeige_VZ_2 0;
BA_ "GenSigSendType" SG_ 2463978663 VZE_Anzeige_VZ_3 0;
BA_ "GenSigSwitchedByIgnition" SG_ 2463978663 VZE_Anzeige_VZ_3 0;
BA_ "GenSigSendType" SG_ 2463978663 VZE_Anzeige_ZS_1 0;
BA_ "GenSigSwitchedByIgnition" SG_ 2463978663 VZE_Anzeige_ZS_1 0;
BA_ "GenSigSendType" SG_ 2463978663 VZE_Anzeige_ZS_2 0;
BA_ "GenSigSwitchedByIgnition" SG_ 2463978663 VZE_Anzeige_ZS_2 0;
BA_ "GenSigSendType" SG_ 2463978663 VZE_Anzeige_ZS_3 0;
BA_ "GenSigSwitchedByIgnition" SG_ 2463978663 VZE_Anzeige_ZS_3 0;
BA_ "GenSigSendType" SG_ 2463978663 VZE_Anzeigemodus 3;
BA_ "GenSigSendType" SG_ 2463978663 VZE_Anzeigeunterdrueck_Zeichen_1 3;
BA_ "GenSigSendType" SG_ 2463978663 VZE_Anzeigeunterdrueck_Zeichen_2 3;
BA_ "GenSigSendType" SG_ 2463978663 VZE_Anzeigeunterdrueck_Zeichen_3 3;
BA_ "GenSigSendType" SG_ 2463978663 VZE_Anzeigeunterdrueck_Zeichen_4 3;
BA_ "GenSigSendType" SG_ 2463978663 VZE_Anzeigeunterdrueck_Zeichen_5 3;
BA_ "GenSigSendType" SG_ 2463978663 VZE_Baustelle 3;
BA_ "GenSigSendType" SG_ 2463978663 VZE_Erweiterte_Information 0;
BA_ "GenSigSendType" SG_ 2463978663 VZE_FoD_Status 0;
BA_ "GenSigSwitchedByIgnition" SG_ 2463978663 VZE_FoD_Status 0;
BA_ "GenSigSendType" SG_ 2463978663 VZE_Gong 3;
BA_ "GenSigSendType" SG_ 2463978663 VZE_Hinweistext 3;
BA_ "GenSigSendType" SG_ 2463978663 VZE_Hinweistext_03 0;
BA_ "GenSigSwitchedByIgnition" SG_ 2463978663 VZE_Hinweistext_03 0;
BA_ "GenSigSendType" SG_ 2463978663 VZE_Land 0;
BA_ "GenSigSwitchedByIgnition" SG_ 2463978663 VZE_Land 0;
BA_ "GenSigSendType" SG_ 2463978663 VZE_Modus_OptischeWarnung 0;
BA_ "GenSigSendType" SG_ 2463978663 VZE_SLWF_Status 0;
BA_ "GenSigSwitchedByIgnition" SG_ 2463978663 VZE_SLWF_Status 0;
BA_ "GenSigSendType" SG_ 2463978663 VZE_Tempowarnung_Einheit 0;
BA_ "GenSigSendType" SG_ 2463978663 VZE_Tempowarnung_Offset 0;
BA_ "GenSigSendType" SG_ 2463978663 VZE_Tempowarnung_Status 0;
BA_ "GenSigSwitchedByIgnition" SG_ 2463978663 VZE_Tempowarnung_Status 0;
BA_ "GenSigSendType" SG_ 2463978663 VZE_Umweltinfo_Anhaengerbetrieb 0;
BA_ "GenSigSendType" SG_ 2463978663 VZE_Umweltinfo_Naesse 0;
BA_ "GenSigSendType" SG_ 2463978663 VZE_Umweltinfo_Nebel 0;
BA_ "GenSigSendType" SG_ 2463978663 VZE_Verkehrszeichen_1 3;
BA_ "GenSigSendType" SG_ 2463978663 VZE_Verkehrszeichen_2 3;
BA_ "GenSigSendType" SG_ 2463978663 VZE_Verkehrszeichen_3 3;
BA_ "GenSigSendType" SG_ 2463978663 VZE_Verkehrszeichen_4 3;
BA_ "GenSigSendType" SG_ 2463978663 VZE_Verkehrszeichen_5 3;
BA_ "GenSigSendType" SG_ 2463978663 VZE_Verkehrszeichen_6 0;
BA_ "GenSigSendType" SG_ 2463978663 VZE_Verkehrszeichen_Einheit 3;
BA_ "GenSigSwitchedByIgnition" SG_ 2463978663 VZE_Verkehrszeichen_Einheit 0;
BA_ "GenSigSendType" SG_ 2463978663 VZE_Warnung_Verkehrszeichen_1 3;
BA_ "GenSigSendType" SG_ 2463978663 VZE_Warnung_Verkehrszeichen_2 3;
BA_ "GenSigSendType" SG_ 2463978663 VZE_Warnung_Verkehrszeichen_3 3;
BA_ "GenSigSendType" SG_ 2463978663 VZE_Warnung_Verkehrszeichen_4 3;
BA_ "GenSigSendType" SG_ 2463978663 VZE_Warnung_Verkehrszeichen_5 3;
BA_ "GenSigSendType" SG_ 2463978663 VZE_Warnung_VZ_1 0;
BA_ "GenSigSwitchedByIgnition" SG_ 2463978663 VZE_Warnung_VZ_1 0;
BA_ "GenSigSendType" SG_ 2463978663 VZE_Warnung_VZ_2 0;
BA_ "GenSigSwitchedByIgnition" SG_ 2463978663 VZE_Warnung_VZ_2 0;
BA_ "GenSigSendType" SG_ 2463978663 VZE_Warnung_VZ_3 0;
BA_ "GenSigSwitchedByIgnition" SG_ 2463978663 VZE_Warnung_VZ_3 0;
BA_ "GenSigSendType" SG_ 2463978663 VZE_Zeichen_01_Gesetz 3;
BA_ "GenSigSendType" SG_ 2463978663 VZE_Zeichen_01_Kamera 3;
BA_ "GenSigSendType" SG_ 2463978663 VZE_Zeichen_01_KameraWied 3;
BA_ "GenSigSendType" SG_ 2463978663 VZE_Zeichen_01_Karte 3;
BA_ "GenSigSendType" SG_ 2463978663 VZE_Zeichen_02_Gesetz 3;
BA_ "GenSigSendType" SG_ 2463978663 VZE_Zeichen_02_Kamera 3;
BA_ "GenSigSendType" SG_ 2463978663 VZE_Zeichen_02_KameraWied 3;
BA_ "GenSigSendType" SG_ 2463978663 VZE_Zeichen_02_Karte 3;
BA_ "GenSigSendType" SG_ 2463978663 VZE_Zeichen_03_Gesetz 3;
BA_ "GenSigSendType" SG_ 2463978663 VZE_Zeichen_03_Kamera 3;
BA_ "GenSigSendType" SG_ 2463978663 VZE_Zeichen_03_KameraWied 3;
BA_ "GenSigSendType" SG_ 2463978663 VZE_Zeichen_03_Karte 3;
BA_ "GenSigSendType" SG_ 2463978663 VZE_Zeichen_04_Gesetz 3;
BA_ "GenSigSendType" SG_ 2463978663 VZE_Zeichen_04_Kamera 3;
BA_ "GenSigSendType" SG_ 2463978663 VZE_Zeichen_04_KameraWied 3;
BA_ "GenSigSendType" SG_ 2463978663 VZE_Zeichen_04_Karte 3;
BA_ "GenSigSendType" SG_ 2463978663 VZE_Zeichen_05_Entfernung 0;
BA_ "GenSigSendType" SG_ 2463978663 VZE_Zeichen_05_Entfernung_StdA 0;
BA_ "GenSigSendType" SG_ 2463978663 VZE_Zeichen_05_Gesetz 3;
BA_ "GenSigSendType" SG_ 2463978663 VZE_Zeichen_05_Kamera 3;
BA_ "GenSigSendType" SG_ 2463978663 VZE_Zeichen_05_KameraWied 3;
BA_ "GenSigSendType" SG_ 2463978663 VZE_Zeichen_05_Karte 3;
BA_ "GenSigSendType" SG_ 2463978663 VZE_Zeichen_06_Entfernung 0;
BA_ "GenSigSendType" SG_ 2463978663 VZE_Zeichen_06_Entfernung_StdA 0;
BA_ "GenSigSendType" SG_ 2463978663 VZE_Zusatzschild_1 3;
BA_ "GenSigSendType" SG_ 2463978663 VZE_Zusatzschild_2 3;
BA_ "GenSigSendType" SG_ 2463978663 VZE_Zusatzschild_3 3;
BA_ "GenSigSendType" SG_ 2463978663 VZE_Zusatzschild_4 3;
BA_ "GenSigSendType" SG_ 2463978663 VZE_Zusatzschild_5 3;
BA_ "GenSigSendType" SG_ 2463978663 VZE_Zusatzschild_6 0;
BA_ "GenSigSwitchedByIgnition" SG_ 2589284014 VZE_ISA_Aktiv_Distanz 0;
BA_ "GenSigSwitchedByIgnition" SG_ 2589284014 VZE_ISA_Aktiv_Zeit 0;
BA_ "GenSigSwitchedByIgnition" SG_ 2589284014 VZE_ISA_Deaktivierung_Anzahl 0;
BA_ "GenSigSwitchedByIgnition" SG_ 2589284014 VZE_ISA_Inaktiv_Distanz 0;
BA_ "GenSigSwitchedByIgnition" SG_ 2589284014 VZE_ISA_Inaktiv_Zeit 0;
BA_ "GenSigSwitchedByIgnition" SG_ 2589284014 VZE_ISA_Limit_beachtet_Distanz 0;
BA_ "GenSigSwitchedByIgnition" SG_ 2589284014 VZE_ISA_Limit_beachtet_Zeit 0;
BA_ "GenSigSwitchedByIgnition" SG_ 2589284014 VZE_ISA_Limit_ueberschr_Distanz 0;
BA_ "GenSigSwitchedByIgnition" SG_ 2589284014 VZE_ISA_Limit_ueberschr_Zeit 0;
BA_ "GenSigSendType" SG_ 2589284014 VZE_ISA_Monitoring_Mux 0;
BA_ "GenSigSwitchedByIgnition" SG_ 2589284014 VZE_ISA_Monitoring_Mux 0;
BA_ "GenSigSendType" SG_ 2463978954 VZE_Ampel_Datenbasis_REM 0;
BA_ "GenSigSwitchedByIgnition" SG_ 2463978954 VZE_Ampel_Datenbasis_REM 0;
BA_ "GenSigSendType" SG_ 2463978954 VZE_Ampel_Datenbasis_Vision 0;
BA_ "GenSigSwitchedByIgnition" SG_ 2463978954 VZE_Ampel_Datenbasis_Vision 0;
BA_ "GenSigSendType" SG_ 2463978954 VZE_relevant_Stopp 0;
BA_ "GenSigSwitchedByIgnition" SG_ 2463978954 VZE_relevant_Stopp 0;
BA_ "Fehlerwert" SG_ 2463978954 VZE_relevant_Stopp 3;
BA_ "GenSigSendType" SG_ 2463978954 VZE_relevant_Stopp_Abstand 0;
BA_ "GenSigStartValue" SG_ 2463978954 VZE_relevant_Stopp_Abstand 511;
BA_ "GenSigSwitchedByIgnition" SG_ 2463978954 VZE_relevant_Stopp_Abstand 0;
BA_ "GenSigSendType" SG_ 2463978954 VZE_relevante_Ampel 0;
BA_ "GenSigSwitchedByIgnition" SG_ 2463978954 VZE_relevante_Ampel 0;
BA_ "GenSigSendType" SG_ 2463978954 VZE_relevante_Ampel_Abstand 0;
BA_ "GenSigStartValue" SG_ 2463978954 VZE_relevante_Ampel_Abstand 511;
BA_ "GenSigSwitchedByIgnition" SG_ 2463978954 VZE_relevante_Ampel_Abstand 0;
BA_ "GenSigSendType" SG_ 1361 WFS_Betrieb_Lesespule 3;
BA_ "GenSigSwitchedByIgnition" SG_ 1361 WFS_Betrieb_Lesespule 0;
BA_ "GenSigSendType" SG_ 1361 WFS_ELV_authorisiert 3;
BA_ "GenSigSwitchedByIgnition" SG_ 1361 WFS_ELV_authorisiert 0;
BA_ "GenSigSendType" SG_ 1361 WFS_Fahrerhinweise 3;
BA_ "GenSigSwitchedByIgnition" SG_ 1361 WFS_Fahrerhinweise 0;
BA_ "GenSigSendType" SG_ 1361 WFS_ID_Geb_autorisiert 3;
BA_ "GenSigSwitchedByIgnition" SG_ 1361 WFS_ID_Geb_autorisiert 0;
BA_ "GenSigSendType" SG_ 1361 WFS_ID_Geb_autorisiert_in_Kl15 3;
BA_ "GenSigSwitchedByIgnition" SG_ 1361 WFS_ID_Geb_autorisiert_in_Kl15 0;
BA_ "GenSigSendType" SG_ 1361 WFS_ID_Geb_steckt 3;
BA_ "GenSigSwitchedByIgnition" SG_ 1361 WFS_ID_Geb_steckt 0;
BA_ "GenSigSendType" SG_ 1361 WFS_Klemmenfreigabe 3;
BA_ "GenSigSwitchedByIgnition" SG_ 1361 WFS_Klemmenfreigabe 0;
BA_ "GenSigSendType" SG_ 1361 WFS_Klemmenfreigabe_Signatur 3;
BA_ "GenSigSwitchedByIgnition" SG_ 1361 WFS_Klemmenfreigabe_Signatur 0;
BA_ "GenSigSendType" SG_ 1361 WFS_LF_Aktiv 3;
BA_ "GenSigSwitchedByIgnition" SG_ 1361 WFS_LF_Aktiv 0;
BA_ "GenSigSendType" SG_ 1361 WFS_LZ 3;
BA_ "GenSigSwitchedByIgnition" SG_ 1361 WFS_LZ 0;
BA_ "GenSigSendType" SG_ 1361 WFS_LZ_02 3;
BA_ "GenSigSwitchedByIgnition" SG_ 1361 WFS_LZ_02 0;
BA_ "Fehlerwert" SG_ 1361 WFS_LZ_02 9;
BA_ "GenSigSendType" SG_ 1361 WFS_Parken_Status 3;
BA_ "GenSigSwitchedByIgnition" SG_ 1361 WFS_Parken_Status 0;
BA_ "GenSigSendType" SG_ 1361 WFS_Safe 3;
BA_ "GenSigSwitchedByIgnition" SG_ 1361 WFS_Safe 0;
BA_ "GenSigSendType" SG_ 1361 WFS_Schluessel_Fahrberecht 0;
BA_ "GenSigSwitchedByIgnition" SG_ 1361 WFS_Schluessel_Fahrberecht 0;
BA_ "GenSigSendType" SG_ 1361 WFS_Schluessel_Ist 3;
BA_ "GenSigSwitchedByIgnition" SG_ 1361 WFS_Schluessel_Ist 0;
BA_ "GenSigSendType" SG_ 1361 WFS_Schluessel_Soll 3;
BA_ "GenSigSwitchedByIgnition" SG_ 1361 WFS_Schluessel_Soll 0;
BA_ "GenSigSendType" SG_ 1361 WFS_Verbauinfo_ELV 3;
BA_ "GenSigSwitchedByIgnition" SG_ 1361 WFS_Verbauinfo_ELV 0;
BA_ "GenSigSendType" SG_ 1702 BCM1_SRA_aktiv 3;
BA_ "GenSigSwitchedByIgnition" SG_ 1702 BCM1_SRA_aktiv 0;
BA_ "GenSigSendType" SG_ 1702 Waschen_vorne_aktiv 3;
BA_ "GenSigSwitchedByIgnition" SG_ 1702 Waschen_vorne_aktiv 0;
BA_ "GenSigSendType" SG_ 1702 Wischer1_Wischgeschwindigkeit 0;
BA_ "GenSigStartValue" SG_ 1702 Wischer1_Wischgeschwindigkeit 62;
BA_ "GenSigSwitchedByIgnition" SG_ 1702 Wischer1_Wischgeschwindigkeit 0;
BA_ "Fehlerwert" SG_ 1702 Wischer1_Wischgeschwindigkeit 63;
BA_ "GenSigSendType" SG_ 1702 Wischer_Anzeigetext 3;
BA_ "GenSigSwitchedByIgnition" SG_ 1702 Wischer_Anzeigetext 0;
BA_ "GenSigSendType" SG_ 1702 Wischer_vorne_aktiv 3;
BA_ "GenSigSwitchedByIgnition" SG_ 1702 Wischer_vorne_aktiv 0;
BA_ "GenSigSendType" SG_ 1702 Wischer_vorne_blockiert 3;
BA_ "GenSigSwitchedByIgnition" SG_ 1702 Wischer_vorne_blockiert 0;
BA_ "GenSigSendType" SG_ 1702 Wischer_vorne_defekt 3;
BA_ "GenSigSwitchedByIgnition" SG_ 1702 Wischer_vorne_defekt 0;
BA_ "GenSigSendType" SG_ 1702 Wischer_vorne_Normal 3;
BA_ "GenSigSwitchedByIgnition" SG_ 1702 Wischer_vorne_Normal 0;
BA_ "GenSigSendType" SG_ 1702 Wischer_vorne_Parklage 3;
BA_ "GenSigStartValue" SG_ 1702 Wischer_vorne_Parklage 1;
BA_ "GenSigSwitchedByIgnition" SG_ 1702 Wischer_vorne_Parklage 0;
BA_ "GenSigSendType" SG_ 1702 Wischer_vorne_Schnell 3;
BA_ "GenSigSwitchedByIgnition" SG_ 1702 Wischer_vorne_Schnell 0;
BA_ "GenSigSendType" SG_ 1702 Wischer_WH_PopUp_Anf 3;
BA_ "GenSigSwitchedByIgnition" SG_ 1702 Wischer_WH_PopUp_Anf 0;
BA_ "GenSigSendType" SG_ 1702 Wischer_WH_Typ 0;
BA_ "GenSigSwitchedByIgnition" SG_ 1702 Wischer_WH_Typ 0;
BA_ "GenSigSendType" SG_ 1702 WWSs_01_alt 0;
BA_ "GenSigStartValue" SG_ 1702 WWSs_01_alt 1;
BA_ "GenSigFuncType" SG_ 1702 WWSs_01_alt 5;
BA_ "GenSigSwitchedByIgnition" SG_ 1702 WWSs_01_alt 0;
BA_ "GenSigSwitchedByIgnition" SG_ 2617163264 XCP_ACC_CRO_01_Data 0;
BA_ "GenSigSwitchedByIgnition" SG_ 2617163265 XCP_ACC_DTO_FF_Data 0;
BA_ "GenSigSwitchedByIgnition" SG_ 2617101824 XCP_MIK_CRO_01_Data 0;
BA_ "GenSigSwitchedByIgnition" SG_ 2617101825 XCP_MIK_DTO_01_Data 0;
BA_ "GenSigSendType" SG_ 1411 BCM_FH_Freigabe 3;
BA_ "GenSigSwitchedByIgnition" SG_ 1411 BCM_FH_Freigabe 0;
BA_ "GenSigSendType" SG_ 1411 BCM_HSK_Freigabe 3;
BA_ "GenSigSwitchedByIgnition" SG_ 1411 BCM_HSK_Freigabe 0;
BA_ "GenSigSendType" SG_ 1411 BCM_Komfortfkt_Freigabe 3;
BA_ "GenSigSwitchedByIgnition" SG_ 1411 BCM_Komfortfkt_Freigabe 0;
BA_ "GenSigSendType" SG_ 1411 BCM_Verdeck_Freigabe 3;
BA_ "GenSigSwitchedByIgnition" SG_ 1411 BCM_Verdeck_Freigabe 0;
BA_ "GenSigSendType" SG_ 1411 DWA_aktiv 3;
BA_ "GenSigSwitchedByIgnition" SG_ 1411 DWA_aktiv 0;
BA_ "GenSigSendType" SG_ 1411 FBS_IDG_in_Reichweite 6;
BA_ "GenSigSwitchedByIgnition" SG_ 1411 FBS_IDG_in_Reichweite 0;
BA_ "GenSigSendType" SG_ 1411 FBS_Warn_Schluessel_Batt 3;
BA_ "GenSigSwitchedByIgnition" SG_ 1411 FBS_Warn_Schluessel_Batt 0;
BA_ "GenSigSendType" SG_ 1411 FFB_Auf_Taste 6;
BA_ "GenSigSwitchedByIgnition" SG_ 1411 FFB_Auf_Taste 0;
BA_ "GenSigSendType" SG_ 1411 FFB_CarFinder 6;
BA_ "GenSigSwitchedByIgnition" SG_ 1411 FFB_CarFinder 0;
BA_ "GenSigSendType" SG_ 1411 FFB_HDF_Taste 6;
BA_ "GenSigSwitchedByIgnition" SG_ 1411 FFB_HDF_Taste 0;
BA_ "GenSigSendType" SG_ 1411 FFB_Komfortoeffnen 6;
BA_ "GenSigSwitchedByIgnition" SG_ 1411 FFB_Komfortoeffnen 0;
BA_ "GenSigSendType" SG_ 1411 FFB_Komfortschliessen 6;
BA_ "GenSigSwitchedByIgnition" SG_ 1411 FFB_Komfortschliessen 0;
BA_ "GenSigSendType" SG_ 1411 FFB_Panik_Taste 6;
BA_ "GenSigSwitchedByIgnition" SG_ 1411 FFB_Panik_Taste 0;
BA_ "GenSigSendType" SG_ 1411 FFB_Zu_Taste 6;
BA_ "GenSigSwitchedByIgnition" SG_ 1411 FFB_Zu_Taste 0;
BA_ "GenSigSendType" SG_ 1411 IRUE_aktiv 3;
BA_ "GenSigSwitchedByIgnition" SG_ 1411 IRUE_aktiv 0;
BA_ "GenSigSendType" SG_ 1411 IRUE_Taster_Fkts_LED 3;
BA_ "GenSigSwitchedByIgnition" SG_ 1411 IRUE_Taster_Fkts_LED 0;
BA_ "GenSigSendType" SG_ 1411 VIP_Sensor_STSG_HBFS_betaetigt 6;
BA_ "GenSigSwitchedByIgnition" SG_ 1411 VIP_Sensor_STSG_HBFS_betaetigt 0;
BA_ "GenSigSendType" SG_ 1411 VIP_Sensor_STSG_HFS_betaetigt 6;
BA_ "GenSigSwitchedByIgnition" SG_ 1411 VIP_Sensor_STSG_HFS_betaetigt 0;
BA_ "GenSigSendType" SG_ 1411 ZV_Anf_Challenge_Auth 6;
BA_ "GenSigSwitchedByIgnition" SG_ 1411 ZV_Anf_Challenge_Auth 0;
BA_ "GenSigSendType" SG_ 1411 ZV_BT_offen 3;
BA_ "GenSigSwitchedByIgnition" SG_ 1411 ZV_BT_offen 0;
BA_ "GenSigSendType" SG_ 1411 ZV_Einzeltuerentriegelung 3;
BA_ "GenSigSwitchedByIgnition" SG_ 1411 ZV_Einzeltuerentriegelung 0;
BA_ "GenSigSendType" SG_ 1411 ZV_eRWK_Umfeld_Pruefung 6;
BA_ "GenSigSwitchedByIgnition" SG_ 1411 ZV_eRWK_Umfeld_Pruefung 0;
BA_ "GenSigSendType" SG_ 1411 ZV_FT_offen 3;
BA_ "GenSigSwitchedByIgnition" SG_ 1411 ZV_FT_offen 0;
BA_ "GenSigSendType" SG_ 1411 ZV_gesafet_extern_ist 3;
BA_ "GenSigSwitchedByIgnition" SG_ 1411 ZV_gesafet_extern_ist 0;
BA_ "GenSigSendType" SG_ 1411 ZV_gesafet_extern_soll 3;
BA_ "GenSigSwitchedByIgnition" SG_ 1411 ZV_gesafet_extern_soll 0;
BA_ "GenSigSendType" SG_ 1411 ZV_HBFS_offen 3;
BA_ "GenSigSwitchedByIgnition" SG_ 1411 ZV_HBFS_offen 0;
BA_ "GenSigSendType" SG_ 1411 ZV_HD_offen 3;
BA_ "GenSigSwitchedByIgnition" SG_ 1411 ZV_HD_offen 0;
BA_ "GenSigSendType" SG_ 1411 ZV_Heckeinzelentriegelung 3;
BA_ "GenSigSwitchedByIgnition" SG_ 1411 ZV_Heckeinzelentriegelung 0;
BA_ "GenSigSendType" SG_ 1411 ZV_HFS_offen 3;
BA_ "GenSigSwitchedByIgnition" SG_ 1411 ZV_HFS_offen 0;
BA_ "GenSigSendType" SG_ 1411 ZV_HS_offen 3;
BA_ "GenSigSwitchedByIgnition" SG_ 1411 ZV_HS_offen 0;
BA_ "GenSigSendType" SG_ 1411 ZV_ist_Zustand_verfuegbar 3;
BA_ "GenSigSwitchedByIgnition" SG_ 1411 ZV_ist_Zustand_verfuegbar 0;
BA_ "GenSigSendType" SG_ 1411 ZV_Oeffnungsmodus 3;
BA_ "GenSigSwitchedByIgnition" SG_ 1411 ZV_Oeffnungsmodus 0;
BA_ "GenSigSendType" SG_ 1411 ZV_Rollo_auf 3;
BA_ "GenSigSwitchedByIgnition" SG_ 1411 ZV_Rollo_auf 0;
BA_ "GenSigSendType" SG_ 1411 ZV_Rollo_zu 3;
BA_ "GenSigSwitchedByIgnition" SG_ 1411 ZV_Rollo_zu 0;
BA_ "GenSigSendType" SG_ 1411 ZV_SAD_auf 3;
BA_ "GenSigSwitchedByIgnition" SG_ 1411 ZV_SAD_auf 0;
BA_ "GenSigSendType" SG_ 1411 ZV_SAD_zu 3;
BA_ "GenSigSwitchedByIgnition" SG_ 1411 ZV_SAD_zu 0;
BA_ "GenSigSendType" SG_ 1411 ZV_SafeFunktion_aktiv 3;
BA_ "GenSigSwitchedByIgnition" SG_ 1411 ZV_SafeFunktion_aktiv 0;
BA_ "GenSigSendType" SG_ 1411 ZV_Schluessel_Zugang 3;
BA_ "GenSigSwitchedByIgnition" SG_ 1411 ZV_Schluessel_Zugang 0;
BA_ "GenSigSendType" SG_ 1411 ZV_STSG_HBFS_Anf 3;
BA_ "GenSigSwitchedByIgnition" SG_ 1411 ZV_STSG_HBFS_Anf 0;
BA_ "GenSigSendType" SG_ 1411 ZV_STSG_HFS_Anf 3;
BA_ "GenSigSwitchedByIgnition" SG_ 1411 ZV_STSG_HFS_Anf 0;
BA_ "GenSigSendType" SG_ 1411 ZV_Tankklappe_offen 0;
BA_ "GenSigSwitchedByIgnition" SG_ 1411 ZV_Tankklappe_offen 0;
BA_ "GenSigSendType" SG_ 1411 ZV_verriegeln_Anf 6;
BA_ "GenSigSwitchedByIgnition" SG_ 1411 ZV_verriegeln_Anf 0;
BA_ "GenSigSendType" SG_ 1411 ZV_verriegelt_extern_ist 3;
BA_ "GenSigSwitchedByIgnition" SG_ 1411 ZV_verriegelt_extern_ist 0;
BA_ "GenSigSendType" SG_ 1411 ZV_verriegelt_extern_soll 3;
BA_ "GenSigSwitchedByIgnition" SG_ 1411 ZV_verriegelt_extern_soll 0;
BA_ "GenSigSendType" SG_ 1411 ZV_verriegelt_intern_ist 3;
BA_ "GenSigSwitchedByIgnition" SG_ 1411 ZV_verriegelt_intern_ist 0;
BA_ "GenSigSendType" SG_ 1411 ZV_verriegelt_intern_soll 3;
BA_ "GenSigSwitchedByIgnition" SG_ 1411 ZV_verriegelt_intern_soll 0;
BA_ "GenSigSendType" SG_ 1411 ZV_verriegelt_soll 3;
BA_ "GenSigSwitchedByIgnition" SG_ 1411 ZV_verriegelt_soll 0;
BA_REL_ "GenSigTimeoutTime" BU_SG_REL_ FASFrontradar SG_ 997 TSG_FT_02_CRC 1000;
BA_REL_ "GenSigTimeoutTime" BU_SG_REL_ FASFrontradar SG_ 997 TSG_FT_02_BZ 1000;
BA_REL_ "GenSigTimeoutTime" BU_SG_REL_ FASFrontradar SG_ 997 FT_Tuer_Status 1000;
BA_REL_ "GenSigTimeoutTime" BU_SG_REL_ FASFrontradar SG_ 1019 TSK_Ausrollkurve_Schub_Reku_01 800;
BA_REL_ "GenSigTimeoutTime" BU_SG_REL_ FASFrontradar SG_ 1019 TSK_Ausrollkurve_Schub_Reku_05 800;
BA_REL_ "GenSigTimeoutTime" BU_SG_REL_ FASFrontradar SG_ 1019 TSK_Ausrollkurve_Schub_Reku_09 800;
BA_REL_ "GenSigTimeoutTime" BU_SG_REL_ FASFrontradar SG_ 1019 TSK_Ausrollkurve_Schub_Reku_13 800;
BA_REL_ "GenSigTimeoutTime" BU_SG_REL_ FASFrontradar SG_ 1019 TSK_Ausrollkurve_Schub_Reku_17 800;
BA_REL_ "GenSigTimeoutTime" BU_SG_REL_ FASFrontradar SG_ 1019 TSK_Ausrollkurve_Schub_Reku_02 800;
BA_REL_ "GenSigTimeoutTime" BU_SG_REL_ FASFrontradar SG_ 1019 TSK_Ausrollkurve_Schub_Reku_06 800;
BA_REL_ "GenSigTimeoutTime" BU_SG_REL_ FASFrontradar SG_ 1019 TSK_Ausrollkurve_Schub_Reku_10 800;
BA_REL_ "GenSigTimeoutTime" BU_SG_REL_ FASFrontradar SG_ 1019 TSK_Ausrollkurve_Schub_Reku_14 800;
BA_REL_ "GenSigTimeoutTime" BU_SG_REL_ FASFrontradar SG_ 1019 TSK_Ausrollkurve_Schub_Reku_18 800;
BA_REL_ "GenSigTimeoutTime" BU_SG_REL_ FASFrontradar SG_ 1019 TSK_Ausrollkurve_Schub_Reku_03 800;
BA_REL_ "GenSigTimeoutTime" BU_SG_REL_ FASFrontradar SG_ 1019 TSK_Ausrollkurve_Schub_Reku_07 800;
BA_REL_ "GenSigTimeoutTime" BU_SG_REL_ FASFrontradar SG_ 1019 TSK_Ausrollkurve_Schub_Reku_11 800;
BA_REL_ "GenSigTimeoutTime" BU_SG_REL_ FASFrontradar SG_ 1019 TSK_Ausrollkurve_Schub_Reku_15 800;
BA_REL_ "GenSigTimeoutTime" BU_SG_REL_ FASFrontradar SG_ 1019 TSK_Ausrollkurve_Schub_Reku_19 800;
BA_REL_ "GenSigTimeoutTime" BU_SG_REL_ FASFrontradar SG_ 1019 TSK_Ausrollkurve_Schub_Reku_04 800;
BA_REL_ "GenSigTimeoutTime" BU_SG_REL_ FASFrontradar SG_ 1019 TSK_Ausrollkurve_Schub_Reku_08 800;
BA_REL_ "GenSigTimeoutTime" BU_SG_REL_ FASFrontradar SG_ 1019 TSK_Ausrollkurve_Schub_Reku_12 800;
BA_REL_ "GenSigTimeoutTime" BU_SG_REL_ FASFrontradar SG_ 1019 TSK_Ausrollkurve_Schub_Reku_16 800;
BA_REL_ "GenSigTimeoutTime" BU_SG_REL_ FASFrontradar SG_ 1019 TSK_Ausrollkurve_Schub_Reku_20 800;
BA_REL_ "GenSigTimeoutTime" BU_SG_REL_ FASFrontradar SG_ 1019 TSK_Ausrollkurve_Segeln_01 800;
BA_REL_ "GenSigTimeoutTime" BU_SG_REL_ FASFrontradar SG_ 1019 TSK_Ausrollkurve_Segeln_05 800;
BA_REL_ "GenSigTimeoutTime" BU_SG_REL_ FASFrontradar SG_ 1019 TSK_Ausrollkurve_Segeln_09 800;
BA_REL_ "GenSigTimeoutTime" BU_SG_REL_ FASFrontradar SG_ 1019 TSK_Ausrollkurve_Segeln_13 800;
BA_REL_ "GenSigTimeoutTime" BU_SG_REL_ FASFrontradar SG_ 1019 TSK_Ausrollkurve_Segeln_17 800;
BA_REL_ "GenSigTimeoutTime" BU_SG_REL_ FASFrontradar SG_ 1019 TSK_Ausrollkurve_Segeln_02 800;
BA_REL_ "GenSigTimeoutTime" BU_SG_REL_ FASFrontradar SG_ 1019 TSK_Ausrollkurve_Segeln_06 800;
BA_REL_ "GenSigTimeoutTime" BU_SG_REL_ FASFrontradar SG_ 1019 TSK_Ausrollkurve_Segeln_10 800;
BA_REL_ "GenSigTimeoutTime" BU_SG_REL_ FASFrontradar SG_ 1019 TSK_Ausrollkurve_Segeln_14 800;
BA_REL_ "GenSigTimeoutTime" BU_SG_REL_ FASFrontradar SG_ 1019 TSK_Ausrollkurve_Segeln_18 800;
BA_REL_ "GenSigTimeoutTime" BU_SG_REL_ FASFrontradar SG_ 1019 TSK_Ausrollkurve_Segeln_03 800;
BA_REL_ "GenSigTimeoutTime" BU_SG_REL_ FASFrontradar SG_ 1019 TSK_Ausrollkurve_Segeln_07 800;
BA_REL_ "GenSigTimeoutTime" BU_SG_REL_ FASFrontradar SG_ 1019 TSK_Ausrollkurve_Segeln_11 800;
BA_REL_ "GenSigTimeoutTime" BU_SG_REL_ FASFrontradar SG_ 1019 TSK_Ausrollkurve_Segeln_15 800;
BA_REL_ "GenSigTimeoutTime" BU_SG_REL_ FASFrontradar SG_ 1019 TSK_Ausrollkurve_Segeln_19 800;
BA_REL_ "GenSigTimeoutTime" BU_SG_REL_ FASFrontradar SG_ 1019 TSK_Ausrollkurve_Segeln_04 800;
BA_REL_ "GenSigTimeoutTime" BU_SG_REL_ FASFrontradar SG_ 1019 TSK_Ausrollkurve_Segeln_08 800;
BA_REL_ "GenSigTimeoutTime" BU_SG_REL_ FASFrontradar SG_ 1019 TSK_Ausrollkurve_Segeln_12 800;
BA_REL_ "GenSigTimeoutTime" BU_SG_REL_ FASFrontradar SG_ 1019 TSK_Ausrollkurve_Segeln_16 800;
BA_REL_ "GenSigTimeoutTime" BU_SG_REL_ FASFrontradar SG_ 1019 TSK_Ausrollkurve_Segeln_20 800;
BA_REL_ "GenSigTimeoutTime" BU_SG_REL_ FASFrontradar SG_ 1019 TSK_Ausrollkurve_Mux 800;
BA_REL_ "GenSigTimeoutTime" BU_SG_REL_ FASFrontradar SG_ 1019 TSK_Ausrollkurve_Reku 800;
BA_REL_ "GenSigTimeoutTime" BU_SG_REL_ FASFrontradar SG_ 1019 TSK_Ausrollkurve_Schrittweite 800;
BA_REL_ "GenSigTimeoutTime" BU_SG_REL_ FASFrontradar SG_ 1019 TSK_Ausrollkurve_Zaehler 800;
BA_REL_ "GenSigTimeoutTime" BU_SG_REL_ FASFrontradar SG_ 1716 VIN_01_MUX 2000;
BA_REL_ "GenSigTimeoutTime" BU_SG_REL_ FASFrontradar SG_ 1716 KS_Geheimnis_1 2000;
BA_REL_ "GenSigTimeoutTime" BU_SG_REL_ FASFrontradar SG_ 1716 VIN_4 2000;
BA_REL_ "GenSigTimeoutTime" BU_SG_REL_ FASFrontradar SG_ 1716 VIN_11 2000;
BA_REL_ "GenSigTimeoutTime" BU_SG_REL_ FASFrontradar SG_ 1716 KS_Geheimnis_2 2000;
BA_REL_ "GenSigTimeoutTime" BU_SG_REL_ FASFrontradar SG_ 1716 VIN_5 2000;
BA_REL_ "GenSigTimeoutTime" BU_SG_REL_ FASFrontradar SG_ 1716 VIN_12 2000;
BA_REL_ "GenSigTimeoutTime" BU_SG_REL_ FASFrontradar SG_ 1716 KS_Geheimnis_3 2000;
BA_REL_ "GenSigTimeoutTime" BU_SG_REL_ FASFrontradar SG_ 1716 VIN_6 2000;
BA_REL_ "GenSigTimeoutTime" BU_SG_REL_ FASFrontradar SG_ 1716 VIN_13 2000;
BA_REL_ "GenSigTimeoutTime" BU_SG_REL_ FASFrontradar SG_ 1716 KS_Geheimnis_4 2000;
BA_REL_ "GenSigTimeoutTime" BU_SG_REL_ FASFrontradar SG_ 1716 VIN_7 2000;
BA_REL_ "GenSigTimeoutTime" BU_SG_REL_ FASFrontradar SG_ 1716 VIN_14 2000;
BA_REL_ "GenSigTimeoutTime" BU_SG_REL_ FASFrontradar SG_ 1716 VIN_1 2000;
BA_REL_ "GenSigTimeoutTime" BU_SG_REL_ FASFrontradar SG_ 1716 VIN_8 2000;
BA_REL_ "GenSigTimeoutTime" BU_SG_REL_ FASFrontradar SG_ 1716 VIN_15 2000;
BA_REL_ "GenSigTimeoutTime" BU_SG_REL_ FASFrontradar SG_ 1716 VIN_2 2000;
BA_REL_ "GenSigTimeoutTime" BU_SG_REL_ FASFrontradar SG_ 1716 VIN_9 2000;
BA_REL_ "GenSigTimeoutTime" BU_SG_REL_ FASFrontradar SG_ 1716 VIN_16 2000;
BA_REL_ "GenSigTimeoutTime" BU_SG_REL_ FASFrontradar SG_ 1716 VIN_3 2000;
BA_REL_ "GenSigTimeoutTime" BU_SG_REL_ FASFrontradar SG_ 1716 VIN_10 2000;
BA_REL_ "GenSigTimeoutTime" BU_SG_REL_ FASFrontradar SG_ 1716 VIN_17 2000;
BA_REL_ "GenSigTimeoutTime" BU_SG_REL_ FASFrontradar SG_ 313 VMM_02_CRC 500;
BA_REL_ "GenSigTimeoutTime" BU_SG_REL_ FASFrontradar SG_ 313 VMM_02_BZ 500;
BA_REL_ "GenSigTimeoutTime" BU_SG_REL_ FASFrontradar SG_ 313 VZM_aktiver_Basisservice 500;
BA_REL_ "GenSigTimeoutTime" BU_SG_REL_ FASFrontradar SG_ 313 VZM_Anhalteweg_nicht_verfuegbar 500;
BA_REL_ "GenSigTimeoutTime" BU_SG_REL_ FASFrontradar SG_ 313 VZM_Fahrer_bremst 500;
BA_REL_ "GenSigTimeoutTime" BU_SG_REL_ FASFrontradar SG_ 313 VZM_QBit_Fahrer_bremst 500;
BA_REL_ "GenSigTimeoutTime" BU_SG_REL_ FASFrontradar SG_ 313 VZM_Warnruck_nicht_verfuegbar 500;
BA_REL_ "GenSigTimeoutTime" BU_SG_REL_ FASFrontradar SG_ 313 VZM_Bkd_nicht_verfuegbar 500;
BA_REL_ "GenSigTimeoutTime" BU_SG_REL_ FASFrontradar SG_ 313 VMM_Bremslicht_defekt 500;
BA_REL_ "GenSigTimeoutTime" BU_SG_REL_ FASFrontradar SG_ 313 VZM_Fahrer_bremst_deutlich 500;
BA_REL_ "GenSigTimeoutTime" BU_SG_REL_ FASFrontradar SG_ 313 VZM_Verz_Reg_nicht_verfuegbar 500;
BA_REL_ "GenSigTimeoutTime" BU_SG_REL_ FASFrontradar SG_ 313 VMM_Bremslicht_unplausibel 500;
BA_REL_ "GenSigTimeoutTime" BU_SG_REL_ FASFrontradar SG_ 313 VMM_Inkonsistenz_ACC 500;
BA_REL_ "GenSigTimeoutTime" BU_SG_REL_ FASFrontradar SG_ 313 VMM_Inkonsistenz_AWV_PCF 500;
BA_REL_ "GenSigTimeoutTime" BU_SG_REL_ FASFrontradar SG_ 313 VMM_Fahrer_Bremskraft_bestimmend 500;
BA_REL_ "GenSigTimeoutTime" BU_SG_REL_ FASFrontradar SG_ 313 VZM_Verz_ASIL_Verfuegbarkeit 500;
BA_REL_ "GenSigTimeoutTime" BU_SG_REL_ FASFrontradar SG_ 313 VZM_aktives_System 500;
BA_REL_ "GenSigTimeoutTime" BU_SG_REL_ FASFrontradar SG_ 313 VZM_Verz_Begrenzung 500;
BA_REL_ "GenSigTimeoutTime" BU_SG_REL_ FASFrontradar SG_ 313 VZM_Systemstatus 500;
BA_REL_ "GenSigTimeoutTime" BU_SG_REL_ FASFrontradar SG_ 313 HMS_halten_nicht_verfuegbar 500;
BA_REL_ "GenSigTimeoutTime" BU_SG_REL_ FASFrontradar SG_ 313 HMS_parken_nicht_verfuegbar 500;
BA_REL_ "GenSigTimeoutTime" BU_SG_REL_ FASFrontradar SG_ 313 HMS_Systemstatus 500;
BA_REL_ "GenSigTimeoutTime" BU_SG_REL_ FASFrontradar SG_ 313 HMS_Stillstand 500;
BA_REL_ "GenSigTimeoutTime" BU_SG_REL_ FASFrontradar SG_ 313 HMS_aktives_System 500;
BA_REL_ "GenSigTimeoutTime" BU_SG_REL_ FASFrontradar SG_ 313 HMS_Fehlerstatus 500;
BA_REL_ "GenSigTimeoutTime" BU_SG_REL_ FASFrontradar SG_ 2463978663 VZE_Anzeigemodus 2000;
BA_REL_ "GenSigTimeoutTime" BU_SG_REL_ FASFrontradar SG_ 2463978663 VZE_Hinweistext 2000;
BA_REL_ "GenSigTimeoutTime" BU_SG_REL_ FASFrontradar SG_ 2463978663 VZE_Verkehrszeichen_1 2000;
BA_REL_ "GenSigTimeoutTime" BU_SG_REL_ FASFrontradar SG_ 2463978663 VZE_Verkehrszeichen_2 2000;
BA_REL_ "GenSigTimeoutTime" BU_SG_REL_ FASFrontradar SG_ 2463978663 VZE_Verkehrszeichen_3 2000;
BA_REL_ "GenSigTimeoutTime" BU_SG_REL_ FASFrontradar SG_ 2463978663 VZE_Warnung_Verkehrszeichen_1 2000;
BA_REL_ "GenSigTimeoutTime" BU_SG_REL_ FASFrontradar SG_ 2463978663 VZE_Warnung_Verkehrszeichen_2 2000;
BA_REL_ "GenSigTimeoutTime" BU_SG_REL_ FASFrontradar SG_ 2463978663 VZE_Warnung_Verkehrszeichen_3 2000;
BA_REL_ "GenSigTimeoutTime" BU_SG_REL_ FASFrontradar SG_ 2463978663 VZE_Zusatzschild_1 2000;
BA_REL_ "GenSigTimeoutTime" BU_SG_REL_ FASFrontradar SG_ 2463978663 VZE_Zusatzschild_2 2000;
BA_REL_ "GenSigTimeoutTime" BU_SG_REL_ FASFrontradar SG_ 2463978663 VZE_Zusatzschild_3 2000;
BA_REL_ "GenSigTimeoutTime" BU_SG_REL_ FASFrontradar SG_ 2463978663 VZE_Anzeigeunterdrueck_Zeichen_1 2000;
BA_REL_ "GenSigTimeoutTime" BU_SG_REL_ FASFrontradar SG_ 2463978663 VZE_Zeichen_01_KameraWied 2000;
BA_REL_ "GenSigTimeoutTime" BU_SG_REL_ FASFrontradar SG_ 2463978663 VZE_Zeichen_02_KameraWied 2000;
BA_REL_ "GenSigTimeoutTime" BU_SG_REL_ FASFrontradar SG_ 2463978663 VZE_Zeichen_03_KameraWied 2000;
BA_REL_ "GenSigTimeoutTime" BU_SG_REL_ FASFrontradar SG_ 2463978663 VZE_Zeichen_01_Kamera 2000;
BA_REL_ "GenSigTimeoutTime" BU_SG_REL_ FASFrontradar SG_ 2463978663 VZE_Zeichen_01_Karte 2000;
BA_REL_ "GenSigTimeoutTime" BU_SG_REL_ FASFrontradar SG_ 2463978663 VZE_Zeichen_01_Gesetz 2000;
BA_REL_ "GenSigTimeoutTime" BU_SG_REL_ FASFrontradar SG_ 2463978663 VZE_Zeichen_02_Kamera 2000;
BA_REL_ "GenSigTimeoutTime" BU_SG_REL_ FASFrontradar SG_ 2463978663 VZE_Zeichen_02_Karte 2000;
BA_REL_ "GenSigTimeoutTime" BU_SG_REL_ FASFrontradar SG_ 2463978663 VZE_Zeichen_02_Gesetz 2000;
BA_REL_ "GenSigTimeoutTime" BU_SG_REL_ FASFrontradar SG_ 2463978663 VZE_Zeichen_03_Kamera 2000;
BA_REL_ "GenSigTimeoutTime" BU_SG_REL_ FASFrontradar SG_ 2463978663 VZE_Zeichen_03_Karte 2000;
BA_REL_ "GenSigTimeoutTime" BU_SG_REL_ FASFrontradar SG_ 2463978663 VZE_Zeichen_03_Gesetz 2000;
BA_REL_ "GenSigTimeoutTime" BU_SG_REL_ FASFrontradar SG_ 2463978663 VZE_Gong 2000;
BA_REL_ "GenSigTimeoutTime" BU_SG_REL_ FASFrontradar SG_ 2463978663 VZE_Zeichen_05_KameraWied 2000;
BA_REL_ "GenSigTimeoutTime" BU_SG_REL_ FASFrontradar SG_ 2463978663 VZE_Zeichen_05_Kamera 2000;
BA_REL_ "GenSigTimeoutTime" BU_SG_REL_ FASFrontradar SG_ 2463978663 VZE_Verkehrszeichen_4 2000;
BA_REL_ "GenSigTimeoutTime" BU_SG_REL_ FASFrontradar SG_ 2463978663 VZE_Verkehrszeichen_5 2000;
BA_REL_ "GenSigTimeoutTime" BU_SG_REL_ FASFrontradar SG_ 2463978663 VZE_Anhaenger_Vmax 2000;
BA_REL_ "GenSigTimeoutTime" BU_SG_REL_ FASFrontradar SG_ 2463978663 VZE_Warnung_Verkehrszeichen_4 2000;
BA_REL_ "GenSigTimeoutTime" BU_SG_REL_ FASFrontradar SG_ 2463978663 VZE_Warnung_Verkehrszeichen_5 2000;
BA_REL_ "GenSigTimeoutTime" BU_SG_REL_ FASFrontradar SG_ 2463978663 VZE_Zusatzschild_4 2000;
BA_REL_ "GenSigTimeoutTime" BU_SG_REL_ FASFrontradar SG_ 2463978663 VZE_Zusatzschild_5 2000;
BA_REL_ "GenSigTimeoutTime" BU_SG_REL_ FASFrontradar SG_ 2463978663 VZE_Baustelle 2000;
BA_REL_ "GenSigTimeoutTime" BU_SG_REL_ FASFrontradar SG_ 2463978663 VZE_Zeichen_05_Entfernung 2000;
BA_REL_ "GenSigTimeoutTime" BU_SG_REL_ FASFrontradar SG_ 2463978663 VZE_Zeichen_05_Entfernung_StdA 2000;
BA_REL_ "GenSigTimeoutTime" BU_SG_REL_ FASFrontradar SG_ 2463978663 VZE_Verkehrszeichen_6 2000;
BA_REL_ "GenSigTimeoutTime" BU_SG_REL_ FASFrontradar SG_ 2463978663 VZE_Zusatzschild_6 2000;
BA_REL_ "GenSigTimeoutTime" BU_SG_REL_ FASFrontradar SG_ 2463978663 VZE_Zeichen_06_Entfernung 2000;
BA_REL_ "GenSigTimeoutTime" BU_SG_REL_ FASFrontradar SG_ 2463978663 VZE_Zeichen_06_Entfernung_StdA 2000;
BA_REL_ "GenSigTimeoutTime" BU_SG_REL_ FASFrontradar SG_ 2463978663 VZE_Umweltinfo_Naesse 2000;
BA_REL_ "GenSigTimeoutTime" BU_SG_REL_ FASFrontradar SG_ 2463978663 VZE_Umweltinfo_Nebel 2000;
BA_REL_ "GenSigTimeoutTime" BU_SG_REL_ FASFrontradar SG_ 2463978663 VZE_Umweltinfo_Anhaengerbetrieb 2000;
BA_REL_ "GenSigTimeoutTime" BU_SG_REL_ FASFrontradar SG_ 2463978663 VZE_Erweiterte_Information 2000;
BA_REL_ "GenSigTimeoutTime" BU_SG_REL_ FASFrontradar SG_ 2463978663 VZE_Tempowarnung_Status 2000;
BA_REL_ "GenSigTimeoutTime" BU_SG_REL_ FASFrontradar SG_ 2463978663 VZE_Tempowarnung_Einheit 2000;
BA_REL_ "GenSigTimeoutTime" BU_SG_REL_ FASFrontradar SG_ 2463978663 VZE_Tempowarnung_Offset 2000;
BA_REL_ "GenSigTimeoutTime" BU_SG_REL_ FASFrontradar SG_ 2463978663 VZE_FoD_Status 2000;
BA_REL_ "GenSigTimeoutTime" BU_SG_REL_ FASFrontradar SG_ 1411 ZV_BT_offen 2000;
BA_REL_ "GenSigTimeoutTime" BU_SG_REL_ FASFrontradar SG_ 1411 ZV_HFS_offen 2000;
BA_REL_ "GenSigTimeoutTime" BU_SG_REL_ FASFrontradar SG_ 1411 ZV_HBFS_offen 2000;
BA_REL_ "GenSigTimeoutTime" BU_SG_REL_ ICAS1_X_Gateway SG_ 2463978663 VZE_Hinweistext 2000;
BA_REL_ "GenSigTimeoutTime" BU_SG_REL_ ICAS1_X_Gateway SG_ 2463978663 VZE_Akustik_Limitwechsel 2000;
BA_REL_ "GenSigTimeoutTime" BU_SG_REL_ ICAS1_X_Gateway SG_ 2463978663 VZE_Verkehrszeichen_Einheit 2000;
BA_REL_ "GenSigTimeoutTime" BU_SG_REL_ ICAS1_X_Gateway SG_ 2463978663 VZE_Verkehrszeichen_1 2000;
BA_REL_ "GenSigTimeoutTime" BU_SG_REL_ ICAS1_X_Gateway SG_ 2463978663 VZE_Warnung_Verkehrszeichen_1 2000;
BA_REL_ "GenSigTimeoutTime" BU_SG_REL_ ICAS1_X_Gateway SG_ 2463978663 VZE_Gong 2000;
BA_REL_ "GenSigTimeoutTime" BU_SG_REL_ ICAS1_X_Gateway SG_ 2463978663 VZE_SLWF_Status 2000;
BA_REL_ "GenSigTimeoutTime" BU_SG_REL_ MFK SG_ 997 FT_Tuer_Status 1000;
BA_REL_ "GenSigTimeoutTime" BU_SG_REL_ MFK SG_ 997 FT_Tuer_Status_QBit 1000;
BA_REL_ "GenSigTimeoutTime" BU_SG_REL_ MFK SG_ 2463978710 OPS_DriverPresenceStatus 1000;
BA_REL_ "GenSigTimeoutTime" BU_SG_REL_ MFK SG_ 2463978710 OPS_SafeDriverPresenceStatus 1000;
BA_REL_ "GenSigTimeoutTime" BU_SG_REL_ MFK SG_ 1716 VIN_01_MUX 2000;
BA_REL_ "GenSigTimeoutTime" BU_SG_REL_ MFK SG_ 1716 VIN_4 2000;
BA_REL_ "GenSigTimeoutTime" BU_SG_REL_ MFK SG_ 1716 VIN_11 2000;
BA_REL_ "GenSigTimeoutTime" BU_SG_REL_ MFK SG_ 1716 VIN_5 2000;
BA_REL_ "GenSigTimeoutTime" BU_SG_REL_ MFK SG_ 1716 VIN_12 2000;
BA_REL_ "GenSigTimeoutTime" BU_SG_REL_ MFK SG_ 1716 VIN_6 2000;
BA_REL_ "GenSigTimeoutTime" BU_SG_REL_ MFK SG_ 1716 VIN_13 2000;
BA_REL_ "GenSigTimeoutTime" BU_SG_REL_ MFK SG_ 1716 VIN_7 2000;
BA_REL_ "GenSigTimeoutTime" BU_SG_REL_ MFK SG_ 1716 VIN_14 2000;
BA_REL_ "GenSigTimeoutTime" BU_SG_REL_ MFK SG_ 1716 VIN_1 2000;
BA_REL_ "GenSigTimeoutTime" BU_SG_REL_ MFK SG_ 1716 VIN_8 2000;
BA_REL_ "GenSigTimeoutTime" BU_SG_REL_ MFK SG_ 1716 VIN_15 2000;
BA_REL_ "GenSigTimeoutTime" BU_SG_REL_ MFK SG_ 1716 VIN_2 2000;
BA_REL_ "GenSigTimeoutTime" BU_SG_REL_ MFK SG_ 1716 VIN_9 2000;
BA_REL_ "GenSigTimeoutTime" BU_SG_REL_ MFK SG_ 1716 VIN_16 2000;
BA_REL_ "GenSigTimeoutTime" BU_SG_REL_ MFK SG_ 1716 VIN_3 2000;
BA_REL_ "GenSigTimeoutTime" BU_SG_REL_ MFK SG_ 1716 VIN_10 2000;
BA_REL_ "GenSigTimeoutTime" BU_SG_REL_ MFK SG_ 1716 VIN_17 2000;
BA_REL_ "GenSigTimeoutTime" BU_SG_REL_ MFK SG_ 313 VZM_aktiver_Basisservice 500;
BA_REL_ "GenSigTimeoutTime" BU_SG_REL_ MFK SG_ 313 VZM_Fahrer_bremst 500;
BA_REL_ "GenSigTimeoutTime" BU_SG_REL_ MFK SG_ 313 VZM_QBit_Fahrer_bremst 500;
BA_REL_ "GenSigTimeoutTime" BU_SG_REL_ MFK SG_ 313 VZM_Warnruck_nicht_verfuegbar 500;
BA_REL_ "GenSigTimeoutTime" BU_SG_REL_ MFK SG_ 313 VZM_Warnruckeln_nicht_verfuegbar 500;
BA_REL_ "GenSigTimeoutTime" BU_SG_REL_ MFK SG_ 313 VZM_Fahrer_bremst_deutlich 500;
BA_REL_ "GenSigTimeoutTime" BU_SG_REL_ MFK SG_ 313 VZM_Verz_Reg_aktiv 500;
BA_REL_ "GenSigTimeoutTime" BU_SG_REL_ MFK SG_ 313 VMM_Inkonsistenz_AWV_PCF 500;
BA_REL_ "GenSigTimeoutTime" BU_SG_REL_ MFK SG_ 313 VMM_Fahrer_Bremskraft_bestimmend 500;
BA_REL_ "GenSigTimeoutTime" BU_SG_REL_ MFK SG_ 313 VMM_Inkonsistenz_EA 500;
BA_REL_ "GenSigTimeoutTime" BU_SG_REL_ MFK SG_ 313 VZM_Verz_ASIL_Verfuegbarkeit 500;
BA_REL_ "GenSigTimeoutTime" BU_SG_REL_ MFK SG_ 313 VZM_aktives_System 500;
BA_REL_ "GenSigTimeoutTime" BU_SG_REL_ MFK SG_ 313 HMS_Systemstatus 500;
BA_REL_ "GenSigTimeoutTime" BU_SG_REL_ MFK SG_ 313 HMS_Stillstand 500;
BA_REL_ "GenSigTimeoutTime" BU_SG_REL_ MFK SG_ 313 HMS_aktives_System 500;
BA_REL_ "GenSigTimeoutTime" BU_SG_REL_ MFK SG_ 1361 WFS_Schluessel_Fahrberecht 2000;
BA_REL_ "GenSigTimeoutTime" BU_SG_REL_ MFK SG_ 1411 ZV_Schluessel_Zugang 2000;
BA_REL_ "GenSigTimeoutTime" BU_SG_REL_ MFK120 SG_ 997 FT_Tuer_Status 1000;
BA_REL_ "GenSigTimeoutTime" BU_SG_REL_ MFK120 SG_ 997 FT_Tuer_Status_QBit 1000;
BA_REL_ "GenSigTimeoutTime" BU_SG_REL_ MFK120 SG_ 2463978710 OPS_DriverPresenceStatus 1000;
BA_REL_ "GenSigTimeoutTime" BU_SG_REL_ MFK120 SG_ 2463978710 OPS_SafeDriverPresenceStatus 1000;
BA_REL_ "GenSigTimeoutTime" BU_SG_REL_ MFK120 SG_ 1716 VIN_01_MUX 2000;
BA_REL_ "GenSigTimeoutTime" BU_SG_REL_ MFK120 SG_ 1716 VIN_4 2000;
BA_REL_ "GenSigTimeoutTime" BU_SG_REL_ MFK120 SG_ 1716 VIN_11 2000;
BA_REL_ "GenSigTimeoutTime" BU_SG_REL_ MFK120 SG_ 1716 VIN_5 2000;
BA_REL_ "GenSigTimeoutTime" BU_SG_REL_ MFK120 SG_ 1716 VIN_12 2000;
BA_REL_ "GenSigTimeoutTime" BU_SG_REL_ MFK120 SG_ 1716 VIN_6 2000;
BA_REL_ "GenSigTimeoutTime" BU_SG_REL_ MFK120 SG_ 1716 VIN_13 2000;
BA_REL_ "GenSigTimeoutTime" BU_SG_REL_ MFK120 SG_ 1716 VIN_7 2000;
BA_REL_ "GenSigTimeoutTime" BU_SG_REL_ MFK120 SG_ 1716 VIN_14 2000;
BA_REL_ "GenSigTimeoutTime" BU_SG_REL_ MFK120 SG_ 1716 VIN_1 2000;
BA_REL_ "GenSigTimeoutTime" BU_SG_REL_ MFK120 SG_ 1716 VIN_8 2000;
BA_REL_ "GenSigTimeoutTime" BU_SG_REL_ MFK120 SG_ 1716 VIN_15 2000;
BA_REL_ "GenSigTimeoutTime" BU_SG_REL_ MFK120 SG_ 1716 VIN_2 2000;
BA_REL_ "GenSigTimeoutTime" BU_SG_REL_ MFK120 SG_ 1716 VIN_9 2000;
BA_REL_ "GenSigTimeoutTime" BU_SG_REL_ MFK120 SG_ 1716 VIN_16 2000;
BA_REL_ "GenSigTimeoutTime" BU_SG_REL_ MFK120 SG_ 1716 VIN_3 2000;
BA_REL_ "GenSigTimeoutTime" BU_SG_REL_ MFK120 SG_ 1716 VIN_10 2000;
BA_REL_ "GenSigTimeoutTime" BU_SG_REL_ MFK120 SG_ 1716 VIN_17 2000;
BA_REL_ "GenSigTimeoutTime" BU_SG_REL_ MFK120 SG_ 313 VZM_aktiver_Basisservice 500;
BA_REL_ "GenSigTimeoutTime" BU_SG_REL_ MFK120 SG_ 313 VZM_Fahrer_bremst 500;
BA_REL_ "GenSigTimeoutTime" BU_SG_REL_ MFK120 SG_ 313 VZM_QBit_Fahrer_bremst 500;
BA_REL_ "GenSigTimeoutTime" BU_SG_REL_ MFK120 SG_ 313 VZM_Warnruckeln_nicht_verfuegbar 500;
BA_REL_ "GenSigTimeoutTime" BU_SG_REL_ MFK120 SG_ 313 VZM_Fahrer_bremst_deutlich 500;
BA_REL_ "GenSigTimeoutTime" BU_SG_REL_ MFK120 SG_ 313 VZM_Verz_Reg_aktiv 500;
BA_REL_ "GenSigTimeoutTime" BU_SG_REL_ MFK120 SG_ 313 VMM_Fahrer_Bremskraft_bestimmend 500;
BA_REL_ "GenSigTimeoutTime" BU_SG_REL_ MFK120 SG_ 313 VMM_Inkonsistenz_EA 500;
BA_REL_ "GenSigTimeoutTime" BU_SG_REL_ MFK120 SG_ 313 VZM_Verz_ASIL_Verfuegbarkeit 500;
BA_REL_ "GenSigTimeoutTime" BU_SG_REL_ MFK120 SG_ 313 VZM_aktives_System 500;
BA_REL_ "GenSigTimeoutTime" BU_SG_REL_ MFK120 SG_ 313 HMS_Systemstatus 500;
BA_REL_ "GenSigTimeoutTime" BU_SG_REL_ MFK120 SG_ 313 HMS_Stillstand 500;
BA_REL_ "GenSigTimeoutTime" BU_SG_REL_ MFK120 SG_ 313 HMS_aktives_System 500;
BA_REL_ "GenSigTimeoutTime" BU_SG_REL_ MFK120 SG_ 1702 Wischer1_Wischgeschwindigkeit 5000;
BA_REL_ "GenSigTimeoutTime" BU_SG_REL_ MFK120 SG_ 1411 ZV_Schluessel_Zugang 2000;
BA_REL_ "GenSigTimeoutTime" BU_SG_REL_ MIK SG_ 997 FT_Tuer_Status 1000;
BA_REL_ "GenSigTimeoutTime" BU_SG_REL_ MIK SG_ 1716 VIN_01_MUX 2000;
BA_REL_ "GenSigTimeoutTime" BU_SG_REL_ MIK SG_ 1716 VIN_4 2000;
BA_REL_ "GenSigTimeoutTime" BU_SG_REL_ MIK SG_ 1716 VIN_11 2000;
BA_REL_ "GenSigTimeoutTime" BU_SG_REL_ MIK SG_ 1716 VIN_5 2000;
BA_REL_ "GenSigTimeoutTime" BU_SG_REL_ MIK SG_ 1716 VIN_12 2000;
BA_REL_ "GenSigTimeoutTime" BU_SG_REL_ MIK SG_ 1716 VIN_6 2000;
BA_REL_ "GenSigTimeoutTime" BU_SG_REL_ MIK SG_ 1716 VIN_13 2000;
BA_REL_ "GenSigTimeoutTime" BU_SG_REL_ MIK SG_ 1716 VIN_7 2000;
BA_REL_ "GenSigTimeoutTime" BU_SG_REL_ MIK SG_ 1716 VIN_14 2000;
BA_REL_ "GenSigTimeoutTime" BU_SG_REL_ MIK SG_ 1716 VIN_1 2000;
BA_REL_ "GenSigTimeoutTime" BU_SG_REL_ MIK SG_ 1716 VIN_8 2000;
BA_REL_ "GenSigTimeoutTime" BU_SG_REL_ MIK SG_ 1716 VIN_15 2000;
BA_REL_ "GenSigTimeoutTime" BU_SG_REL_ MIK SG_ 1716 VIN_2 2000;
BA_REL_ "GenSigTimeoutTime" BU_SG_REL_ MIK SG_ 1716 VIN_9 2000;
BA_REL_ "GenSigTimeoutTime" BU_SG_REL_ MIK SG_ 1716 VIN_16 2000;
BA_REL_ "GenSigTimeoutTime" BU_SG_REL_ MIK SG_ 1716 VIN_3 2000;
BA_REL_ "GenSigTimeoutTime" BU_SG_REL_ MIK SG_ 1716 VIN_10 2000;
BA_REL_ "GenSigTimeoutTime" BU_SG_REL_ MIK SG_ 1716 VIN_17 2000;
BA_REL_ "GenSigTimeoutTime" BU_SG_REL_ MRR2023 SG_ 997 TSG_FT_02_CRC 1000;
BA_REL_ "GenSigTimeoutTime" BU_SG_REL_ MRR2023 SG_ 997 TSG_FT_02_BZ 1000;
BA_REL_ "GenSigTimeoutTime" BU_SG_REL_ MRR2023 SG_ 997 FT_Tuer_Status 1000;
BA_REL_ "GenSigTimeoutTime" BU_SG_REL_ MRR2023 SG_ 1019 TSK_Ausrollkurve_Schub_Reku_01 800;
BA_REL_ "GenSigTimeoutTime" BU_SG_REL_ MRR2023 SG_ 1019 TSK_Ausrollkurve_Schub_Reku_05 800;
BA_REL_ "GenSigTimeoutTime" BU_SG_REL_ MRR2023 SG_ 1019 TSK_Ausrollkurve_Schub_Reku_09 800;
BA_REL_ "GenSigTimeoutTime" BU_SG_REL_ MRR2023 SG_ 1019 TSK_Ausrollkurve_Schub_Reku_13 800;
BA_REL_ "GenSigTimeoutTime" BU_SG_REL_ MRR2023 SG_ 1019 TSK_Ausrollkurve_Schub_Reku_17 800;
BA_REL_ "GenSigTimeoutTime" BU_SG_REL_ MRR2023 SG_ 1019 TSK_Ausrollkurve_Schub_Reku_02 800;
BA_REL_ "GenSigTimeoutTime" BU_SG_REL_ MRR2023 SG_ 1019 TSK_Ausrollkurve_Schub_Reku_06 800;
BA_REL_ "GenSigTimeoutTime" BU_SG_REL_ MRR2023 SG_ 1019 TSK_Ausrollkurve_Schub_Reku_10 800;
BA_REL_ "GenSigTimeoutTime" BU_SG_REL_ MRR2023 SG_ 1019 TSK_Ausrollkurve_Schub_Reku_14 800;
BA_REL_ "GenSigTimeoutTime" BU_SG_REL_ MRR2023 SG_ 1019 TSK_Ausrollkurve_Schub_Reku_18 800;
BA_REL_ "GenSigTimeoutTime" BU_SG_REL_ MRR2023 SG_ 1019 TSK_Ausrollkurve_Schub_Reku_03 800;
BA_REL_ "GenSigTimeoutTime" BU_SG_REL_ MRR2023 SG_ 1019 TSK_Ausrollkurve_Schub_Reku_07 800;
BA_REL_ "GenSigTimeoutTime" BU_SG_REL_ MRR2023 SG_ 1019 TSK_Ausrollkurve_Schub_Reku_11 800;
BA_REL_ "GenSigTimeoutTime" BU_SG_REL_ MRR2023 SG_ 1019 TSK_Ausrollkurve_Schub_Reku_15 800;
BA_REL_ "GenSigTimeoutTime" BU_SG_REL_ MRR2023 SG_ 1019 TSK_Ausrollkurve_Schub_Reku_19 800;
BA_REL_ "GenSigTimeoutTime" BU_SG_REL_ MRR2023 SG_ 1019 TSK_Ausrollkurve_Schub_Reku_04 800;
BA_REL_ "GenSigTimeoutTime" BU_SG_REL_ MRR2023 SG_ 1019 TSK_Ausrollkurve_Schub_Reku_08 800;
BA_REL_ "GenSigTimeoutTime" BU_SG_REL_ MRR2023 SG_ 1019 TSK_Ausrollkurve_Schub_Reku_12 800;
BA_REL_ "GenSigTimeoutTime" BU_SG_REL_ MRR2023 SG_ 1019 TSK_Ausrollkurve_Schub_Reku_16 800;
BA_REL_ "GenSigTimeoutTime" BU_SG_REL_ MRR2023 SG_ 1019 TSK_Ausrollkurve_Schub_Reku_20 800;
BA_REL_ "GenSigTimeoutTime" BU_SG_REL_ MRR2023 SG_ 1019 TSK_Ausrollkurve_Segeln_01 800;
BA_REL_ "GenSigTimeoutTime" BU_SG_REL_ MRR2023 SG_ 1019 TSK_Ausrollkurve_Segeln_05 800;
BA_REL_ "GenSigTimeoutTime" BU_SG_REL_ MRR2023 SG_ 1019 TSK_Ausrollkurve_Segeln_09 800;
BA_REL_ "GenSigTimeoutTime" BU_SG_REL_ MRR2023 SG_ 1019 TSK_Ausrollkurve_Segeln_13 800;
BA_REL_ "GenSigTimeoutTime" BU_SG_REL_ MRR2023 SG_ 1019 TSK_Ausrollkurve_Segeln_17 800;
BA_REL_ "GenSigTimeoutTime" BU_SG_REL_ MRR2023 SG_ 1019 TSK_Ausrollkurve_Segeln_02 800;
BA_REL_ "GenSigTimeoutTime" BU_SG_REL_ MRR2023 SG_ 1019 TSK_Ausrollkurve_Segeln_06 800;
BA_REL_ "GenSigTimeoutTime" BU_SG_REL_ MRR2023 SG_ 1019 TSK_Ausrollkurve_Segeln_10 800;
BA_REL_ "GenSigTimeoutTime" BU_SG_REL_ MRR2023 SG_ 1019 TSK_Ausrollkurve_Segeln_14 800;
BA_REL_ "GenSigTimeoutTime" BU_SG_REL_ MRR2023 SG_ 1019 TSK_Ausrollkurve_Segeln_18 800;
BA_REL_ "GenSigTimeoutTime" BU_SG_REL_ MRR2023 SG_ 1019 TSK_Ausrollkurve_Segeln_03 800;
BA_REL_ "GenSigTimeoutTime" BU_SG_REL_ MRR2023 SG_ 1019 TSK_Ausrollkurve_Segeln_07 800;
BA_REL_ "GenSigTimeoutTime" BU_SG_REL_ MRR2023 SG_ 1019 TSK_Ausrollkurve_Segeln_11 800;
BA_REL_ "GenSigTimeoutTime" BU_SG_REL_ MRR2023 SG_ 1019 TSK_Ausrollkurve_Segeln_15 800;
BA_REL_ "GenSigTimeoutTime" BU_SG_REL_ MRR2023 SG_ 1019 TSK_Ausrollkurve_Segeln_19 800;
BA_REL_ "GenSigTimeoutTime" BU_SG_REL_ MRR2023 SG_ 1019 TSK_Ausrollkurve_Segeln_04 800;
BA_REL_ "GenSigTimeoutTime" BU_SG_REL_ MRR2023 SG_ 1019 TSK_Ausrollkurve_Segeln_08 800;
BA_REL_ "GenSigTimeoutTime" BU_SG_REL_ MRR2023 SG_ 1019 TSK_Ausrollkurve_Segeln_12 800;
BA_REL_ "GenSigTimeoutTime" BU_SG_REL_ MRR2023 SG_ 1019 TSK_Ausrollkurve_Segeln_16 800;
BA_REL_ "GenSigTimeoutTime" BU_SG_REL_ MRR2023 SG_ 1019 TSK_Ausrollkurve_Segeln_20 800;
BA_REL_ "GenSigTimeoutTime" BU_SG_REL_ MRR2023 SG_ 1019 TSK_Ausrollkurve_Mux 800;
BA_REL_ "GenSigTimeoutTime" BU_SG_REL_ MRR2023 SG_ 1019 TSK_Ausrollkurve_Reku 800;
BA_REL_ "GenSigTimeoutTime" BU_SG_REL_ MRR2023 SG_ 1019 TSK_Ausrollkurve_Schrittweite 800;
BA_REL_ "GenSigTimeoutTime" BU_SG_REL_ MRR2023 SG_ 1019 TSK_Ausrollkurve_Zaehler 800;
BA_REL_ "GenSigTimeoutTime" BU_SG_REL_ MRR2023 SG_ 1716 VIN_01_MUX 2000;
BA_REL_ "GenSigTimeoutTime" BU_SG_REL_ MRR2023 SG_ 1716 VIN_4 2000;
BA_REL_ "GenSigTimeoutTime" BU_SG_REL_ MRR2023 SG_ 1716 VIN_11 2000;
BA_REL_ "GenSigTimeoutTime" BU_SG_REL_ MRR2023 SG_ 1716 VIN_5 2000;
BA_REL_ "GenSigTimeoutTime" BU_SG_REL_ MRR2023 SG_ 1716 VIN_12 2000;
BA_REL_ "GenSigTimeoutTime" BU_SG_REL_ MRR2023 SG_ 1716 VIN_6 2000;
BA_REL_ "GenSigTimeoutTime" BU_SG_REL_ MRR2023 SG_ 1716 VIN_13 2000;
BA_REL_ "GenSigTimeoutTime" BU_SG_REL_ MRR2023 SG_ 1716 VIN_7 2000;
BA_REL_ "GenSigTimeoutTime" BU_SG_REL_ MRR2023 SG_ 1716 VIN_14 2000;
BA_REL_ "GenSigTimeoutTime" BU_SG_REL_ MRR2023 SG_ 1716 VIN_1 2000;
BA_REL_ "GenSigTimeoutTime" BU_SG_REL_ MRR2023 SG_ 1716 VIN_8 2000;
BA_REL_ "GenSigTimeoutTime" BU_SG_REL_ MRR2023 SG_ 1716 VIN_15 2000;
BA_REL_ "GenSigTimeoutTime" BU_SG_REL_ MRR2023 SG_ 1716 VIN_2 2000;
BA_REL_ "GenSigTimeoutTime" BU_SG_REL_ MRR2023 SG_ 1716 VIN_9 2000;
BA_REL_ "GenSigTimeoutTime" BU_SG_REL_ MRR2023 SG_ 1716 VIN_16 2000;
BA_REL_ "GenSigTimeoutTime" BU_SG_REL_ MRR2023 SG_ 1716 VIN_3 2000;
BA_REL_ "GenSigTimeoutTime" BU_SG_REL_ MRR2023 SG_ 1716 VIN_10 2000;
BA_REL_ "GenSigTimeoutTime" BU_SG_REL_ MRR2023 SG_ 1716 VIN_17 2000;
BA_REL_ "GenSigTimeoutTime" BU_SG_REL_ MRR2023 SG_ 313 VMM_02_CRC 500;
BA_REL_ "GenSigTimeoutTime" BU_SG_REL_ MRR2023 SG_ 313 VMM_02_BZ 500;
BA_REL_ "GenSigTimeoutTime" BU_SG_REL_ MRR2023 SG_ 313 VZM_aktiver_Basisservice 500;
BA_REL_ "GenSigTimeoutTime" BU_SG_REL_ MRR2023 SG_ 313 VZM_Anhalteweg_nicht_verfuegbar 500;
BA_REL_ "GenSigTimeoutTime" BU_SG_REL_ MRR2023 SG_ 313 VZM_Fahrer_bremst 500;
BA_REL_ "GenSigTimeoutTime" BU_SG_REL_ MRR2023 SG_ 313 VZM_QBit_Fahrer_bremst 500;
BA_REL_ "GenSigTimeoutTime" BU_SG_REL_ MRR2023 SG_ 313 VZM_Warnruck_nicht_verfuegbar 500;
BA_REL_ "GenSigTimeoutTime" BU_SG_REL_ MRR2023 SG_ 313 VZM_Bkd_nicht_verfuegbar 500;
BA_REL_ "GenSigTimeoutTime" BU_SG_REL_ MRR2023 SG_ 313 VMM_Bremslicht_defekt 500;
BA_REL_ "GenSigTimeoutTime" BU_SG_REL_ MRR2023 SG_ 313 VZM_Fahrer_bremst_deutlich 500;
BA_REL_ "GenSigTimeoutTime" BU_SG_REL_ MRR2023 SG_ 313 VZM_Verz_Reg_nicht_verfuegbar 500;
BA_REL_ "GenSigTimeoutTime" BU_SG_REL_ MRR2023 SG_ 313 VMM_Bremslicht_unplausibel 500;
BA_REL_ "GenSigTimeoutTime" BU_SG_REL_ MRR2023 SG_ 313 VMM_Inkonsistenz_ACC 500;
BA_REL_ "GenSigTimeoutTime" BU_SG_REL_ MRR2023 SG_ 313 VMM_Inkonsistenz_AWV_PCF 500;
BA_REL_ "GenSigTimeoutTime" BU_SG_REL_ MRR2023 SG_ 313 VMM_Fahrer_Bremskraft_bestimmend 500;
BA_REL_ "GenSigTimeoutTime" BU_SG_REL_ MRR2023 SG_ 313 VZM_Verz_ASIL_Verfuegbarkeit 500;
BA_REL_ "GenSigTimeoutTime" BU_SG_REL_ MRR2023 SG_ 313 VZM_aktives_System 500;
BA_REL_ "GenSigTimeoutTime" BU_SG_REL_ MRR2023 SG_ 313 VZM_Verz_Begrenzung 500;
BA_REL_ "GenSigTimeoutTime" BU_SG_REL_ MRR2023 SG_ 313 VZM_Systemstatus 500;
BA_REL_ "GenSigTimeoutTime" BU_SG_REL_ MRR2023 SG_ 313 HMS_halten_nicht_verfuegbar 500;
BA_REL_ "GenSigTimeoutTime" BU_SG_REL_ MRR2023 SG_ 313 HMS_parken_nicht_verfuegbar 500;
BA_REL_ "GenSigTimeoutTime" BU_SG_REL_ MRR2023 SG_ 313 HMS_Systemstatus 500;
BA_REL_ "GenSigTimeoutTime" BU_SG_REL_ MRR2023 SG_ 313 HMS_Stillstand 500;
BA_REL_ "GenSigTimeoutTime" BU_SG_REL_ MRR2023 SG_ 313 HMS_aktives_System 500;
BA_REL_ "GenSigTimeoutTime" BU_SG_REL_ MRR2023 SG_ 313 HMS_Fehlerstatus 500;
BA_REL_ "GenSigTimeoutTime" BU_SG_REL_ MRR2023 SG_ 2463978663 VZE_Anzeigemodus 2000;
BA_REL_ "GenSigTimeoutTime" BU_SG_REL_ MRR2023 SG_ 2463978663 VZE_Hinweistext 2000;
BA_REL_ "GenSigTimeoutTime" BU_SG_REL_ MRR2023 SG_ 2463978663 VZE_Verkehrszeichen_1 2000;
BA_REL_ "GenSigTimeoutTime" BU_SG_REL_ MRR2023 SG_ 2463978663 VZE_Verkehrszeichen_2 2000;
BA_REL_ "GenSigTimeoutTime" BU_SG_REL_ MRR2023 SG_ 2463978663 VZE_Verkehrszeichen_3 2000;
BA_REL_ "GenSigTimeoutTime" BU_SG_REL_ MRR2023 SG_ 2463978663 VZE_Warnung_Verkehrszeichen_1 2000;
BA_REL_ "GenSigTimeoutTime" BU_SG_REL_ MRR2023 SG_ 2463978663 VZE_Warnung_Verkehrszeichen_2 2000;
BA_REL_ "GenSigTimeoutTime" BU_SG_REL_ MRR2023 SG_ 2463978663 VZE_Warnung_Verkehrszeichen_3 2000;
BA_REL_ "GenSigTimeoutTime" BU_SG_REL_ MRR2023 SG_ 2463978663 VZE_Zusatzschild_1 2000;
BA_REL_ "GenSigTimeoutTime" BU_SG_REL_ MRR2023 SG_ 2463978663 VZE_Zusatzschild_2 2000;
BA_REL_ "GenSigTimeoutTime" BU_SG_REL_ MRR2023 SG_ 2463978663 VZE_Zusatzschild_3 2000;
BA_REL_ "GenSigTimeoutTime" BU_SG_REL_ MRR2023 SG_ 2463978663 VZE_Anzeigeunterdrueck_Zeichen_1 2000;
BA_REL_ "GenSigTimeoutTime" BU_SG_REL_ MRR2023 SG_ 2463978663 VZE_Zeichen_01_KameraWied 2000;
BA_REL_ "GenSigTimeoutTime" BU_SG_REL_ MRR2023 SG_ 2463978663 VZE_Zeichen_02_KameraWied 2000;
BA_REL_ "GenSigTimeoutTime" BU_SG_REL_ MRR2023 SG_ 2463978663 VZE_Zeichen_03_KameraWied 2000;
BA_REL_ "GenSigTimeoutTime" BU_SG_REL_ MRR2023 SG_ 2463978663 VZE_Zeichen_01_Kamera 2000;
BA_REL_ "GenSigTimeoutTime" BU_SG_REL_ MRR2023 SG_ 2463978663 VZE_Zeichen_01_Karte 2000;
BA_REL_ "GenSigTimeoutTime" BU_SG_REL_ MRR2023 SG_ 2463978663 VZE_Zeichen_01_Gesetz 2000;
BA_REL_ "GenSigTimeoutTime" BU_SG_REL_ MRR2023 SG_ 2463978663 VZE_Zeichen_02_Kamera 2000;
BA_REL_ "GenSigTimeoutTime" BU_SG_REL_ MRR2023 SG_ 2463978663 VZE_Zeichen_02_Karte 2000;
BA_REL_ "GenSigTimeoutTime" BU_SG_REL_ MRR2023 SG_ 2463978663 VZE_Zeichen_02_Gesetz 2000;
BA_REL_ "GenSigTimeoutTime" BU_SG_REL_ MRR2023 SG_ 2463978663 VZE_Zeichen_03_Kamera 2000;
BA_REL_ "GenSigTimeoutTime" BU_SG_REL_ MRR2023 SG_ 2463978663 VZE_Zeichen_03_Karte 2000;
BA_REL_ "GenSigTimeoutTime" BU_SG_REL_ MRR2023 SG_ 2463978663 VZE_Zeichen_03_Gesetz 2000;
BA_REL_ "GenSigTimeoutTime" BU_SG_REL_ MRR2023 SG_ 2463978663 VZE_Gong 2000;
BA_REL_ "GenSigTimeoutTime" BU_SG_REL_ MRR2023 SG_ 2463978663 VZE_Zeichen_05_KameraWied 2000;
BA_REL_ "GenSigTimeoutTime" BU_SG_REL_ MRR2023 SG_ 2463978663 VZE_Zeichen_05_Kamera 2000;
BA_REL_ "GenSigTimeoutTime" BU_SG_REL_ MRR2023 SG_ 2463978663 VZE_Verkehrszeichen_4 2000;
BA_REL_ "GenSigTimeoutTime" BU_SG_REL_ MRR2023 SG_ 2463978663 VZE_Verkehrszeichen_5 2000;
BA_REL_ "GenSigTimeoutTime" BU_SG_REL_ MRR2023 SG_ 2463978663 VZE_Anhaenger_Vmax 2000;
BA_REL_ "GenSigTimeoutTime" BU_SG_REL_ MRR2023 SG_ 2463978663 VZE_Warnung_Verkehrszeichen_4 2000;
BA_REL_ "GenSigTimeoutTime" BU_SG_REL_ MRR2023 SG_ 2463978663 VZE_Warnung_Verkehrszeichen_5 2000;
BA_REL_ "GenSigTimeoutTime" BU_SG_REL_ MRR2023 SG_ 2463978663 VZE_Zusatzschild_4 2000;
BA_REL_ "GenSigTimeoutTime" BU_SG_REL_ MRR2023 SG_ 2463978663 VZE_Zusatzschild_5 2000;
BA_REL_ "GenSigTimeoutTime" BU_SG_REL_ MRR2023 SG_ 2463978663 VZE_Baustelle 2000;
BA_REL_ "GenSigTimeoutTime" BU_SG_REL_ MRR2023 SG_ 2463978663 VZE_Zeichen_05_Entfernung 2000;
BA_REL_ "GenSigTimeoutTime" BU_SG_REL_ MRR2023 SG_ 2463978663 VZE_Zeichen_05_Entfernung_StdA 2000;
BA_REL_ "GenSigTimeoutTime" BU_SG_REL_ MRR2023 SG_ 2463978663 VZE_Verkehrszeichen_6 2000;
BA_REL_ "GenSigTimeoutTime" BU_SG_REL_ MRR2023 SG_ 2463978663 VZE_Zusatzschild_6 2000;
BA_REL_ "GenSigTimeoutTime" BU_SG_REL_ MRR2023 SG_ 2463978663 VZE_Zeichen_06_Entfernung 2000;
BA_REL_ "GenSigTimeoutTime" BU_SG_REL_ MRR2023 SG_ 2463978663 VZE_Zeichen_06_Entfernung_StdA 2000;
BA_REL_ "GenSigTimeoutTime" BU_SG_REL_ MRR2023 SG_ 2463978663 VZE_Umweltinfo_Naesse 2000;
BA_REL_ "GenSigTimeoutTime" BU_SG_REL_ MRR2023 SG_ 2463978663 VZE_Umweltinfo_Nebel 2000;
BA_REL_ "GenSigTimeoutTime" BU_SG_REL_ MRR2023 SG_ 2463978663 VZE_Umweltinfo_Anhaengerbetrieb 2000;
BA_REL_ "GenSigTimeoutTime" BU_SG_REL_ MRR2023 SG_ 2463978663 VZE_Erweiterte_Information 2000;
BA_REL_ "GenSigTimeoutTime" BU_SG_REL_ MRR2023 SG_ 2463978663 VZE_Tempowarnung_Status 2000;
BA_REL_ "GenSigTimeoutTime" BU_SG_REL_ MRR2023 SG_ 2463978663 VZE_Tempowarnung_Einheit 2000;
BA_REL_ "GenSigTimeoutTime" BU_SG_REL_ MRR2023 SG_ 2463978663 VZE_Tempowarnung_Offset 2000;
BA_REL_ "GenSigTimeoutTime" BU_SG_REL_ MRR2023 SG_ 2463978663 VZE_FoD_Status 2000;
BA_REL_ "GenSigTimeoutTime" BU_SG_REL_ MRR2023 SG_ 2463978954 VZE_relevant_Stopp 1000;
BA_REL_ "GenSigTimeoutTime" BU_SG_REL_ MRR2023 SG_ 2463978954 VZE_Ampel_Datenbasis_REM 1000;
BA_REL_ "GenSigTimeoutTime" BU_SG_REL_ MRR2023 SG_ 2463978954 VZE_Ampel_Datenbasis_Vision 1000;
BA_REL_ "GenSigTimeoutTime" BU_SG_REL_ MRR2023 SG_ 2463978954 VZE_relevant_Stopp_Abstand 1000;
BA_REL_ "GenSigTimeoutTime" BU_SG_REL_ MRR2023 SG_ 2463978954 VZE_relevante_Ampel_Abstand 1000;
BA_REL_ "GenSigTimeoutTime" BU_SG_REL_ MRR2023 SG_ 2463978954 VZE_relevante_Ampel 1000;
BA_REL_ "GenSigTimeoutTime" BU_SG_REL_ MRR2023 SG_ 1411 ZV_BT_offen 2000;
BA_REL_ "GenSigTimeoutTime" BU_SG_REL_ MRR2023 SG_ 1411 ZV_HFS_offen 2000;
BA_REL_ "GenSigTimeoutTime" BU_SG_REL_ MRR2023 SG_ 1411 ZV_HBFS_offen 2000;
VAL_ 997 FT_Tuer_Status 0 "Init" 1 "Tuer_geschlossen" 2 "Tuer_offen" 3 "Fehler" ;
VAL_ 997 FT_Tuer_Status_QBit 0 "Status_Tuerkontakt_sicher" 1 "Status_Tuerkontakt_unsicher" ;
VAL_ 997 FT_Lock_Taster_02 0 "nicht_betaetigt" 1 "betaetigt" ;
VAL_ 997 FT_Schluesselschalter_zu_02 0 "nicht_betaetigt" 1 "betaetigt" ;
VAL_ 997 FT_BFS_Tuer_Status 0 "Init" 1 "Tuer_geschlossen" 2 "Tuer_offen" 3 "Fehler" ;
VAL_ 997 FT_HBFS_Tuer_Status 0 "Init" 1 "Tuer_geschlossen" 2 "Tuer_offen" 3 "Fehler" ;
VAL_ 997 FT_HFS_Tuer_Status 0 "Init" 1 "Tuer_geschlossen" 2 "Tuer_offen" 3 "Fehler" ;
VAL_ 997 FT_Tueroeffnen_Warnung 0 "Tuerwarnung_nicht_aktiv" 1 "Tuerwarnung_aktiv" ;
VAL_ 997 FT_SP_Heizung_ein 0 "Aus" 1 "Ein" ;
VAL_ 997 FT_Kisi_Taster_li_02 0 "nicht_betaetigt" 1 "betaetigt" ;
VAL_ 997 FT_Kisi_Taster_re_02 0 "nicht_betaetigt" 1 "betaetigt" ;
VAL_ 997 FT_TD_Taste_Status 0 "kein_Fehler" 1 "Kurzschluss_nach_Minus" 2 "Kurzschluss_nach_Plus" 3 "Leitungsunterbrechung" ;
VAL_ 997 FT_TCR_Mode_aktiv 0 "TCR_Mode_deaktiv" 1 "TCR_Mode_aktiv" ;
VAL_ 997 TBF_FS_Touch_Event 0 "nicht_betaetigt" 1 "Tippen" 2 "Wischen" 3 "Geste" 4 "Doppeltippen" 5 "Longpress_1" 6 "Longpress_2" 7 "reserviert" 8 "reserviert" 9 "reserviert" 10 "reserviert" 11 "reserviert" 12 "reserviert" 13 "reserviert" 14 "reserviert" 15 "reserviert" ;
VAL_ 997 FT_KiSi_Status_Soll_HBFS 0 "inaktiv" 1 "aktiv" ;
VAL_ 997 FT_KiSi_Status_Soll_HFS 0 "inaktiv" 1 "aktiv" ;
VAL_ 997 FS_Push_Tuergriff 0 "nicht_erkannt" 1 "erkannt" ;
VAL_ 997 TSG_FS_Spiegel_angeklappt 0 "Spiegel_ausgeklappt" 1 "Spiegel_eingeklappt" ;
VAL_ 997 FT_Cargolock_bet 0 "nicht_betaetigt" 1 "betaetigt" ;
VAL_ 997 FT_kisi_asynchron 0 "nicht_aktiv" 1 "aktiv" ;
VAL_ 997 FS_Status_eTAG_ext 0 "Griff_eingefahren" 1 "Griff_ausgefahren" 2 "Griff_verfaehrt" 3 "init" 4 "Fehler" ;
VAL_ 997 FT_ASW_Warnton 0 "kein_warnton" 1 "warnton_links" 2 "warnton_rechts" 3 "Fehler" ;
VAL_ 997 SSA_FT_ASW_Status 0 "Init" 1 "InfoStufe_aktiv" 2 "Warnstufe_aktiv" ;
VAL_ 1019 TSK_Ausrollkurve_Schub_Reku_01 127 "Init" ;
VAL_ 1019 TSK_Ausrollkurve_Schub_Reku_05 127 "Init" ;
VAL_ 1019 TSK_Ausrollkurve_Schub_Reku_09 127 "Init" ;
VAL_ 1019 TSK_Ausrollkurve_Schub_Reku_13 127 "Init" ;
VAL_ 1019 TSK_Ausrollkurve_Schub_Reku_17 127 "Init" ;
VAL_ 1019 TSK_Ausrollkurve_Schub_Reku_02 127 "Init" ;
VAL_ 1019 TSK_Ausrollkurve_Schub_Reku_06 127 "Init" ;
VAL_ 1019 TSK_Ausrollkurve_Schub_Reku_10 127 "Init" ;
VAL_ 1019 TSK_Ausrollkurve_Schub_Reku_14 127 "Init" ;
VAL_ 1019 TSK_Ausrollkurve_Schub_Reku_18 127 "Init" ;
VAL_ 1019 TSK_Ausrollkurve_Schub_Reku_03 127 "Init" ;
VAL_ 1019 TSK_Ausrollkurve_Schub_Reku_07 127 "Init" ;
VAL_ 1019 TSK_Ausrollkurve_Schub_Reku_11 127 "Init" ;
VAL_ 1019 TSK_Ausrollkurve_Schub_Reku_15 127 "Init" ;
VAL_ 1019 TSK_Ausrollkurve_Schub_Reku_19 127 "Init" ;
VAL_ 1019 TSK_Ausrollkurve_Schub_Reku_04 127 "Init" ;
VAL_ 1019 TSK_Ausrollkurve_Schub_Reku_08 127 "Init" ;
VAL_ 1019 TSK_Ausrollkurve_Schub_Reku_12 127 "Init" ;
VAL_ 1019 TSK_Ausrollkurve_Schub_Reku_16 127 "Init" ;
VAL_ 1019 TSK_Ausrollkurve_Schub_Reku_20 127 "Init" ;
VAL_ 1019 TSK_Ausrollkurve_Segeln_01 127 "Init" ;
VAL_ 1019 TSK_Ausrollkurve_Segeln_05 127 "Init" ;
VAL_ 1019 TSK_Ausrollkurve_Segeln_09 127 "Init" ;
VAL_ 1019 TSK_Ausrollkurve_Segeln_13 127 "Init" ;
VAL_ 1019 TSK_Ausrollkurve_Segeln_17 127 "Init" ;
VAL_ 1019 TSK_Ausrollkurve_Segeln_02 127 "Init" ;
VAL_ 1019 TSK_Ausrollkurve_Segeln_06 127 "Init" ;
VAL_ 1019 TSK_Ausrollkurve_Segeln_10 127 "Init" ;
VAL_ 1019 TSK_Ausrollkurve_Segeln_14 127 "Init" ;
VAL_ 1019 TSK_Ausrollkurve_Segeln_18 127 "Init" ;
VAL_ 1019 TSK_Ausrollkurve_Segeln_03 127 "Init" ;
VAL_ 1019 TSK_Ausrollkurve_Segeln_07 127 "Init" ;
VAL_ 1019 TSK_Ausrollkurve_Segeln_11 127 "Init" ;
VAL_ 1019 TSK_Ausrollkurve_Segeln_15 127 "Init" ;
VAL_ 1019 TSK_Ausrollkurve_Segeln_19 127 "Init" ;
VAL_ 1019 TSK_Ausrollkurve_Segeln_04 127 "Init" ;
VAL_ 1019 TSK_Ausrollkurve_Segeln_08 127 "Init" ;
VAL_ 1019 TSK_Ausrollkurve_Segeln_12 127 "Init" ;
VAL_ 1019 TSK_Ausrollkurve_Segeln_16 127 "Init" ;
VAL_ 1019 TSK_Ausrollkurve_Segeln_20 127 "Init" ;
VAL_ 1019 TSK_Ausrollkurve_Reku 0 "Rekuperation_nicht_beruecksichtigt" 1 "Rekuperation_beruecksichtigt" ;
VAL_ 1019 TSK_Ausrollkurve_Schrittweite 0 "Normale_Schrittweite" 1 "Grosse_Schrittweite" ;
VAL_ 2463978710 OPS_ComfortReadyStatus 0 "Init" 1 "aktiv" 2 "inaktiv" 3 "Fehler" ;
VAL_ 2463978710 OPS_OccupantPresenceStatus 0 "Init" 1 "OccupantAbsent" 2 "reserviert" 3 "OccupantEntryExit" 4 "reserviert" 5 "OccupantPresent" 6 "OccupantPresentVerified" 7 "Fehler" ;
VAL_ 2463978710 OPS_DriverPresenceStatus 0 "Init" 1 "reserviert" 2 "DriverAbsent" 3 "reserviert" 4 "DriverEntry" 5 "reserviert" 6 "DriverPresent" 7 "reserviert" 8 "DriverPresentVerified" 9 "reserviert" 10 "reserviert" 11 "DriverExitIntent" 12 "reserviert" 13 "DriverExit" 14 "reserviert" 15 "Fehler" ;
VAL_ 2463978710 OPS_QBit_DriverPresence 0 "gueltiger_Wert" 1 "Ersatz_Init_oder_Fehlerwert" ;
VAL_ 2463978710 OPS_SafeDriverPresenceStatus 0 "Init" 1 "Driver_Safe_Present" 2 "Driver_Not_Safe_Present" 3 "Fehler" ;
VAL_ 2463978710 OPS_SafeDriverPresence_available 0 "Verfuegbar" 1 "Verfuegbar_eingeschr_Performance" ;
VAL_ 313 VZM_aktiver_Basisservice 0 "Keine_Aktivitaet" 1 "Bremsenkonditionierung" 2 "Bremsruck" 3 "Verzoegerungsregelung" 4 "Wegregelung" ;
VAL_ 313 VZM_Anhalteweg_nicht_verfuegbar 0 "verfuegbar" 1 "nicht_verfuegbar" ;
VAL_ 313 VZM_Fahrer_bremst 0 "Bremsdruckschwelle_nicht_ueberschritten" 1 "Bremsdruckschwelle_ueberschritten" ;
VAL_ 313 VZM_QBit_Fahrer_bremst 0 "gueltiger_Wert" 1 "Ersatz_Init_oder_Fehlerwert" ;
VAL_ 313 VMM_MKB_codiert 0 "MKB_nicht_codiert" 1 "MKB_codiert" ;
VAL_ 313 VMM_Inkonsistenz_EBKV 0 "konsistent" 1 "nicht_konsistent" ;
VAL_ 313 VMM_Notstopp_Status 0 "Init" 1 "verfuegbar" 2 "warten_auf_sekundaer_System" 3 "passiv_Ueberwachung" 4 "aktiv_ausgeloest" 7 "Fehler" ;
VAL_ 313 VZM_Warnruck_nicht_verfuegbar 0 "verfuegbar" 1 "nicht_verfuegbar" ;
VAL_ 313 VZM_Warnruckeln_nicht_verfuegbar 0 "verfuegbar" 1 "nicht_verfuegbar" ;
VAL_ 313 VZM_Bkd_nicht_verfuegbar 0 "verfuegbar" 1 "nicht_verfuegbar" ;
VAL_ 313 VMM_Bremslicht_defekt 0 "Bremslichter_nicht_defekt" 1 "Bremslichter_defekt" ;
VAL_ 313 VZM_Fahrer_bremst_deutlich 0 "Fahrer_bremst_nicht_deutlich" 1 "Fahrer_bremst_deutlich" ;
VAL_ 313 VZM_TSK_SRBM_Anf 0 "keine_Aktivitaet" 1 "Aktivitaet_durch_TSK" ;
VAL_ 313 VZM_TSK_SRBM_nicht_verfuegbar 0 "verfuegbar" 1 "nicht_verfuegbar" ;
VAL_ 313 VZM_Verz_Reg_aktiv 0 "keine_Aktivitaet" 2 "Aktivitaet_durch_AWV_PCF" 3 "Aktivitaet_durch_EA" 4 "Aktivitaet_durch_TSK" 5 "Aktivitaet_durch_RCTA" 6 "Aktivitaet_durch_ParkAssist" 7 "Aktivitaet_durch_ACC" 8 "Aktivitaet_durch_ARA" 9 "Aktivitaet_durch_NV" 10 "Aktivitaet_durch_KAS" 11 "Aktivitaet_durch_FAS_VK" 12 "Aktivitaet_durch_vESC" 13 "Aktivitaet_durch_KAM" 14 "Aktivitaet_durch_BRS_intern" 15 "Aktivitaet_durch_AEB" 16 "Aktivitaet_durch_MKB" ;
VAL_ 313 VZM_Verz_Reg_nicht_verfuegbar 0 "verfuegbar" 1 "nicht_verfuegbar" ;
VAL_ 313 VMM_Inkonsistenz_KAS 0 "konsistent" 1 "nicht_konsistent" ;
VAL_ 313 VMM_Bremslicht_unplausibel 0 "plausibel" 1 "unplausibel" ;
VAL_ 313 VMM_Inkonsistenz_ACC 0 "konsistent" 1 "nicht_konsistent" ;
VAL_ 313 VMM_Inkonsistenz_AWV_PCF 0 "konsistent" 1 "nicht_konsistent" ;
VAL_ 313 VMM_Inkonsistenz_ARA 0 "konsistent" 1 "nicht_konsistent" ;
VAL_ 313 VMM_Inkonsistenz_ParkAssist 0 "konsistent" 1 "nicht_konsistent" ;
VAL_ 313 VMM_Inkonsistenz_FAS_VK 0 "konsistent" 1 "nicht_konsistent" ;
VAL_ 313 VMM_Inkonsistenz_NV 0 "konsistent" 1 "nicht_konsistent" ;
VAL_ 313 VMM_Inkonsistenz_RCTA 0 "konsistent" 1 "nicht_konsistent" ;
VAL_ 313 VMM_Inkonsistenz_TSK 0 "konsistent" 1 "nicht_konsistent" ;
VAL_ 313 VMM_Inkonsistenz_MO 0 "konsistent" 1 "nicht_konsistent" ;
VAL_ 313 VMM_Inkonsistenz_AEB 0 "konsistent" 1 "nicht_konsistent" ;
VAL_ 313 VMM_Fahrer_Bremskraft_bestimmend 0 "Nicht_Bremskraft_bestimmend" 1 "Bremskraft_bestimmend" ;
VAL_ 313 VMM_Inkonsistenz_EA 0 "konsistent" 1 "nicht_konsistent" ;
VAL_ 313 VZM_Status_Wegregelung 0 "Inaktiv" 1 "Passiv" 2 "Aktiv" 3 "Passiv_Ueberwachend" ;
VAL_ 313 VZM_Verz_ASIL_Verfuegbarkeit 0 "Nicht_verfuegbar" 1 "Verfuegbar_ab_ASIL_QM" 2 "Verfuegbar_ab_ASIL_A" 3 "Verfuegbar_ab_ASIL_B" 4 "Verfuegbar_ab_ASIL_C" ;
VAL_ 313 VZM_aktives_System 0 "Kein_aktiver_Teilnehmer" 1 "VZM_intern" 2 "AWV_PCF" 3 "EA" 4 "TSK" 5 "RCTA" 6 "ParkAssist" 7 "ACC" 8 "ARA" 9 "NV" 10 "KAS" 11 "FAS_VK" 12 "vESC" 13 "KAM" 14 "reserviert" 15 "AEB" 16 "MKB" 17 "ECD" 18 "RHP" ;
VAL_ 313 VZM_Verz_Begrenzung 0 "keine_Begrenzung" 1 "Begrenzung_aktiv" ;
VAL_ 313 VZM_Systemstatus 0 "Initialisierung" 1 "Verfuegbar" 2 "Verfuegbar_eingeschr_Performance" 3 "Nicht_Verfuegbar" 4 "Fehler" 5 "Sonderbetriebsmodus" ;
VAL_ 313 VZM_SRBM_Soll 4094 "Init" 4095 "Fehler" ;
VAL_ 313 VZM_SRBM_Ist 4094 "Init" 4095 "Fehler" ;
VAL_ 313 VZM_SRBM_max_Gradient 126 "Init" 127 "Fehler" ;
VAL_ 313 VMM_Inkonsistenz_KAM 0 "konsistent" 1 "nicht_konsistent" ;
VAL_ 313 VMM_Inkonsistenz_RHP 0 "konsistent" 1 "nicht_konsistent" ;
VAL_ 313 VMM_Inkonsistenz_VMC 0 "konsistent" 1 "nicht_konsistent" ;
VAL_ 313 HMS_P_beibehalten_GE 0 "P_nicht_beibehalten" 1 "P_beibehalten" 2 "Init" 3 "Fehler" ;
VAL_ 313 VZM_Unterdrueckung_Antriebsmom 0 "Pos_Antriebsmoment_moeglich" 1 "Pos_Antriebsmoment_unterdruecken" ;
VAL_ 313 VMM_Inkonsistenz_VLK 0 "konsistent" 1 "nicht_konsistent" ;
VAL_ 313 HMS_halten_nicht_verfuegbar_02 0 "verfuegbar" 1 "nicht_verfuegbar" 2 "verfuegbar_ohne_Anwesenheitserk" 3 "reserviert" ;
VAL_ 313 HMS_halten_nicht_verfuegbar 0 "verfuegbar" 1 "nicht_verfuegbar" ;
VAL_ 313 HMS_parken_nicht_verfuegbar 0 "verfuegbar" 1 "nicht_verfuegbar" ;
VAL_ 313 HMS_Anforderung_GE 0 "keine_Anforderung" 1 "P_einlegen" ;
VAL_ 313 HMS_Systemstatus 0 "keine_Funktion_aktiv" 1 "Halten_aktiv" 2 "Parken_angefordert" 3 "Parken_aktiv" 4 "Parken_beibehalten_aktiv" 5 "Anfahren_aktiv" 6 "Loeseanforderung_aktiv" 7 "Loeseanforderung_durch_Fahrer" 8 "Abrutschen_erkannt" 9 "Halten_Standby_aktiv" 10 "Anfahren_Standby_aktiv" 14 "Init" 15 "Fehler" ;
VAL_ 313 HMS_Stillstand 0 "kein_Stillstand" 1 "Stillstand_frueh" 2 "Stillstand" 6 "Init" 7 "Fehler" ;
VAL_ 313 HMS_aktives_System 0 "kein_System__Init_Fehler" 1 "Fahreranforderung_aktiv" 2 "HMS_intern_aktiv" 3 "ACC_aktiv" 4 "Autohold_aktiv" 5 "HHC_aktiv" 6 "HVLM_aktiv" 7 "Getriebe_aktiv" 8 "EBKV_aktiv" 9 "ParkAssist_aktiv" 10 "ARA_aktiv" 11 "HTO_aktiv" 12 "autonomous_Hold_aktiv" 13 "STA_aktiv" 14 "Motor_aktiv" 15 "EA_aktiv" 16 "VLK_aktiv" 17 "RHP_aktiv" 18 "ORU_aktiv" ;
VAL_ 313 VMM_Inkonsistenz_GE 0 "konsistent" 1 "nicht_konsistent" ;
VAL_ 313 VMM_Inkonsistenz_HVLM 0 "konsistent" 1 "nicht_konsistent" ;
VAL_ 313 HMS_Fehlerstatus 0 "kein_Fehler" 1 "Halten_nicht_moeglich" 2 "Sonderbetriebsmodus_aktiv" 3 "Systemeinschraenkung" 4 "Systemstoerung" ;
VAL_ 313 HMS_Index_Haltemoment 0 "Bremsmoment" 1 "Antriebsmoment" ;
VAL_ 313 HMS_Haltemoment 1022 "Init" 1023 "Fehler" ;
VAL_ 2463978663 VZE_Anzeigemodus 0 "EU_RDW" 1 "USA" 2 "Canada" 3 "China" ;
VAL_ 2463978663 VZE_Hinweistext 0 "kein_Hinweistext" ;
VAL_ 2463978663 VZE_Akustik_Limitwechsel 0 "keine_akustische_Signalisierung" 1 "akustische_Signalisierung_an" ;
VAL_ 2463978663 VZE_Modus_OptischeWarnung 0 "konstant" 1 "blinkend" ;
VAL_ 2463978663 VZE_Verkehrszeichen_Einheit 0 "kmh" 1 "mph" ;
VAL_ 2463978663 VZE_Anzeigeunterdrueck_Zeichen_3 0 "anzeigerelevant" 1 "nicht_anzeigerelevant" ;
VAL_ 2463978663 VZE_Anzeigeunterdrueck_Zeichen_2 0 "anzeigerelevant" 1 "nicht_anzeigerelevant" ;
VAL_ 2463978663 VZE_Verkehrszeichen_1 0 "kein_Verkehrszeichen" ;
VAL_ 2463978663 VZE_Verkehrszeichen_2 0 "kein_Verkehrszeichen" ;
VAL_ 2463978663 VZE_Verkehrszeichen_3 0 "kein_Verkehrszeichen" ;
VAL_ 2463978663 VZE_Warnung_Verkehrszeichen_1 0 "keine_Warnung_Initialwert_Fehlerwert" 1 "Warnung" ;
VAL_ 2463978663 VZE_Warnung_Verkehrszeichen_2 0 "keine_Warnung_Initialwert_Fehlerwert" 1 "Warnung" ;
VAL_ 2463978663 VZE_Warnung_Verkehrszeichen_3 0 "keine_Warnung_Initialwert_Fehlerwert" 1 "Warnung" ;
VAL_ 2463978663 VZE_Zusatzschild_1 0 "keine_Zusatzschild_Initialwert_Fehlerwert" ;
VAL_ 2463978663 VZE_Zusatzschild_2 0 "keine_Zusatzschild_Initialwert_Fehlerwert" ;
VAL_ 2463978663 VZE_Zusatzschild_3 0 "keine_Zusatzschild_Initialwert_Fehlerwert" ;
VAL_ 2463978663 VZE_Anzeigeunterdrueck_Zeichen_1 0 "anzeigerelevant" 1 "nicht_anzeigerelevant" ;
VAL_ 2463978663 VZE_Zeichen_01_KameraWied 0 "inaktiv" 1 "aktiv" ;
VAL_ 2463978663 VZE_Zeichen_02_KameraWied 0 "inaktiv" 1 "aktiv" ;
VAL_ 2463978663 VZE_Zeichen_03_KameraWied 0 "inaktiv" 1 "aktiv" ;
VAL_ 2463978663 VZE_Zeichen_01_Kamera 0 "nicht_erkannt" 1 "erkannt" ;
VAL_ 2463978663 VZE_Zeichen_01_Karte 0 "inaktiv" 1 "aktiv" ;
VAL_ 2463978663 VZE_Zeichen_01_Gesetz 0 "nicht_erkannt" 1 "erkannt" ;
VAL_ 2463978663 VZE_Zeichen_02_Kamera 0 "nicht_erkannt" 1 "erkannt" ;
VAL_ 2463978663 VZE_Zeichen_02_Karte 0 "inaktiv" 1 "aktiv" ;
VAL_ 2463978663 VZE_Zeichen_02_Gesetz 0 "nicht_erkannt" 1 "erkannt" ;
VAL_ 2463978663 VZE_Zeichen_03_Kamera 0 "nicht_erkannt" 1 "erkannt" ;
VAL_ 2463978663 VZE_Zeichen_03_Karte 0 "inaktiv" 1 "aktiv" ;
VAL_ 2463978663 VZE_Zeichen_03_Gesetz 0 "nicht_erkannt" 1 "erkannt" ;
VAL_ 2463978663 VZE_Gong 0 "Gong_deaktiv" 1 "Gong_aktiv" ;
VAL_ 2463978663 VZE_Akustik_Limitwechsel_Status 0 "keine_akustische_Signalisierung" 1 "akustische_Signalisierung_an" ;
VAL_ 2463978663 VZE_SLWF_Status 0 "Init" 1 "aktiv" 2 "deaktiv" ;
VAL_ 2463978663 VZE_Anzeigeunterdrueck_Zeichen_5 0 "anzeigerelevant" 1 "nicht_anzeigerelevant" ;
VAL_ 2463978663 VZE_Zeichen_05_KameraWied 0 "inaktiv" 1 "aktiv" ;
VAL_ 2463978663 VZE_Zeichen_05_Kamera 0 "nicht_erkannt" 1 "erkannt" ;
VAL_ 2463978663 VZE_Verkehrszeichen_4 0 "kein_Verkehrszeichen" ;
VAL_ 2463978663 VZE_Verkehrszeichen_5 0 "kein_Verkehrszeichen" ;
VAL_ 2463978663 VZE_Anhaenger_Vmax 14 "Init" 15 "Fehler" ;
VAL_ 2463978663 VZE_Zeichen_04_Gesetz 0 "nicht_erkannt" 1 "erkannt" ;
VAL_ 2463978663 VZE_Zeichen_04_Kamera 0 "nicht_erkannt" 1 "erkannt" ;
VAL_ 2463978663 VZE_Zeichen_04_KameraWied 0 "inaktiv" 1 "aktiv" ;
VAL_ 2463978663 VZE_Zeichen_04_Karte 0 "inaktiv" 1 "aktiv" ;
VAL_ 2463978663 VZE_Warnung_Verkehrszeichen_4 0 "keine_Warnung_Initialwert_Fehlerwert" 1 "Warnung" ;
VAL_ 2463978663 VZE_Warnung_Verkehrszeichen_5 0 "keine_Warnung_Initialwert_Fehlerwert" 1 "Warnung" ;
VAL_ 2463978663 VZE_Zeichen_05_Gesetz 0 "nicht_erkannt" 1 "erkannt" ;
VAL_ 2463978663 VZE_Zusatzschild_4 0 "keine_Zusatzschild_Initialwert_Fehlerwert" ;
VAL_ 2463978663 VZE_Zusatzschild_5 0 "keine_Zusatzschild_Initialwert_Fehlerwert" ;
VAL_ 2463978663 VZE_Baustelle 0 "Keine_Baustelle" 1 "Baustelle_erkannt" ;
VAL_ 2463978663 VZE_Zeichen_05_Karte 0 "inaktiv" 1 "aktiv" ;
VAL_ 2463978663 VZE_Zeichen_05_Entfernung 0 "Init" ;
VAL_ 2463978663 VZE_Zeichen_05_Entfernung_StdA 0 "Init" ;
VAL_ 2463978663 VZE_Anzeigeunterdrueck_Zeichen_4 0 "anzeigerelevant" 1 "nicht_anzeigerelevant" ;
VAL_ 2463978663 VZE_Verkehrszeichen_6 0 "kein_Verkehrszeichen" ;
VAL_ 2463978663 VZE_Zusatzschild_6 0 "keine_Zusatzschild_Initialwert_Fehlerwert" ;
VAL_ 2463978663 VZE_Zeichen_06_Entfernung 0 "Init" ;
VAL_ 2463978663 VZE_Zeichen_06_Entfernung_StdA 0 "Init" ;
VAL_ 2463978663 VZE_Umweltinfo_Naesse 0 "inaktiv" 1 "aktiv" ;
VAL_ 2463978663 VZE_Umweltinfo_Nebel 0 "inaktiv" 1 "aktiv" ;
VAL_ 2463978663 VZE_Umweltinfo_Anhaengerbetrieb 0 "inaktiv" 1 "aktiv" ;
VAL_ 2463978663 VZE_Erweiterte_Information 0 "keine_Information" ;
VAL_ 2463978663 VZE_Tempowarnung_Status 0 "inaktiv" 1 "aktiv" ;
VAL_ 2463978663 VZE_Tempowarnung_Einheit 0 "kmh" 1 "mph" ;
VAL_ 2463978663 VZE_Tempowarnung_Offset 0 "Init" ;
VAL_ 2463978663 VZE_FoD_Status 0 "Init" 1 "Funktion_inaktiv" 2 "Funktion_aktiv" ;
VAL_ 2463978663 VZE_Anzeige_ZS_1 0 "Init" ;
VAL_ 2463978663 VZE_Anzeige_ZS_2 0 "Init" ;
VAL_ 2463978663 VZE_Anzeige_ZS_3 0 "Init" ;
VAL_ 2463978663 VZE_Hinweistext_03 0 "kein_Hinweistext" ;
VAL_ 2463978663 VZE_Land 0 "Init" ;
VAL_ 2463978663 VZE_Warnung_VZ_1 0 "keine_Warnung" 1 "Warnung" ;
VAL_ 2463978663 VZE_Warnung_VZ_2 0 "keine_Warnung" 1 "Warnung" ;
VAL_ 2463978663 VZE_Warnung_VZ_3 0 "keine_Warnung" 1 "Warnung" ;
VAL_ 2463978663 VZE_Anzeige_VZ_1 0 "kein_Verkehrszeichen" ;
VAL_ 2463978663 VZE_Anzeige_VZ_2 0 "kein_Verkehrszeichen" ;
VAL_ 2463978663 VZE_Anzeige_VZ_3 0 "kein_Verkehrszeichen" ;
VAL_ 2463978954 VZE_relevant_Stopp 0 "Init_kein_Stoppschild_relevant" 1 "Stoppschild_relevant" 2 "Reserved" 3 "Fehler" ;
VAL_ 2463978954 VZE_Ampel_Datenbasis_REM 0 "false" 1 "true" ;
VAL_ 2463978954 VZE_Ampel_Datenbasis_Vision 0 "false" 1 "true" ;
VAL_ 2463978954 VZE_relevant_Stopp_Abstand 511 "Keine_Stoppschilder_relevant" ;
VAL_ 2463978954 VZE_relevante_Ampel_Abstand 511 "Keine_Ampel_relevant" ;
VAL_ 2463978954 VZE_relevante_Ampel 0 "Init_keine_Ampel_relevant" 1 "rot" 2 "gelb" 3 "gruen" 4 "gelb_blinkend" 5 "aus" ;
VAL_ 1361 WFS_Schluessel_Fahrberecht 0 "kein authorisierter Schluessel erkannt" 1 "aktive_Funkschluessel_Nr_01" 2 "aktive_Funkschluessel_Nr_02" 3 "aktive_Funkschluessel_Nr_03" 4 "aktive_Funkschluessel_Nr_04" 5 "aktive_Funkschluessel_Nr_05" 6 "aktive_Funkschluessel_Nr_06" 7 "aktive_Funkschluessel_Nr_07" 8 "aktive_Funkschluessel_Nr_08" 9 "ungueltig_09" 10 "ungueltig_10" 11 "ungueltig_11" 12 "ungueltig_12" 13 "ungueltig_13" 14 "ungueltig_14" 15 "digitaler_Schluessel_aktiv" ;
VAL_ 1361 WFS_Verbauinfo_ELV 0 "ELV_nicht_verbaut" 1 "ELV_verbaut" ;
VAL_ 1361 WFS_ID_Geb_autorisiert 0 "Schluessel_nicht_authorisiert" 1 "Schluessel_authorisiert" ;
VAL_ 1361 WFS_ID_Geb_autorisiert_in_Kl15 0 "nicht_authorisiert_in_Kl15" 1 "authorisiert_in_Kl15" ;
VAL_ 1361 WFS_ID_Geb_steckt 0 "kein_Schluessel_im_Zuendschloss" 1 " Schluessel steckt im Zuendschloss" ;
VAL_ 1361 WFS_Safe 0 "Init" 1 "WFS nicht deaktiviert" ;
VAL_ 1361 WFS_LZ 0 "nicht def." 1 "LZ 1" 2 "LZ 2" 3 "LZ 3" ;
VAL_ 1361 WFS_ELV_authorisiert 0 "ELV_nicht_authorisiert" 1 "ELV_authorisiert" ;
VAL_ 1361 WFS_LF_Aktiv 0 "Funktempfang_nicht_aktiv" 1 "LF_Funkempfang_aktiv" ;
VAL_ 1361 WFS_Betrieb_Lesespule 0 "keine_Schluesselkomm_Lesespule" 1 "Schluesselkomm_Lesespule" ;
VAL_ 1361 WFS_Klemmenfreigabe 0 "keine_Freigabe" 1 "Freigabe" ;
VAL_ 1361 WFS_Fahrerhinweise 0 "Keine_Anzeigeanforderung" 1 "Schuessel_Auth_niO" 2 "Notlauf_aktiv" 3 "Schluessel_Kessy_nicht_gefunden" ;
VAL_ 1361 WFS_Parken_Status 0 "Limitierung_inaktiv" 1 "Limitierung_aktiv" 2 "Abbruch" ;
VAL_ 1361 WFS_LZ_02 0 "Lieferant/Init" 1 "fabrikneu" 2 "angelernt" 3 "Schluessel_lernen_Kundendienst" 4 "Schluessel_lernen_Produktion" 8 "WFS_temporaer_nicht_verfuegbar" 9 "Fehler" ;
VAL_ 1702 Wischer_vorne_aktiv 0 "Init" 1 "Wischer_vorne_laeuft" ;
VAL_ 1702 Waschen_vorne_aktiv 0 "inaktiv" 1 "Waschen_aktiv" ;
VAL_ 1702 Wischer_vorne_Normal 1 "Wischer Front normal aktiv" ;
VAL_ 1702 Wischer_vorne_Schnell 1 "Wischer vorne schnell aktiv" ;
VAL_ 1702 Wischer_vorne_Parklage 0 "Wischer_Front_nicht_in_Parklage" 1 "Wischer_Front_in_Parklage__Initialzustand" ;
VAL_ 1702 WWSs_01_alt 0 "aktuell" 1 "veraltet" ;
VAL_ 1702 Wischer_vorne_defekt 0 "Init" 1 "Wischer vorne defekt" ;
VAL_ 1702 Wischer_vorne_blockiert 1 "Wischer vorne blockiert" ;
VAL_ 1702 Wischer1_Wischgeschwindigkeit 0 "0 U/min" 62 "Init" 63 "Fehler" ;
VAL_ 1702 BCM1_SRA_aktiv 0 "nicht aktiv" 1 "aktiv" ;
VAL_ 1702 Wischer_Anzeigetext 0 "keine_Anzeige" 1 "Hinweis_Service_Position" 2 "void" 3 "void" ;
VAL_ 1702 Wischer_WH_Typ 0 "Lenkstockschalter_0_Int_Stufen" 1 "Lenkstockschalter_2_Int_Stufen" 2 "Lenkstockschalter_4_Int_Stufen" ;
VAL_ 1702 Wischer_WH_PopUp_Anf 0 "keine_Anzeige" 1 "Intervallstufe_1_aktiv" 2 "Intervallstufe_2_aktiv" 3 "Intervallstufe_3_aktiv" 4 "Intervallstufe_4_aktiv" 5 "Regensensorstufe_1_aktiv" 6 "Regensensorstufe_2_aktiv" 7 "Regensensorstufe_3_aktiv" 8 "Regensensorstufe_4_aktiv" 9 "Wischerstufe_1_aktiv" 10 "Wischerstufe_2_aktiv" 11 "Tippwischen_aktiv" 12 "Heckwischen_aktiv" ;
VAL_ 1411 ZV_verriegeln_Anf 0 "nicht_betaetigt" 1 "betaetigt" ;
VAL_ 1411 ZV_STSG_HFS_Anf 0 "keine_Anforderung" 1 "Anforderung" ;
VAL_ 1411 ZV_STSG_HBFS_Anf 0 "keine_Anforderung" 1 "Anforderung" ;
VAL_ 1411 ZV_Anf_Challenge_Auth 0 "nicht_aktiv" 1 "aktiv" ;
VAL_ 1411 ZV_eRWK_Umfeld_Pruefung 0 "nicht_aktiv" 1 "aktiv" ;
VAL_ 1411 VIP_Sensor_STSG_HFS_betaetigt 0 "keine_VIP_Anforderung_STSG_HFS" 1 "VIP_Anforderung_STSG_HFS" ;
VAL_ 1411 VIP_Sensor_STSG_HBFS_betaetigt 0 "keine_VIP_Anforderung_STSG_HBFS" 1 "VIP_Anforderung_STSG_HBFS" ;
VAL_ 1411 BCM_FH_Freigabe 1 "Funktionsfreigabe Fensterheber" ;
VAL_ 1411 BCM_Komfortfkt_Freigabe 0 "Komfortfunktion gesperrt" 1 "globale Freigabe der Komfortfunktion erteilt" ;
VAL_ 1411 BCM_HSK_Freigabe 0 "erlauben" 1 "sperren" ;
VAL_ 1411 BCM_Verdeck_Freigabe 0 "Verdeckbetrieb nicht erlaubt" 1 "Verdeckbetrieb erlaubt" ;
VAL_ 1411 ZV_verriegelt_intern_ist 1 "Fahrzeug innen verriegelt; Istzustand" ;
VAL_ 1411 ZV_verriegelt_extern_ist 1 "Fahrzeug_aussen_verriegelt_Istzustand" ;
VAL_ 1411 ZV_verriegelt_intern_soll 1 "Fahrzeug verriegelt intern; Sollzusstand" ;
VAL_ 1411 ZV_verriegelt_extern_soll 1 "Fahrzeug verriegelt extern; Sollzusstand" ;
VAL_ 1411 ZV_gesafet_extern_ist 1 "Fahrzeug aussen gesafet; Istzustand" ;
VAL_ 1411 ZV_gesafet_extern_soll 1 "Fahrzeug_aussen_gesafet_Sollzustand" ;
VAL_ 1411 ZV_Einzeltuerentriegelung 1 "Fahrzeug an Einzeltuer entriegelt" ;
VAL_ 1411 ZV_Heckeinzelentriegelung 1 "Heckdeckeleinzelentriegelung" ;
VAL_ 1411 ZV_FT_offen 0 "FT_geschlossen" 1 "FT_geoeffnet" ;
VAL_ 1411 ZV_BT_offen 0 "BT_geschlossen" 1 "BT_geoeffnet" ;
VAL_ 1411 ZV_HFS_offen 0 "geschlossen" 1 "offen" ;
VAL_ 1411 ZV_HBFS_offen 0 "geschlossen" 1 "offen" ;
VAL_ 1411 ZV_HD_offen 1 "Heckdeckel_auf" ;
VAL_ 1411 ZV_HS_offen 0 "Heckscheibe_geschlossen" 1 "Heckscheibe auf" ;
VAL_ 1411 IRUE_aktiv 0 "unscharf" 1 "scharf" ;
VAL_ 1411 DWA_aktiv 0 "unscharf" 1 "scharf" ;
VAL_ 1411 FFB_HDF_Taste 0 "Taste_nicht_betaetigt" 1 "HDF_Taste_am_Funkschluessel_betaetigt" ;
VAL_ 1411 FFB_Panik_Taste 0 "Taste_nicht_betaetigt" 1 "Panik_Taste_am_Funkschluessel_betaetigt" ;
VAL_ 1411 FFB_Auf_Taste 0 "Taste_nicht_betaetigt" 1 "Oeffnentaste_betaetigt" ;
VAL_ 1411 FFB_Zu_Taste 0 "Taste_nicht_betaetigt" 1 "Zu_Taste_am_Funkschluessel_betaetigt" ;
VAL_ 1411 FFB_CarFinder 0 "nicht aktiv" 1 "aktiv" ;
VAL_ 1411 FFB_Komfortoeffnen 0 "kein_Komfortoeffnen_empfangen" 1 "Komfortoeffnen ueber Funk empfangen" ;
VAL_ 1411 FFB_Komfortschliessen 0 "kein_Komfortschliessen_empfangen" 1 "Komfortschliessen ueber Funk empfangen" ;
VAL_ 1411 FBS_IDG_in_Reichweite 0 "ausser_Reichweite_bzw_nicht_ermittelbar" 1 "innerhalb_Reichweite" ;
VAL_ 1411 ZV_Schluessel_Zugang 0 "kein_auth_Schluessel_erkannt" 1 "aktive_Funkschluessel_Nr_01" 2 "aktive_Funkschluessel_Nr_02" 3 "aktive_Funkschluessel_Nr_03" 4 "aktive_Funkschluessel_Nr_04" 5 "aktive_Funkschluessel_Nr_05" 6 "aktive_Funkschluessel_Nr_06" 7 "aktive_Funkschluessel_Nr_07" 8 "aktive_Funkschluessel_Nr_08" 9 "aktive_SmartDevice_Nr_09" 10 "ungueltig_10" 11 "ungueltig_11" 12 "ungueltig_12" 13 "ungueltig_13" 14 "ungueltig_14" 15 "ungueltig_15" ;
VAL_ 1411 ZV_SafeFunktion_aktiv 0 "inaktiv" 1 "aktiv" ;
VAL_ 1411 FBS_Warn_Schluessel_Batt 0 "i.O." 1 "defekt" ;
VAL_ 1411 ZV_Oeffnungsmodus 0 "globale_Oeffnung" 1 "ZV_mit_Einzeltuerentr" 2 "ZV_individuell_selektiv" 3 "ZV_seitenselektiv" ;
VAL_ 1411 ZV_ist_Zustand_verfuegbar 0 "nicht_verfuegbar" 1 "verfuegbar_alle_TSGs_am_Bus" ;
VAL_ 1411 IRUE_Taster_Fkts_LED 0 "LED_aus" 1 "LED_ein" ;
VAL_ 1411 ZV_Tankklappe_offen 0 "Tankklappe_geschlossen" 1 "Tankklappe_offen" ;
VAL_ 1411 ZV_Rollo_auf 0 "inaktiv" 1 "aktiv" ;
VAL_ 1411 ZV_Rollo_zu 0 "inaktiv" 1 "aktiv" ;
VAL_ 1411 ZV_SAD_auf 0 "inaktiv" 1 "aktiv" ;
VAL_ 1411 ZV_SAD_zu 0 "inaktiv" 1 "aktiv" ;
VAL_ 1411 ZV_verriegelt_soll 0 "Init" 1 "nicht_verriegelt" 2 "verriegelt" ;
